VERSION ""

NS_ :

BS_:

BU_: BCM BMS_12V CMS_D CMS_P DSMU ECDO METER MID PBD PSB_D PSB_P PSCU RSCU2R RSCU3R SCCM SRVM VSP

BO_ 1526 HEVC_R110: 8 BCM
  SG_ ME_ElecMachineTempDeg_BLMS : 23|8@0+ (1,-40) [-40|210] "°C" METER
  SG_ ME_InverterTempDeg_BLMS : 31|8@0+ (1,-40) [-40|210] "°C" METER

BO_ 1530 METER_UserSetPref_A3: 8 METER
  SG_ BSWson_ActivationRequest : 5|2@0+ (1,0) [0|0] "" BCM
  SG_ BCI_ActivationRequest : 7|2@0+ (1,0) [0|0] "" BCM
  SG_ HUD_TurnByTurnActivationRequest : 9|2@0+ (1,0) [0|0] "" BCM
  SG_ HUD_ADASactivationRequest : 11|2@0+ (1,0) [0|0] "" BCM
  SG_ HUD_TSRactivationRequest : 13|2@0+ (1,0) [0|0] "" BCM
  SG_ HUD_ITactivationRequest : 15|2@0+ (1,0) [0|0] "" BCM
  SG_ ELKA_ActivationRequest : 18|2@0+ (1,0) [0|0] "" BCM
  SG_ FCW_SensibilityRequest : 26|3@0+ (1,0) [0|0] "" BCM
  SG_ HUD_DayLuminosityRequest : 31|5@0+ (1,0) [0|0] "" BCM
  SG_ SSAactivationRequest : 34|3@0+ (1,0) [0|0] "" BCM
  SG_ HUD_NightLuminosityRequest : 39|5@0+ (1,0) [0|0] "" BCM
  SG_ EAP_ActivationRequest : 41|2@0+ (1,0) [0|0] "" BCM
  SG_ WDA_ActivationRequest : 43|2@0+ (1,0) [0|0] "" BCM
  SG_ ASAactivationRequest : 45|2@0+ (1,0) [0|0] "" BCM
  SG_ ADA1ActivationRequest : 47|2@0+ (1,0) [0|0] "" BCM
  SG_ WAL_ActivationRequest : 49|2@0+ (1,0) [0|0] "" BCM
  SG_ RAB_ActivationRequest : 51|2@0+ (1,0) [0|0] "" BCM
  SG_ NoEntry_ActivationRequest : 53|2@0+ (1,0) [0|0] "" BCM
  SG_ VDCactivationRequest : 55|2@0+ (1,0) [0|0] "" BCM
  SG_ APPRUN_ActivationRequest : 63|2@0+ (1,0) [0|0] "" BCM

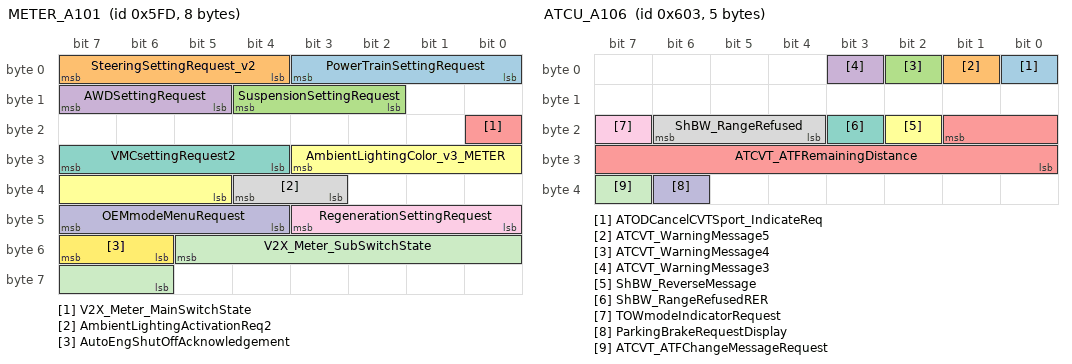
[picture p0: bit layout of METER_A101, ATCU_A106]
BO_ 1533 METER_A101: 8 METER
  SG_ PowerTrainSettingRequest : 3|4@0+ (1,0) [0|0] "" BCM
  SG_ SteeringSettingRequest_v2 : 7|4@0+ (1,0) [0|0] "" BCM
  SG_ SuspensionSettingRequest : 12|3@0+ (1,0) [0|0] "" BCM
  SG_ AWDSettingRequest : 15|3@0+ (1,0) [0|0] "" BCM
  SG_ V2X_Meter_MainSwitchState : 16|1@0+ (1,0) [0|0] "" BCM
  SG_ AmbientLightingColor_v3_METER : 27|7@0+ (1,0) [0|0] "" BCM
  SG_ VMCsettingRequest2 : 31|4@0+ (1,0) [0|0] "" BCM
  SG_ AmbientLightingActivationReq2 : 36|2@0+ (1,0) [0|0] "" BCM
  SG_ RegenerationSettingRequest : 43|4@0+ (1,0) [0|0] "" BCM
  SG_ OEMmodeMenuRequest : 47|4@0+ (1,0) [0|0] "" BCM
  SG_ V2X_Meter_SubSwitchState : 53|8@0+ (1,0) [0|0] "" BCM
  SG_ AutoEngShutOffAcknowledgement : 55|2@0+ (1,0) [0|0] "" BCM

BO_ 1537 ADAS_A119: 8 BCM
  SG_ NoEntry_AlertDisplay : 2|1@0+ (1,0) [0|0] "" METER
  SG_ NoEntry_ActivationState : 3|1@0+ (1,0) [0|0] "" METER
  SG_ ADAS_ModeDisplay : 7|2@0+ (1,0) [0|0] "" METER
  SG_ NoEntry_Alert : 8|1@0+ (1,0) [0|0] "" METER
  SG_ ACC_TargetDistanceAlert : 10|2@0+ (1,0) [0|0] "" METER
  SG_ ACC_DistanceOverrideDisplay : 11|1@0+ (1,0) [0|0] "" METER
  SG_ ACC_SpeedOverrideDisplay : 12|1@0+ (1,0) [0|0] "" METER
  SG_ ACC_TargetDistanceDisplay : 15|3@0+ (1,0) [0|0] "" METER
  SG_ ACC_DynTargetDistanceDisplay : 23|8@0+ (1,0) [0|255] "wu" METER
  SG_ ACC_SpeedSettingDisplay : 31|8@0+ (1,0) [0|255] "wu" METER
  SG_ ACC_DistanceSettingDisplay : 39|3@0+ (1,0) [0|0] "" METER
  SG_ LCA_FailureDisplay : 41|2@0+ (1,0) [0|0] "" METER
  SG_ LCA_OverrideDisplay : 42|1@0+ (1,0) [0|0] "" METER
  SG_ LCA_SteeringWheelDisplay : 46|2@0+ (1,0) [0|0] "" METER
  SG_ LCA_ActivationState : 47|1@0+ (1,0) [0|0] "" METER
  SG_ LDP_StatusDisplay : 49|2@0+ (1,0) [0|0] "" METER
  SG_ LDP_LaneDisplay : 51|2@0+ (1,0) [0|0] "" METER
  SG_ LDP_AlertStatus : 54|2@0+ (1,0) [0|0] "" METER
  SG_ LCA_SoundAlert : 55|1@0+ (1,0) [0|0] "" METER
  SG_ ContextSpeed_ActivationState : 58|2@0+ (1,0) [0|0] "" METER
  SG_ ContextRoad_ActivationState : 60|2@0+ (1,0) [0|0] "" METER
  SG_ DriverGuideDisplay : 63|3@0+ (1,0) [0|0] "" METER

BO_ 1538 ADAS_A120: 8 BCM
  SG_ BCI_AlertStatus_v2 : 0|1@0+ (1,0) [0|0] "" METER
  SG_ BSI_SideDisplay : 8|1@0+ (1,0) [0|0] "" METER
  SG_ BCI_SoundAlert : 9|1@0+ (1,0) [0|0] "" METER
  SG_ BCI_OffdisplayRequest : 10|1@0+ (1,0) [0|0] "" METER
  SG_ BCI_FailureDisplay : 12|2@0+ (1,0) [0|0] "" METER
  SG_ BSI_CancelReason : 18|3@0+ (1,0) [0|0] "" METER
  SG_ LKA_OvertimeAlert : 19|1@0+ (1,0) [0|0] "" METER
  SG_ LDW_AlertStatus : 21|2@0+ (1,0) [0|0] "" METER
  SG_ BSI_AlertStatus : 23|2@0+ (1,0) [0|0] "" METER
  SG_ EAP_FailureDisplay : 25|2@0+ (1,0) [0|0] "" METER
  SG_ EAP_AlertDisplay : 26|1@0+ (1,0) [0|0] "" METER
  SG_ BSI_StatusDisplay : 28|2@0+ (1,0) [0|0] "" METER
  SG_ BSI_SideRadarCancelReason : 31|2@0+ (1,0) [0|0] "" METER
  SG_ LDP_CancelReason : 35|3@0+ (1,0) [0|0] "" METER
  SG_ LCA_LineCrossingAlert : 39|2@0+ (1,0) [0|0] "" METER
  SG_ RAB_CancelReason : 42|3@0+ (1,0) [0|0] "" METER
  SG_ RAB_AlertStatus : 44|2@0+ (1,0) [0|0] "" METER
  SG_ RAB_ActivationState : 45|1@0+ (1,0) [0|0] "" METER
  SG_ LDP_FailureDisplay : 47|2@0+ (1,0) [0|0] "" METER
  SG_ WDA_WarningDriverAttention : 48|1@0+ (1,0) [0|0] "" METER
  SG_ WDA_ActivationState : 49|1@0+ (1,0) [0|0] "" METER
  SG_ RAB_StatusDisplay : 51|2@0+ (1,0) [0|0] "" METER
  SG_ RAB_SonarCancelReason : 53|2@0+ (1,0) [0|0] "" METER
  SG_ RAB_FailureDisplay : 55|2@0+ (1,0) [0|0] "" METER
  SG_ ACC_TransitionStateDisplay : 59|4@0+ (1,0) [0|0] "" METER
  SG_ WDA_DriverAttentionLevel : 63|4@0+ (1,0) [0|0] "" METER

BO_ 1539 ATCU_A106: 5 BCM
  SG_ ATODCancelCVTSport_IndicateReq : 0|1@0+ (1,0) [0|0] "" METER
  SG_ ATCVT_WarningMessage5 : 1|1@0+ (1,0) [0|0] "" METER
  SG_ ATCVT_WarningMessage4 : 2|1@0+ (1,0) [0|0] "" METER
  SG_ ATCVT_WarningMessage3 : 3|1@0+ (1,0) [0|0] "" METER
  SG_ ATCVT_ATFRemainingDistance : 17|10@0+ (5,0) [0|5110] "km" METER
  SG_ ShBW_ReverseMessage : 18|1@0+ (1,0) [0|0] "" METER
  SG_ ShBW_RangeRefusedRER : 19|1@0+ (1,0) [0|0] "" METER
  SG_ ShBW_RangeRefused : 22|3@0+ (1,0) [0|0] "" METER
  SG_ TOWmodeIndicatorRequest : 23|1@0+ (1,0) [0|0] "" METER
  SG_ ParkingBrakeRequestDisplay : 38|1@0+ (1,0) [0|0] "" METER
  SG_ ATCVT_ATFChangeMessageRequest : 39|1@0+ (1,0) [0|0] "" METER

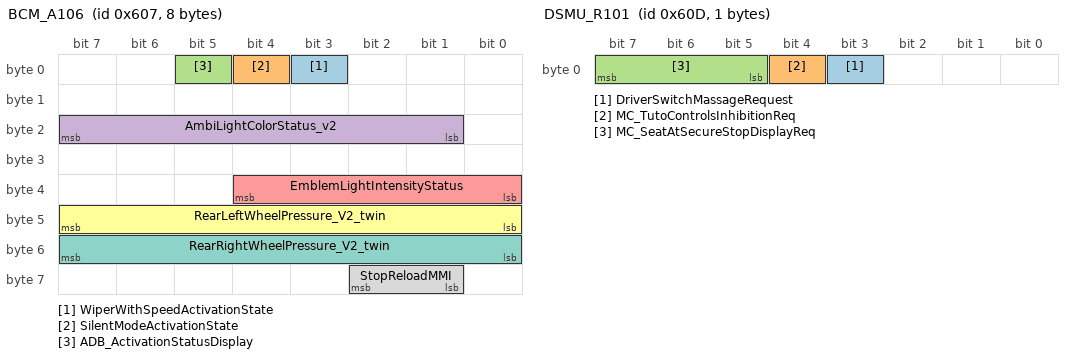
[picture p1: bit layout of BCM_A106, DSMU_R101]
BO_ 1543 BCM_A106: 8 BCM
  SG_ WiperWithSpeedActivationState : 3|1@0+ (1,0) [0|0] "" METER
  SG_ SilentModeActivationState : 4|1@0+ (1,0) [0|0] "" METER,PBD
  SG_ ADB_ActivationStatusDisplay : 5|1@0+ (1,0) [0|0] "" METER
  SG_ AmbiLightColorStatus_v2 : 23|7@0+ (1,0) [0|0] "" METER
  SG_ EmblemLightIntensityStatus : 36|5@0+ (5,0) [0|100] "%" METER
  SG_ RearLeftWheelPressure_V2_twin : 47|8@0+ (30,0) [0|7620] "mbar" METER
  SG_ RearRightWheelPressure_V2_twin : 55|8@0+ (30,0) [0|7620] "mbar" METER
  SG_ StopReloadMMI : 58|2@0+ (1,0) [0|0] "" METER

BO_ 1548 EVAP_A2: 5 BCM
  SG_ FuelLidStatus : 1|1@0+ (1,0) [0|0] "" METER
  SG_ RefuelingDisplay : 36|3@0+ (1,0) [0|0] "" METER

BO_ 1549 DSMU_R101: 1 DSMU
  SG_ DriverSwitchMassageRequest : 3|1@0+ (1,0) [0|0] "" BCM
  SG_ MC_TutoControlsInhibitionReq : 4|1@0+ (1,0) [0|0] "" BCM
  SG_ MC_SeatAtSecureStopDisplayReq : 7|3@0+ (1,0) [0|0] "" BCM

BO_ 1553 HVAC_A106: 8 BCM
  SG_ ClimEVmodeAdviceForHeating : 5|3@0+ (1,0) [0|0] "" METER

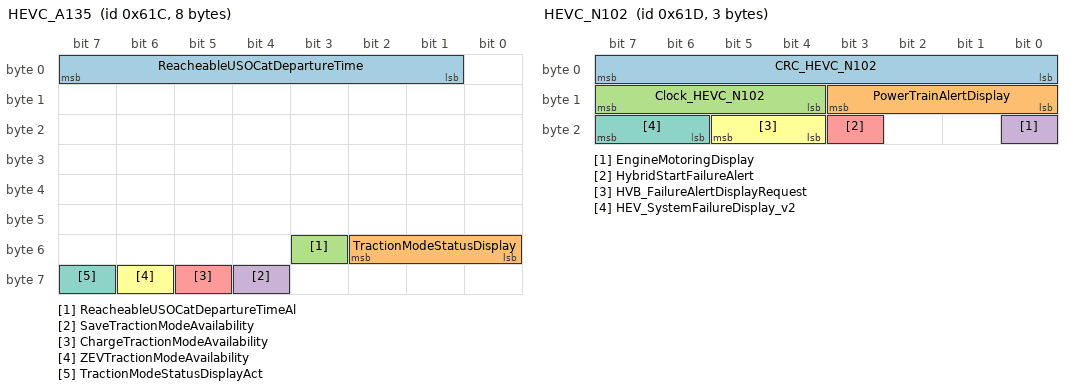
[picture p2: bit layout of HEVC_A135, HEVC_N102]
BO_ 1564 HEVC_A135: 8 BCM
  SG_ ReacheableUSOCatDepartureTime : 7|7@0+ (1,0) [0|100] "%" METER
  SG_ TractionModeStatusDisplay : 50|3@0+ (1,0) [0|0] "" METER
  SG_ ReacheableUSOCatDepartureTimeAl : 51|1@0+ (1,0) [0|0] "" METER
  SG_ SaveTractionModeAvailability : 60|1@0+ (1,0) [0|0] "" METER
  SG_ ChargeTractionModeAvailability : 61|1@0+ (1,0) [0|0] "" METER
  SG_ ZEVTractionModeAvailability : 62|1@0+ (1,0) [0|0] "" METER
  SG_ TractionModeStatusDisplayAct : 63|1@0+ (1,0) [0|0] "" METER

BO_ 1565 HEVC_N102: 3 BCM
  SG_ CRC_HEVC_N102 : 7|8@0+ (1,0) [0|255] "" METER
  SG_ PowerTrainAlertDisplay : 11|4@0+ (1,0) [0|0] "" METER
  SG_ Clock_HEVC_N102 : 15|4@0+ (1,0) [0|15] "" METER
  SG_ EngineMotoringDisplay : 16|1@0+ (1,0) [0|0] "" METER
  SG_ HybridStartFailureAlert : 19|1@0+ (1,0) [0|0] "" METER
  SG_ HVB_FailureAlertDisplayRequest : 21|2@0+ (1,0) [0|0] "" METER
  SG_ HEV_SystemFailureDisplay_v2 : 23|2@0+ (1,0) [0|0] "" METER

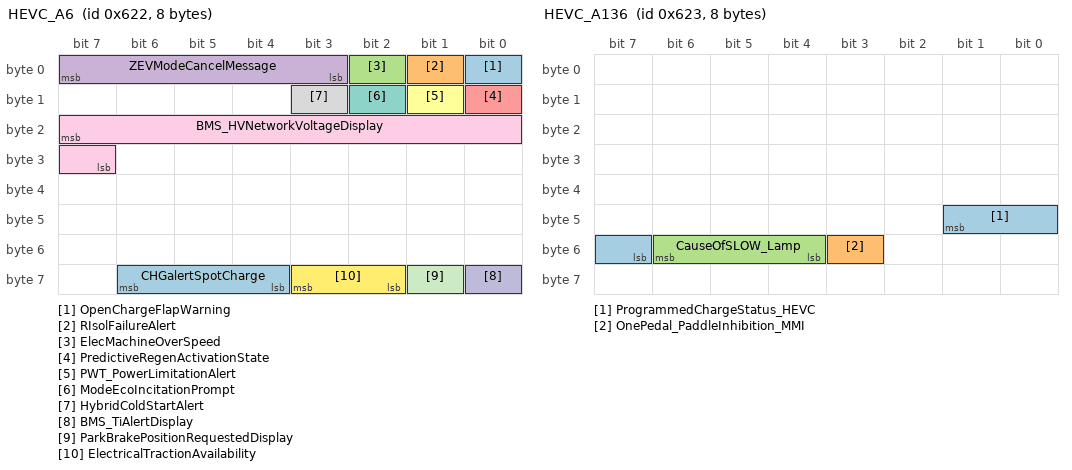
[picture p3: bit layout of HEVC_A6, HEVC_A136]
BO_ 1570 HEVC_A6: 8 BCM
  SG_ OpenChargeFlapWarning : 0|1@0+ (1,0) [0|0] "" METER
  SG_ RIsolFailureAlert : 1|1@0+ (1,0) [0|0] "" METER
  SG_ ElecMachineOverSpeed : 2|1@0+ (1,0) [0|0] "" METER
  SG_ ZEVModeCancelMessage : 7|5@0+ (1,0) [0|0] "" METER
  SG_ PredictiveRegenActivationState : 8|1@0+ (1,0) [0|0] "" METER
  SG_ PWT_PowerLimitationAlert : 9|1@0+ (1,0) [0|0] "" METER
  SG_ ModeEcoIncitationPrompt : 10|1@0+ (1,0) [0|0] "" METER
  SG_ HybridColdStartAlert : 11|1@0+ (1,0) [0|0] "" METER
  SG_ BMS_HVNetworkVoltageDisplay : 23|9@0+ (1,0) [0|500] "V" METER
  SG_ BMS_TiAlertDisplay : 56|1@0+ (1,0) [0|0] "" METER
  SG_ ParkBrakePositionRequestedDisplay : 57|1@0+ (1,0) [0|0] "" METER
  SG_ ElectricalTractionAvailability : 59|2@0+ (1,0) [0|0] "" METER
  SG_ CHGalertSpotCharge : 62|3@0+ (1,0) [0|0] "" METER

BO_ 1571 HEVC_A136: 8 BCM
  SG_ ProgrammedChargeStatus_HEVC : 41|3@0+ (1,0) [0|0] "" METER
  SG_ OnePedal_PaddleInhibition_MMI : 51|1@0+ (1,0) [0|0] "" METER
  SG_ CauseOfSLOW_Lamp : 54|3@0+ (1,0) [0|0] "" METER

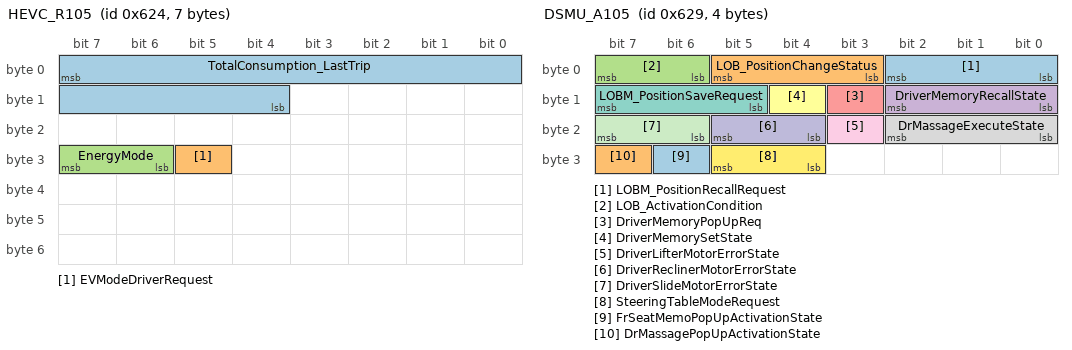
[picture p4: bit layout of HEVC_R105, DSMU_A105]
BO_ 1572 HEVC_R105: 7 BCM
  SG_ TotalConsumption_LastTrip : 7|12@0+ (0.1,0) [0|409.4] "kWh" METER
  SG_ EVModeDriverRequest : 29|1@0+ (1,0) [0|0] "" METER
  SG_ EnergyMode : 31|2@0+ (1,0) [0|0] "" METER

BO_ 1577 DSMU_A105: 4 DSMU
  SG_ LOBM_PositionRecallRequest : 2|3@0+ (1,0) [0|0] "" SCCM
  SG_ LOB_PositionChangeStatus : 5|3@0+ (1,0) [0|0] "" BCM
  SG_ LOB_ActivationCondition : 7|2@0+ (1,0) [0|0] "" BCM
  SG_ DriverMemoryRecallState : 10|3@0+ (1,0) [0|0] "" BCM
  SG_ DriverMemoryPopUpReq : 11|1@0+ (1,0) [0|0] "" BCM
  SG_ DriverMemorySetState : 12|1@0+ (1,0) [0|0] "" BCM
  SG_ LOBM_PositionSaveRequest : 15|3@0+ (1,0) [0|0] "" SCCM
  SG_ DrMassageExecuteState : 18|3@0+ (1,0) [0|0] "" BCM
  SG_ DriverLifterMotorErrorState : 19|1@0+ (1,0) [0|0] "" BCM
  SG_ DriverReclinerMotorErrorState : 21|2@0+ (1,0) [0|0] "" BCM
  SG_ DriverSlideMotorErrorState : 23|2@0+ (1,0) [0|0] "" BCM
  SG_ SteeringTableModeRequest : 29|2@0+ (1,0) [0|0] "" SCCM
  SG_ FrSeatMemoPopUpActivationState : 30|1@0+ (1,0) [0|0] "" BCM,PSCU
  SG_ DrMassagePopUpActivationState : 31|1@0+ (1,0) [0|0] "" BCM

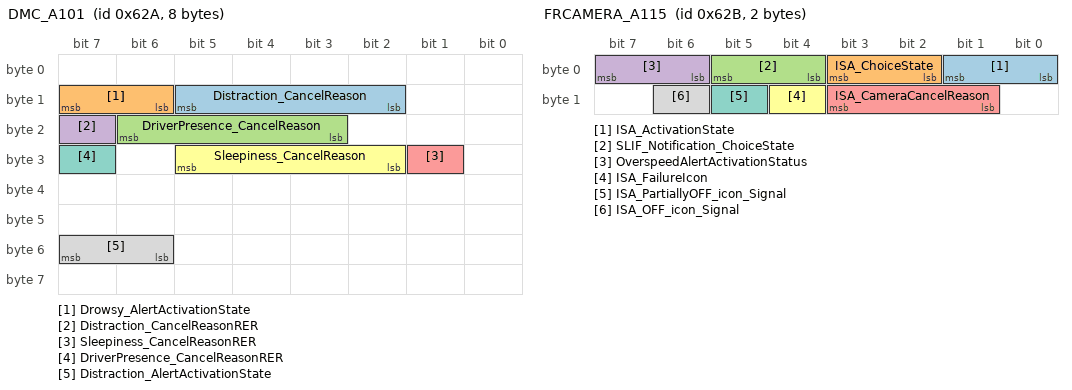
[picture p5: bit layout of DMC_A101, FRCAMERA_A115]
BO_ 1578 DMC_A101: 8 BCM
  SG_ Distraction_CancelReason : 13|4@0+ (1,0) [0|0] "" METER
  SG_ Drowsy_AlertActivationState : 15|2@0+ (1,0) [0|0] "" METER
  SG_ DriverPresence_CancelReason : 22|4@0+ (1,0) [0|0] "" METER
  SG_ Distraction_CancelReasonRER : 23|1@0+ (1,0) [0|0] "" METER
  SG_ Sleepiness_CancelReasonRER : 25|1@0+ (1,0) [0|0] "" METER
  SG_ Sleepiness_CancelReason : 29|4@0+ (1,0) [0|0] "" METER
  SG_ DriverPresence_CancelReasonRER : 31|1@0+ (1,0) [0|0] "" METER
  SG_ Distraction_AlertActivationState : 55|2@0+ (1,0) [0|0] "" METER

BO_ 1579 FRCAMERA_A115: 2 BCM
  SG_ ISA_ActivationState : 1|2@0+ (1,0) [0|0] "" METER
  SG_ ISA_ChoiceState : 3|2@0+ (1,0) [0|0] "" METER
  SG_ SLIF_Notification_ChoiceState : 5|2@0+ (1,0) [0|0] "" METER
  SG_ OverspeedAlertActivationStatus : 7|2@0+ (1,0) [0|0] "" METER
  SG_ ISA_CameraCancelReason : 11|3@0+ (1,0) [0|0] "" METER
  SG_ ISA_FailureIcon : 12|1@0+ (1,0) [0|0] "" METER
  SG_ ISA_PartiallyOFF_icon_Signal : 13|1@0+ (1,0) [0|0] "" METER
  SG_ ISA_OFF_icon_Signal : 14|1@0+ (1,0) [0|0] "" METER

BO_ 1583 ANC_A101: 3 BCM
  SG_ ASE_SoundActivationStatus : 20|2@0+ (1,0) [0|0] "" METER
  SG_ ASE_SoundvolumeState : 23|3@0+ (1,0) [0|0] "" METER

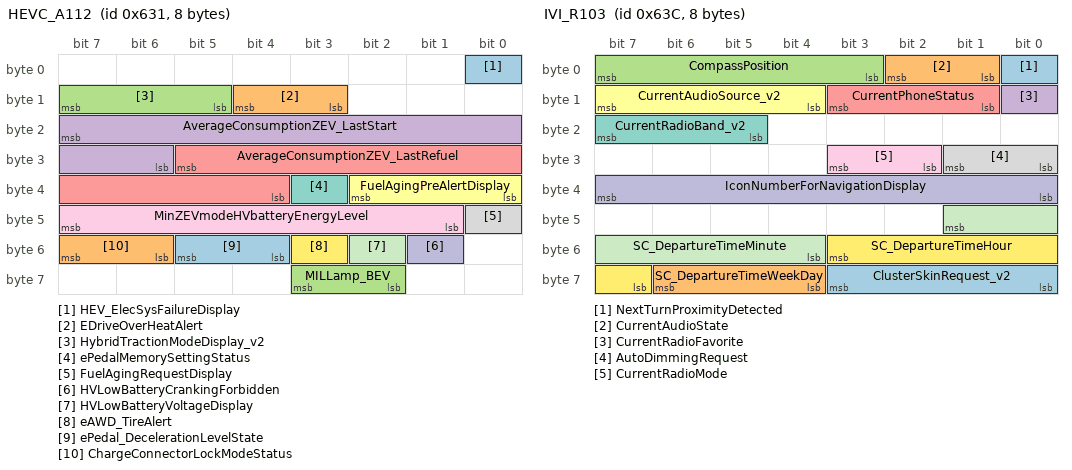
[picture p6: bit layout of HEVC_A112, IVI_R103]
BO_ 1585 HEVC_A112: 8 BCM
  SG_ HEV_ElecSysFailureDisplay : 0|1@0+ (1,0) [0|0] "" METER
  SG_ EDriveOverHeatAlert : 12|2@0+ (1,0) [0|0] "" METER
  SG_ HybridTractionModeDisplay_v2 : 15|3@0+ (1,0) [0|0] "" METER
  SG_ AverageConsumptionZEV_LastStart : 23|10@0+ (0.1,0) [0|102.2] "-" METER
  SG_ AverageConsumptionZEV_LastRefuel : 29|10@0+ (0.1,0) [0|102.2] "" METER
  SG_ FuelAgingPreAlertDisplay : 34|3@0+ (1,0) [0|0] "" METER
  SG_ ePedalMemorySettingStatus : 35|1@0+ (1,0) [0|0] "" METER
  SG_ FuelAgingRequestDisplay : 40|1@0+ (1,0) [0|0] "" METER
  SG_ MinZEVmodeHVbatteryEnergyLevel : 47|7@0+ (1,0) [0|100] "%" METER
  SG_ HVLowBatteryCrankingForbidden : 49|1@0+ (1,0) [0|0] "" METER
  SG_ HVLowBatteryVoltageDisplay : 50|1@0+ (1,0) [0|0] "" METER
  SG_ eAWD_TireAlert : 51|1@0+ (1,0) [0|0] "" METER
  SG_ ePedal_DecelerationLevelState : 53|2@0+ (1,0) [0|0] "" METER
  SG_ ChargeConnectorLockModeStatus : 55|2@0+ (1,0) [0|0] "" METER
  SG_ MILLamp_BEV : 59|2@0+ (1,0) [0|0] "" METER

BO_ 1592 HVAC_A107: 8 BCM
  SG_ eAC_RevCapStatus : 41|2@0+ (1,0) [0|0] "" METER

BO_ 1595 IVI_A114: 8 BCM
  SG_ RearViewRVC_CancelReason_RER : 50|1@0+ (1,0) [0|0] "" METER
  SG_ RearViewRVC_CancelReason : 54|2@0+ (1,0) [0|0] "" METER

BO_ 1596 IVI_R103: 8 BCM
  SG_ NextTurnProximityDetected : 0|1@0+ (1,0) [0|0] "" METER
  SG_ CurrentAudioState : 2|2@0+ (1,0) [0|0] "" METER
  SG_ CompassPosition : 7|5@0+ (1,0) [0|31] "wu" METER
  SG_ CurrentRadioFavorite : 8|1@0+ (1,0) [0|0] "" METER
  SG_ CurrentPhoneStatus : 11|3@0+ (1,0) [0|0] "" METER
  SG_ CurrentAudioSource_v2 : 15|4@0+ (1,0) [0|0] "" METER
  SG_ CurrentRadioBand_v2 : 23|3@0+ (1,0) [0|0] "" METER
  SG_ AutoDimmingRequest : 25|2@0+ (1,0) [0|0] "" METER
  SG_ CurrentRadioMode : 27|2@0+ (1,0) [0|0] "" METER
  SG_ IconNumberForNavigationDisplay : 39|8@0+ (1,0) [0|255] "wu" METER
  SG_ SC_DepartureTimeMinute : 41|6@0+ (1,0) [0|59] "min" METER
  SG_ SC_DepartureTimeHour : 51|5@0+ (1,0) [0|23] "h" METER
  SG_ ClusterSkinRequest_v2 : 59|4@0+ (1,0) [0|0] "" METER
  SG_ SC_DepartureTimeWeekDay : 62|3@0+ (1,0) [0|0] "" METER

BO_ 1599 SRRR_A107: 1 BCM
  SG_ CTA_ActivationState : 7|1@0+ (1,0) [0|0] "" METER

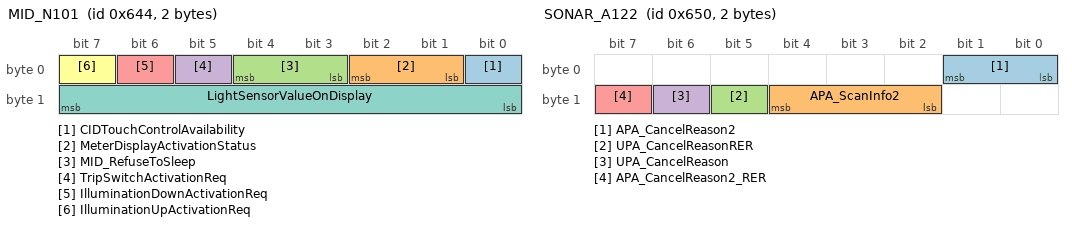
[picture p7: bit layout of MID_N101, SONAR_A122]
BO_ 1604 MID_N101: 2 MID
  SG_ CIDTouchControlAvailability : 0|1@0+ (1,0) [0|0] "" METER
  SG_ MeterDisplayActivationStatus : 2|2@0+ (1,0) [0|0] "" METER
  SG_ MID_RefuseToSleep : 4|2@0+ (1,0) [0|0] "" BCM
  SG_ TripSwitchActivationReq : 5|1@0+ (1,0) [0|0] "" METER
  SG_ IlluminationDownActivationReq : 6|1@0+ (1,0) [0|0] "" METER
  SG_ IlluminationUpActivationReq : 7|1@0+ (1,0) [0|0] "" METER
  SG_ LightSensorValueOnDisplay : 15|8@0+ (0.4,0) [0|100] "%" METER

BO_ 1614 IVI_A129: 8 BCM
  SG_ RearLeftLumbarMovingReq_X_Axis : 8|2@0+ (1,0) [0|0] "" RSCU2R
  SG_ RearLeftFrontHeightMovingReq : 10|2@0+ (1,0) [0|0] "" RSCU2R
  SG_ RearLeftMassageProgramReq : 17|4@0+ (1,0) [0|0] "" RSCU2R
  SG_ RearLeftMassageIntensityReq : 20|3@0+ (1,0) [0|0] "" RSCU2R
  SG_ RearLeftLumbarMovingReq_Z_Axis : 22|2@0+ (1,0) [0|0] "" RSCU2R
  SG_ RearLeftReclinerMovingReq : 24|2@0+ (1,0) [0|0] "" RSCU2R
  SG_ RearLeftOttomanMovingReq : 26|2@0+ (1,0) [0|0] "" RSCU2R
  SG_ RearLeftMassageVelocityReq : 29|3@0+ (1,0) [0|0] "" RSCU2R
  SG_ RearRightLumbarMovingReq_X_Axis : 32|2@0+ (1,0) [0|0] "" RSCU2R
  SG_ RearRightFrontHeightMovingReq : 34|2@0+ (1,0) [0|0] "" RSCU2R
  SG_ RearLeftUpperbackrestMovingReq : 36|2@0+ (1,0) [0|0] "" RSCU2R
  SG_ RearLeftSlideMovingReq : 38|2@0+ (1,0) [0|0] "" RSCU2R
  SG_ RearRightMassageProgramReq : 41|4@0+ (1,0) [0|0] "" RSCU2R
  SG_ RearRightMassageIntensityReq : 44|3@0+ (1,0) [0|0] "" RSCU2R
  SG_ RearRightLumbarMovingReq_Z_Axis : 46|2@0+ (1,0) [0|0] "" RSCU2R
  SG_ RearRightReclinerMovingReq : 48|2@0+ (1,0) [0|0] "" RSCU2R
  SG_ RearRightOttomanMovingReq : 50|2@0+ (1,0) [0|0] "" RSCU2R
  SG_ RearRightMassageVelocityReq : 53|3@0+ (1,0) [0|0] "" RSCU2R
  SG_ RearRightUpperbackrestMovingReq : 60|2@0+ (1,0) [0|0] "" RSCU2R
  SG_ RearRightSlideMovingReq : 62|2@0+ (1,0) [0|0] "" RSCU2R

BO_ 1616 SONAR_A122: 2 BCM
  SG_ APA_CancelReason2 : 1|2@0+ (1,0) [0|0] "" METER
  SG_ APA_ScanInfo2 : 12|3@0+ (1,0) [0|0] "" METER
  SG_ UPA_CancelReasonRER : 13|1@0+ (1,0) [0|0] "" METER
  SG_ UPA_CancelReason : 14|1@0+ (1,0) [0|0] "" METER
  SG_ APA_CancelReason2_RER : 15|1@0+ (1,0) [0|0] "" METER

BO_ 1620 HEVC_A37: 8 BCM
  SG_ FreeDistanceZEVSinceECOreset : 15|13@0+ (0.1,0) [0|800] "wu" METER

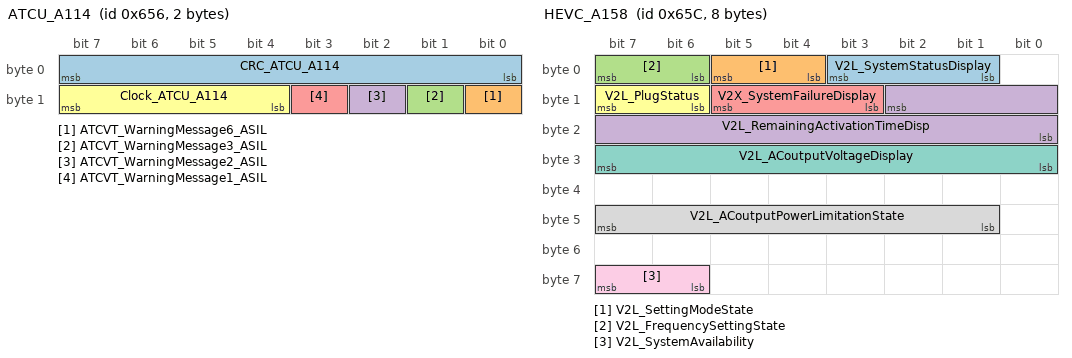
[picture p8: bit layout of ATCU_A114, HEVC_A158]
BO_ 1622 ATCU_A114: 2 BCM
  SG_ CRC_ATCU_A114 : 7|8@0+ (1,0) [0|255] "" METER
  SG_ ATCVT_WarningMessage6_ASIL : 8|1@0+ (1,0) [0|0] "" METER
  SG_ ATCVT_WarningMessage3_ASIL : 9|1@0+ (1,0) [0|0] "" METER
  SG_ ATCVT_WarningMessage2_ASIL : 10|1@0+ (1,0) [0|0] "" METER
  SG_ ATCVT_WarningMessage1_ASIL : 11|1@0+ (1,0) [0|0] "" METER
  SG_ Clock_ATCU_A114 : 15|4@0+ (1,0) [0|15] "" METER

BO_ 1626 ADB_A1: 1 BCM
  SG_ ADB_FailureDisplay : 5|1@0+ (1,0) [0|0] "" METER

BO_ 1628 HEVC_A158: 8 BCM
  SG_ V2L_SystemStatusDisplay : 3|3@0+ (1,0) [0|0] "" METER
  SG_ V2L_SettingModeState : 5|2@0+ (1,0) [0|0] "" METER
  SG_ V2L_FrequencySettingState : 7|2@0+ (1,0) [0|0] "" METER
  SG_ V2L_RemainingActivationTimeDisp : 10|11@0+ (1,0) [0|2046] "min" METER
  SG_ V2X_SystemFailureDisplay : 13|3@0+ (1,0) [0|0] "" METER
  SG_ V2L_PlugStatus : 15|2@0+ (1,0) [0|0] "" METER
  SG_ V2L_ACoutputVoltageDisplay : 31|8@0+ (2,0) [0|500] "V" METER
  SG_ V2L_ACoutputPowerLimitationState : 47|7@0+ (0.1,0) [0|10] "kW" METER
  SG_ V2L_SystemAvailability : 63|2@0+ (1,0) [0|0] "" METER

BO_ 1634 VDC_R14: 6 BCM
  SG_ LateralTilt_MMI : 7|7@0+ (1,-60) [-60|60] "°" METER
  SG_ LongitudinalTilt_MMI : 15|7@0+ (1,-60) [-60|60] "°" METER

BO_ 1635 HEVC_A162: 6 BCM
  SG_ V2Li_AlertsDisplay : 2|3@0+ (1,0) [0|0] "" METER
  SG_ V2X_HVBat_EnergyDurabilityCount : 23|15@0+ (5,0) [0|150000] "KWh" METER

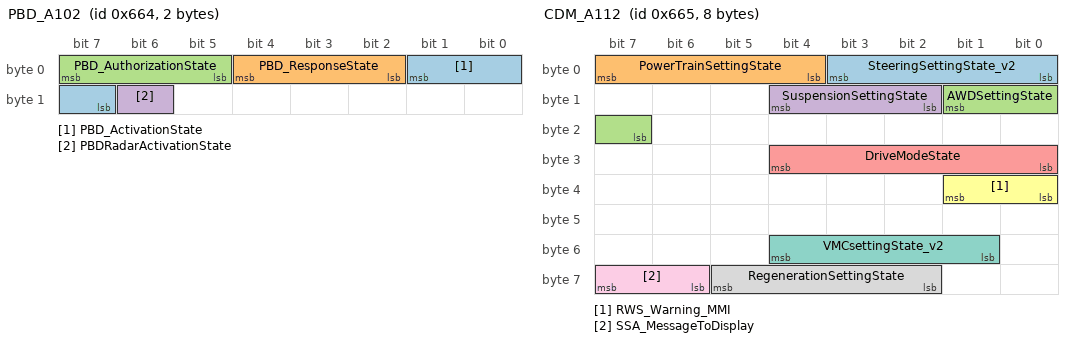
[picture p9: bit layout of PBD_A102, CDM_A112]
BO_ 1636 PBD_A102: 2 PBD
  SG_ PBD_ActivationState : 1|3@0+ (1,0) [0|0] "" BCM
  SG_ PBD_ResponseState : 4|3@0+ (1,0) [0|0] "" BCM
  SG_ PBD_AuthorizationState : 7|3@0+ (1,0) [0|0] "" BCM
  SG_ PBDRadarActivationState : 14|1@0+ (1,0) [0|0] "" METER

BO_ 1637 CDM_A112: 8 BCM
  SG_ SteeringSettingState_v2 : 3|4@0+ (1,0) [0|0] "" METER
  SG_ PowerTrainSettingState : 7|4@0+ (1,0) [0|0] "" METER
  SG_ AWDSettingState : 9|3@0+ (1,0) [0|0] "" METER
  SG_ SuspensionSettingState : 12|3@0+ (1,0) [0|0] "" METER
  SG_ DriveModeState : 28|5@0+ (1,0) [0|0] "" METER
  SG_ RWS_Warning_MMI : 33|2@0+ (1,0) [0|0] "" METER
  SG_ VMCsettingState_v2 : 52|4@0+ (1,0) [0|0] "" METER
  SG_ RegenerationSettingState : 61|4@0+ (1,0) [0|0] "" METER
  SG_ SSA_MessageToDisplay : 63|2@0+ (1,0) [0|0] "" METER

BO_ 1640 HEVC_A114: 8 BCM
  SG_ ePedalReemissionRequest : 56|1@0+ (1,0) [0|0] "" METER

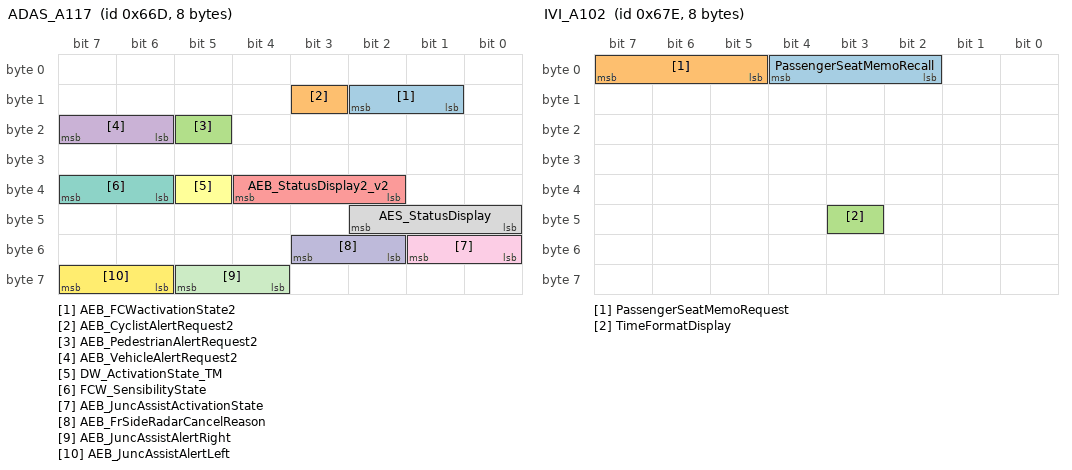
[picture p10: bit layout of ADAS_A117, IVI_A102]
BO_ 1645 ADAS_A117: 8 BCM
  SG_ AEB_FCWactivationState2 : 10|2@0+ (1,0) [0|0] "" METER
  SG_ AEB_CyclistAlertRequest2 : 11|1@0+ (1,0) [0|0] "" METER
  SG_ AEB_PedestrianAlertRequest2 : 21|1@0+ (1,0) [0|0] "" METER
  SG_ AEB_VehicleAlertRequest2 : 23|2@0+ (1,0) [0|0] "" METER
  SG_ AEB_StatusDisplay2_v2 : 36|3@0+ (1,0) [0|0] "" METER
  SG_ DW_ActivationState_TM : 37|1@0+ (1,0) [0|0] "" METER
  SG_ FCW_SensibilityState : 39|2@0+ (1,0) [0|0] "" METER
  SG_ AES_StatusDisplay : 42|3@0+ (1,0) [0|0] "" METER
  SG_ AEB_JuncAssistActivationState : 49|2@0+ (1,0) [0|0] "" METER
  SG_ AEB_FrSideRadarCancelReason : 51|2@0+ (1,0) [0|0] "" METER
  SG_ AEB_JuncAssistAlertRight : 61|2@0+ (1,0) [0|0] "" METER
  SG_ AEB_JuncAssistAlertLeft : 63|2@0+ (1,0) [0|0] "" METER

BO_ 1648 METER_N101: 8 METER
  SG_ SelectedTrailerType : 3|4@0+ (1,0) [0|0] "" BCM
  SG_ SelectedTrailerNumber : 7|4@0+ (1,0) [0|0] "" BCM
  SG_ VideoType_Meter : 9|2@0+ (1,0) [0|0] "" MID
  SG_ TrailerNumberSettingChange : 13|4@0+ (1,0) [0|0] "" BCM
  SG_ TrailerBSWActivationRequest : 15|2@0+ (1,0) [0|0] "" BCM
  SG_ SWS_SelectionStatus : 16|1@0+ (1,0) [0|0] "" BCM
  SG_ TrailerLengthChangeRequest : 23|7@0+ (0.25,0) [0.25|31.25] "m" BCM
  SG_ LDW_Sensibility_ChoiceRequest : 26|3@0+ (1,0) [0|0] "" BCM
  SG_ TrailerWidthChangeRequest : 31|5@0+ (0.25,0) [0.25|7.25] "m" BCM
  SG_ LaneSupport_ChoiceRequest : 33|2@0+ (1,0) [0|0] "" BCM
  SG_ LaneSupport_ActivationRequest : 35|2@0+ (1,0) [0|0] "" BCM
  SG_ SLIF_Notification_ChoiceRequest : 37|2@0+ (1,0) [0|0] "" BCM
  SG_ RAB_ChoiceRequest : 39|2@0+ (1,0) [0|0] "" BCM
  SG_ eHBox_USBInstall_InsertedRequest : 40|1@0+ (1,0) [0|0] "" BCM
  SG_ eHBox_USB_WritabilityRequest : 43|2@0+ (1,0) [0|0] "" BCM
  SG_ eHBox_USBSave_InsertedRequest : 44|1@0+ (1,0) [0|0] "" BCM
  SG_ eHBox_Current_Map_versionRequest : 47|1@0+ (1,0) [0|0] "" BCM
  SG_ ISA_ActivationRequest : 50|3@0+ (1,0) [0|0] "" BCM
  SG_ CPDCheckAcknowledgement : 56|1@0+ (1,0) [0|0] "" BCM
  SG_ eHBox_USB_MapInstallRequest : 60|2@0+ (1,0) [0|0] "" BCM
  SG_ ISA_ChoiceRequest : 63|3@0+ (1,0) [0|0] "" BCM

BO_ 1652 VSP_A1: 1 VSP
  SG_ VSPstatusDisplay : 7|1@0+ (1,0) [0|0] "" METER

BO_ 1657 SRRR_A134: 1 BCM
  SG_ BSWrad_CancelReasonRER : 5|1@0+ (1,0) [0|0] "" METER
  SG_ BSWRad_CancelReason_v2 : 7|2@0+ (1,0) [0|0] "" METER

BO_ 1659 HFM_A102: 5 BCM
  SG_ UserIdentification_IKeyLink : 7|3@0+ (1,0) [0|0] "" CMS_D,CMS_P,DSMU,METER

BO_ 1662 IVI_A102: 8 BCM
  SG_ PassengerSeatMemoRecall : 4|3@0+ (1,0) [0|0] "" PSCU
  SG_ PassengerSeatMemoRequest : 7|3@0+ (1,0) [0|0] "" PSCU
  SG_ TimeFormatDisplay : 43|1@0+ (1,0) [0|0] "" METER

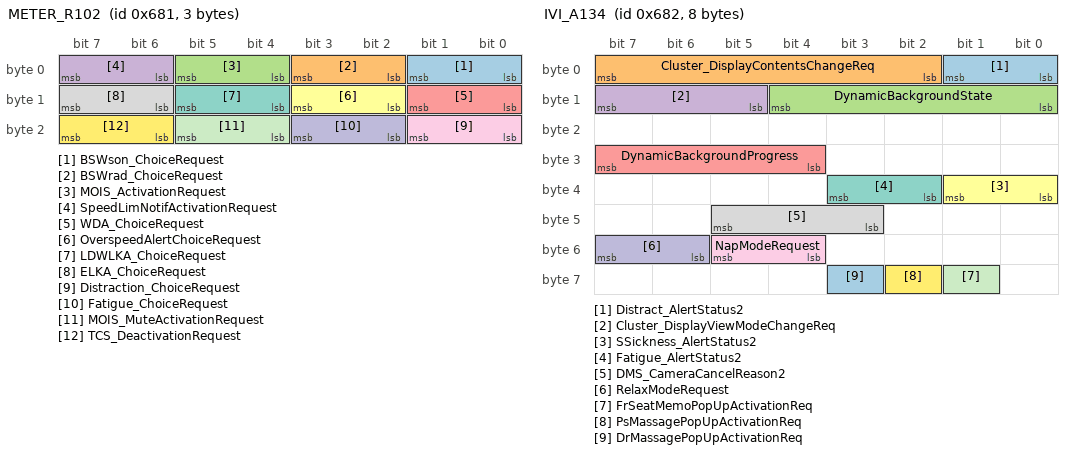
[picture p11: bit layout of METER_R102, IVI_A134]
BO_ 1665 METER_R102: 3 METER
  SG_ BSWson_ChoiceRequest : 1|2@0+ (1,0) [0|0] "" BCM
  SG_ BSWrad_ChoiceRequest : 3|2@0+ (1,0) [0|0] "" BCM
  SG_ MOIS_ActivationRequest : 5|2@0+ (1,0) [0|0] "" BCM
  SG_ SpeedLimNotifActivationRequest : 7|2@0+ (1,0) [0|0] "" BCM
  SG_ WDA_ChoiceRequest : 9|2@0+ (1,0) [0|0] "" BCM
  SG_ OverspeedAlertChoiceRequest : 11|2@0+ (1,0) [0|0] "" BCM
  SG_ LDWLKA_ChoiceRequest : 13|2@0+ (1,0) [0|0] "" BCM
  SG_ ELKA_ChoiceRequest : 15|2@0+ (1,0) [0|0] "" BCM
  SG_ Distraction_ChoiceRequest : 17|2@0+ (1,0) [0|0] "" BCM
  SG_ Fatigue_ChoiceRequest : 19|2@0+ (1,0) [0|0] "" BCM
  SG_ MOIS_MuteActivationRequest : 21|2@0+ (1,0) [0|0] "" BCM
  SG_ TCS_DeactivationRequest : 23|2@0+ (1,0) [0|0] "" BCM

BO_ 1666 IVI_A134: 8 BCM
  SG_ Distract_AlertStatus2 : 1|2@0+ (1,0) [0|0] "" METER
  SG_ Cluster_DisplayContentsChangeReq : 7|6@0+ (1,0) [0|0] "" METER
  SG_ DynamicBackgroundState : 12|5@0+ (1,0) [0|0] "" METER
  SG_ Cluster_DisplayViewModeChangeReq : 15|3@0+ (1,0) [0|0] "" METER
  SG_ DynamicBackgroundProgress : 31|4@0+ (1,0) [0|0] "" METER
  SG_ SSickness_AlertStatus2 : 33|2@0+ (1,0) [0|0] "" METER
  SG_ Fatigue_AlertStatus2 : 35|2@0+ (1,0) [0|0] "" METER
  SG_ DMS_CameraCancelReason2 : 45|3@0+ (1,0) [0|0] "" METER
  SG_ NapModeRequest : 53|2@0+ (1,0) [0|0] "" DSMU,PSCU
  SG_ RelaxModeRequest : 55|2@0+ (1,0) [0|0] "" DSMU,PSCU
  SG_ FrSeatMemoPopUpActivationReq : 57|1@0+ (1,0) [0|0] "" DSMU
  SG_ PsMassagePopUpActivationReq : 58|1@0+ (1,0) [0|0] "" PSCU
  SG_ DrMassagePopUpActivationReq : 59|1@0+ (1,0) [0|0] "" DSMU

BO_ 1670 IVI_A130: 8 BCM
  SG_ LOB_PositionSaveRequest : 50|3@0+ (1,0) [0|0] "" DSMU
  SG_ LOB_PositionRecallRequest : 53|3@0+ (1,0) [0|0] "" DSMU

BO_ 1672 PBD_WakeUpFrame: 2 PBD
  SG_ PBD_WakeUp_Signal : 7|16@0+ (1,0) [0|0] "" BCM

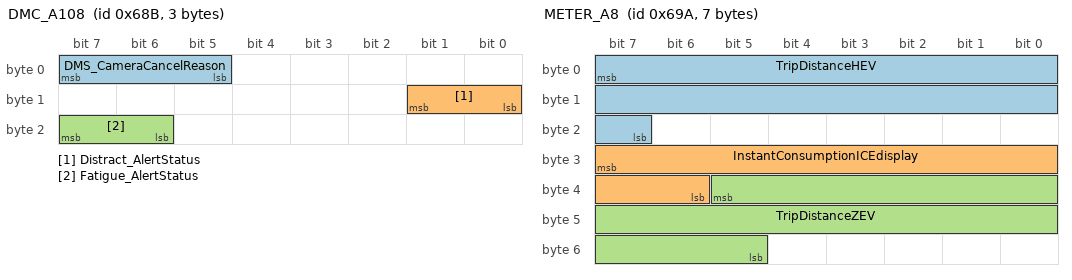
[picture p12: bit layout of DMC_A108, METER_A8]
BO_ 1675 DMC_A108: 3 BCM
  SG_ DMS_CameraCancelReason : 7|3@0+ (1,0) [0|0] "" METER
  SG_ Distract_AlertStatus : 9|2@0+ (1,0) [0|0] "" METER
  SG_ Fatigue_AlertStatus : 23|2@0+ (1,0) [0|0] "" METER

BO_ 1679 ADP_A1: 1 DSMU
  SG_ SeatMemoAlertRequest : 7|1@0+ (1,0) [0|0] "" METER

BO_ 1682 HVAC_A6: 2 BCM
  SG_ HVAC_PresoakStateDisplay : 15|2@0+ (1,0) [0|0] "" METER

BO_ 1684 AVM_A118: 3 BCM
  SG_ RearViewAVM_CancelReason : 1|2@0+ (1,0) [0|0] "" METER
  SG_ RearViewAVM_CancelReason_RER : 15|1@0+ (1,0) [0|0] "" METER

BO_ 1690 METER_A8: 7 METER
  SG_ TripDistanceHEV : 7|17@0+ (0.1,0) [0|10000] "-" BCM
  SG_ InstantConsumptionICEdisplay : 31|10@0+ (0.1,0) [0|102.3] "" BCM
  SG_ TripDistanceZEV : 37|17@0+ (0.1,0) [0|10000] "-" BCM

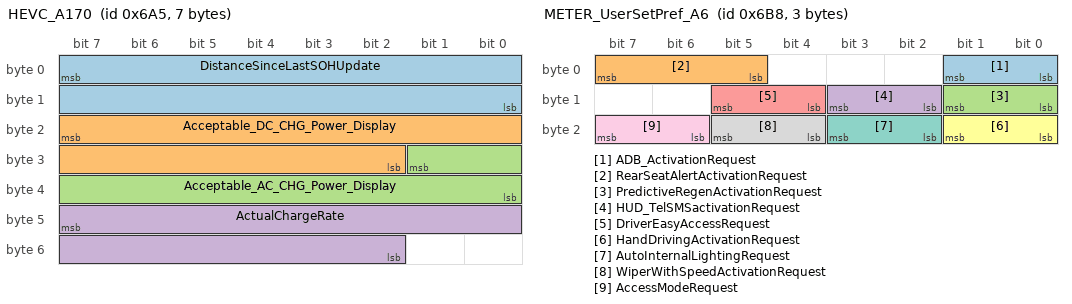
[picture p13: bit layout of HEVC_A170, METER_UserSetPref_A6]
BO_ 1701 HEVC_A170: 7 BCM
  SG_ DistanceSinceLastSOHUpdate : 7|16@0+ (0.1,0) [0|6400] "km" METER
  SG_ Acceptable_DC_CHG_Power_Display : 23|14@0+ (0.05,0) [0|500] "kW" METER
  SG_ Acceptable_AC_CHG_Power_Display : 25|10@0+ (0.05,0) [0|50] "kW" METER
  SG_ ActualChargeRate : 47|14@0+ (0.05,0) [0|500] "kW" METER

BO_ 1703 BCM_R14: 6 BCM
  SG_ ProgrammedChargeStatus : 45|2@0+ (1,0) [0|0] "" METER

BO_ 1705 FrCamADAS_R102: 7 BCM
  SG_ SpeedLimNotifActivationStatus : 7|2@0+ (1,0) [0|0] "" METER

BO_ 1709 SRRR_R101: 1 BCM
  SG_ BSIS_RightCancelReasonRER : 5|1@0+ (1,0) [0|0] "" METER
  SG_ BSIS_RightCancelReason : 7|2@0+ (1,0) [0|0] "" METER

BO_ 1711 IVI_N111: 3 BCM
  SG_ RouteConf_METER_Request : 10|2@0+ (1,0) [0|0] "" METER
  SG_ TableModeRequest : 23|2@0+ (1,0) [0|0] "" DSMU

BO_ 1720 METER_UserSetPref_A6: 3 METER
  SG_ ADB_ActivationRequest : 1|2@0+ (1,0) [0|0] "" BCM
  SG_ RearSeatAlertActivationRequest : 7|3@0+ (1,0) [0|0] "" BCM
  SG_ PredictiveRegenActivationRequest : 9|2@0+ (1,0) [0|0] "" BCM
  SG_ HUD_TelSMSactivationRequest : 11|2@0+ (1,0) [0|0] "" BCM
  SG_ DriverEasyAccessRequest : 13|2@0+ (1,0) [0|0] "" DSMU
  SG_ HandDrivingActivationRequest : 17|2@0+ (1,0) [0|0] "" BCM
  SG_ AutoInternalLightingRequest : 19|2@0+ (1,0) [0|0] "" BCM
  SG_ WiperWithSpeedActivationRequest : 21|2@0+ (1,0) [0|0] "" BCM
  SG_ AccessModeRequest : 23|2@0+ (1,0) [0|0] "" BCM

BO_ 1721 SRRL_R101: 1 BCM
  SG_ BSIS_LeftCancelReasonRER : 5|1@0+ (1,0) [0|0] "" METER
  SG_ BSIS_LeftCancelReason : 7|2@0+ (1,0) [0|0] "" METER

BO_ 1724 IVI_R18: 8 BCM
  SG_ SC_TargetSOC : 63|5@0+ (5,0) [0|100] "%" METER

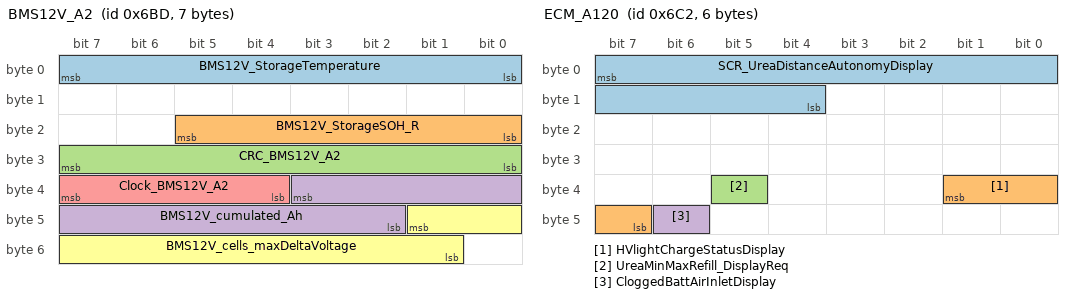
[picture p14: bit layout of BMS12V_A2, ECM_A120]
BO_ 1725 BMS12V_A2: 7 BMS_12V
  SG_ BMS12V_StorageTemperature : 7|8@0+ (0.5,-45) [-45|80] "°C" BCM
  SG_ BMS12V_StorageSOH_R : 21|6@0+ (1,100) [100|160] "%" BCM
  SG_ CRC_BMS12V_A2 : 31|8@0+ (1,0) [0|255] "" BCM
  SG_ BMS12V_cumulated_Ah : 35|10@0+ (300,0) [0|300000] "Ah" BCM
  SG_ Clock_BMS12V_A2 : 39|4@0+ (1,0) [0|15] "" BCM
  SG_ BMS12V_cells_maxDeltaVoltage : 41|9@0+ (0.005,0) [0|2] "V" BCM

BO_ 1730 ECM_A120: 6 BCM
  SG_ SCR_UreaDistanceAutonomyDisplay : 7|12@0+ (10,0) [0|40940] "km" METER
  SG_ HVlightChargeStatusDisplay : 33|3@0+ (1,0) [0|0] "" METER
  SG_ UreaMinMaxRefill_DisplayReq : 37|1@0+ (1,0) [0|0] "" METER
  SG_ CloggedBattAirInletDisplay : 46|1@0+ (1,0) [0|0] "" METER

BO_ 1738 METER_A105: 8 METER
  SG_ ePedal_HoldOffModeRequest : 1|2@0+ (1,0) [0|0] "" BCM
  SG_ VirtualKeySuspendReq : 3|2@0+ (1,0) [0|0] "" BCM
  SG_ SET_ADL3Activation_Request : 9|2@0+ (1,0) [0|0] "" BCM
  SG_ SET_AD_HandsOff_Request : 11|2@0+ (1,0) [0|0] "" BCM
  SG_ SET_ALC_AssistMode_Request : 13|2@0+ (1,0) [0|0] "" BCM
  SG_ SET_ADL3_Request : 15|2@0+ (1,0) [0|0] "" BCM
  SG_ AmbientLightingArea3Req_Meter : 17|2@0+ (1,0) [0|0] "" BCM
  SG_ AmbientLightingArea2Req_Meter : 19|2@0+ (1,0) [0|0] "" BCM
  SG_ SET_ALCP2P_AlertLevel_Request : 23|3@0+ (1,0) [0|0] "" BCM
  SG_ HUD_UpDownRequest : 25|2@0+ (1,0) [0|0] "" BCM
  SG_ AmbientLightingArea5Req_Meter : 29|2@0+ (1,0) [0|0] "" BCM
  SG_ AmbientLightingArea1Req_Meter : 31|2@0+ (1,0) [0|0] "" BCM
  SG_ RearSeatAlertAcknowledgement : 34|2@0+ (1,0) [0|0] "" BCM
  SG_ RearSeatCheckAcknowledgement : 35|1@0+ (1,0) [0|0] "" BCM
  SG_ InternalLightingIntensityRequest : 38|3@0+ (1,0) [0|0] "" BCM
  SG_ SonarSystemPauseRequest : 39|1@0+ (1,0) [0|0] "" BCM
  SG_ EmblemLightIntensityRequest2 : 44|5@0+ (5,0) [0|100] "%" BCM
  SG_ AmbientADLinkRequest2 : 46|2@0+ (1,0) [0|0] "" BCM
  SG_ FunctionalLightingActivReq2 : 49|2@0+ (1,0) [0|0] "" BCM
  SG_ CASP_ActivationRequest : 51|2@0+ (1,0) [0|0] "" BCM
  SG_ AES_ActivationRequest : 53|2@0+ (1,0) [0|0] "" BCM
  SG_ SET_ContextSpdLocal_ActRequest : 58|3@0+ (1,0) [0|0] "" BCM
  SG_ LCDN_ActivationRequest : 60|2@0+ (1,0) [0|0] "" BCM
  SG_ LCDN_SensibilityRequest : 63|3@0+ (1,0) [0|0] "" BCM

BO_ 1741 METER_A102: 8 METER
  SG_ VolumAlarmDisplayState : 1|2@0+ (1,0) [0|0] "" BCM
  SG_ ePedalDecelerationLevelRequest : 10|2@0+ (1,0) [0|0] "" BCM
  SG_ ePedalMemorySettingRequest : 12|2@0+ (1,0) [0|0] "" BCM
  SG_ DCA_ActivationRequest : 15|2@0+ (1,0) [0|0] "" BCM
  SG_ ContextSpeed_ActivationRequest : 18|3@0+ (1,0) [0|0] "" BCM
  SG_ OffsetValue_Request : 23|5@0+ (1,0) [0|0] "" BCM
  SG_ SET_NavigatDriveAssist_Request : 25|2@0+ (1,0) [0|0] "" BCM
  SG_ SET_ALCActivationByTSIG_Request : 27|2@0+ (1,0) [0|0] "" BCM
  SG_ OffsetActivation_Request : 29|2@0+ (1,0) [0|0] "" BCM
  SG_ ContextRoad_ActivationRequest : 31|2@0+ (1,0) [0|0] "" BCM
  SG_ SET_OvertakingAssist_Request : 33|2@0+ (1,0) [0|0] "" BCM
  SG_ SET_Deceleration_Request : 36|3@0+ (1,0) [0|0] "" BCM
  SG_ SET_Acceleration_Request : 39|3@0+ (1,0) [0|0] "" BCM
  SG_ SET_VoiceGuidance_Request : 41|2@0+ (1,0) [0|0] "" BCM
  SG_ UserSelectChargePowerDisplay : 44|3@0+ (1,0) [0|0] "" BCM
  SG_ BatteryCool_eACLimitStatus : 47|2@0+ (1,0) [0|0] "" BCM
  SG_ SET_CornerSpeedLevel_Request : 49|3@0+ (1,0) [0|0] "" BCM
  SG_ SET_PositionInLane_Request : 52|3@0+ (1,0) [0|0] "" BCM
  SG_ SET_LaneChangeSwiftness_Request : 55|3@0+ (1,0) [0|0] "" BCM
  SG_ HVbatteryCoolingActivationReq : 58|2@0+ (1,0) [0|0] "" BCM
  SG_ SET_OvertakeRelatSpeed_Request : 61|3@0+ (1,0) [0|0] "" BCM

BO_ 1742 ADAS_A124: 8 BCM
  SG_ EAP_CancelReason : 1|2@0+ (1,0) [0|0] "" METER
  SG_ ACC_CancelReasonRER : 2|1@0+ (1,0) [0|0] "" METER
  SG_ ACC_CancelReason_v2 : 7|5@0+ (1,0) [0|0] "" METER
  SG_ BCI_CancelReasonRER : 8|1@0+ (1,0) [0|0] "" METER
  SG_ OSE_CancelReasonRER : 9|1@0+ (1,0) [0|0] "" METER
  SG_ APA_Warning3 : 10|1@0+ (1,0) [0|0] "" METER
  SG_ AEB_CancelReasonRER : 11|1@0+ (1,0) [0|0] "" METER
  SG_ AEB_CancelReason_v2 : 15|4@0+ (1,0) [0|0] "" METER
  SG_ LDW_CancelReason : 18|3@0+ (1,0) [0|0] "" METER
  SG_ DCA_CancelReason : 23|5@0+ (1,0) [0|0] "" METER
  SG_ LKA_CancelReason : 26|3@0+ (1,0) [0|0] "" METER
  SG_ LCA_CancelReasonRER : 27|1@0+ (1,0) [0|0] "" METER
  SG_ LCA_CancelReason : 31|4@0+ (1,0) [0|0] "" METER
  SG_ OSE_CancelReason : 34|3@0+ (1,0) [0|0] "" METER
  SG_ ELKA_CancelReasonRER : 35|1@0+ (1,0) [0|0] "" METER
  SG_ LKA_CancelReasonRER : 38|1@0+ (1,0) [0|0] "" METER
  SG_ LDW_CancelReasonRER : 39|1@0+ (1,0) [0|0] "" METER
  SG_ ELKA_CancelReason_v2 : 43|4@0+ (1,0) [0|0] "" METER
  SG_ BCI_CancelReason_v2 : 47|4@0+ (1,0) [0|0] "" METER
  SG_ AES_CancelReasonRER : 48|1@0+ (1,0) [0|0] "" METER
  SG_ AES_CancelReason : 52|4@0+ (1,0) [0|0] "" METER
  SG_ ADmodeStatus_Slow : 55|3@0+ (1,0) [0|0] "" DSMU
  SG_ WDA_ChoiceState2 : 57|1@0+ (1,0) [0|0] "" METER
  SG_ ELKA_ChoiceState2 : 58|1@0+ (1,0) [0|0] "" METER
  SG_ LaneSupport_ChoiceState : 59|1@0+ (1,0) [0|0] "" METER
  SG_ LaneSupport_ActivationState : 60|1@0+ (1,0) [0|0] "" METER
  SG_ LDW_Sensibility_ChoiceState : 62|2@0+ (1,0) [0|0] "" METER
  SG_ RAB_ChoiceState : 63|1@0+ (1,0) [0|0] "" METER

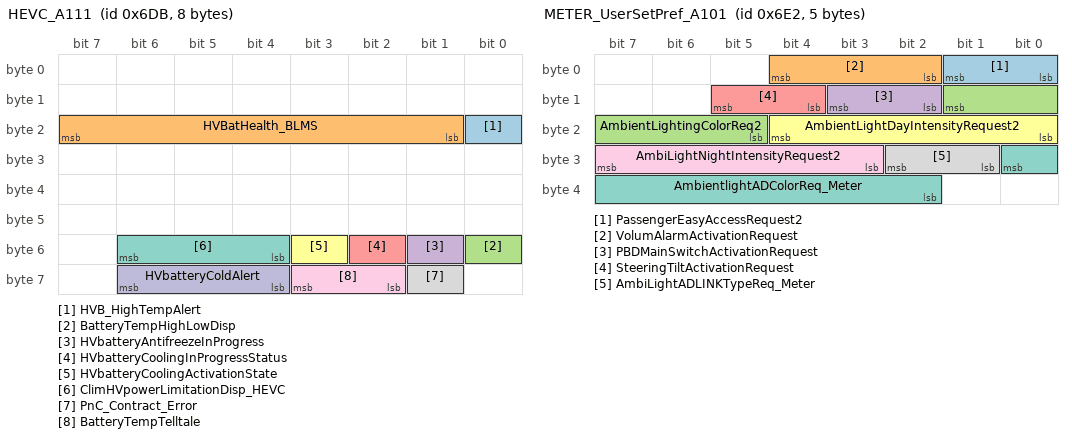
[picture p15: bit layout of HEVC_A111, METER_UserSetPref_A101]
BO_ 1755 HEVC_A111: 8 BCM
  SG_ HVB_HighTempAlert : 16|1@0+ (1,0) [0|0] "" METER
  SG_ HVBatHealth_BLMS : 23|7@0+ (1,0) [0|126] "%" METER
  SG_ BatteryTempHighLowDisp : 48|1@0+ (1,0) [0|0] "" METER
  SG_ HVbatteryAntifreezeInProgress : 49|1@0+ (1,0) [0|0] "" METER
  SG_ HVbatteryCoolingInProgressStatus : 50|1@0+ (1,0) [0|0] "" METER
  SG_ HVbatteryCoolingActivationState : 51|1@0+ (1,0) [0|0] "" METER
  SG_ ClimHVpowerLimitationDisp_HEVC : 54|3@0+ (1,0) [0|0] "" METER
  SG_ PnC_Contract_Error : 57|1@0+ (1,0) [0|0] "" METER
  SG_ BatteryTempTelltale : 59|2@0+ (1,0) [0|0] "" METER
  SG_ HVbatteryColdAlert : 62|3@0+ (1,0) [0|0] "" METER

BO_ 1756 METER_A109: 8 METER
  SG_ V2L_SettingModeRequest : 5|3@0+ (1,0) [0|0] "" BCM
  SG_ V2L_FrequencySettingRequest : 7|2@0+ (1,0) [0|0] "" BCM
  SG_ SET_OffsetValueLocal_Request : 20|5@0+ (1,0) [0|0] "" BCM
  SG_ Distraction_AlertActivationReq : 25|2@0+ (1,0) [0|0] "" BCM
  SG_ ATCVT_ATFRemainingDistanceReset : 32|1@0+ (1,0) [0|0] "" BCM
  SG_ ELKA_OTOC_ActivationRequest : 34|2@0+ (1,0) [0|0] "" BCM
  SG_ DMC_SensitivityRequest : 37|3@0+ (1,0) [0|0] "" BCM
  SG_ Drowsy_AlertActivationRequest : 39|2@0+ (1,0) [0|0] "" BCM
  SG_ PSDBuzzerActivationRequest : 41|2@0+ (1,0) [0|0] "" BCM
  SG_ OverspeedAlertActivationRequest : 43|2@0+ (1,0) [0|0] "" BCM
  SG_ LKA_DL_ActivationRequest : 45|2@0+ (1,0) [0|0] "" BCM
  SG_ ELKS_ActivationRequest : 47|2@0+ (1,0) [0|0] "" BCM
  SG_ Cluster_DispViewModeChangeResult : 49|2@0+ (1,0) [0|0] "" BCM
  SG_ Cluster_DisplayViewModeStatus : 52|3@0+ (1,0) [0|0] "" BCM
  SG_ Privacy_Mode_Request : 55|3@0+ (1,0) [0|0] "" BCM
  SG_ Cluster_DispContentsChangeResult : 57|2@0+ (1,0) [0|0] "" BCM
  SG_ Cluster_DisplayContentsStatus : 63|6@0+ (1,0) [0|0] "" BCM

BO_ 1762 METER_UserSetPref_A101: 5 METER
  SG_ PassengerEasyAccessRequest2 : 1|2@0+ (1,0) [0|0] "" PSCU
  SG_ VolumAlarmActivationRequest : 4|3@0+ (1,0) [0|0] "" BCM
  SG_ AmbientLightingColorReq2 : 9|5@0+ (1,0) [0|0] "" BCM
  SG_ PBDMainSwitchActivationRequest : 11|2@0+ (1,0) [0|0] "" PBD
  SG_ SteeringTiltActivationRequest : 13|2@0+ (1,0) [0|0] "" DSMU
  SG_ AmbientLightDayIntensityRequest2 : 20|5@0+ (5,0) [0|100] "%" BCM
  SG_ AmbientlightADColorReq_Meter : 24|7@0+ (1,0) [0|0] "" BCM
  SG_ AmbiLightADLINKTypeReq_Meter : 26|2@0+ (1,0) [0|0] "" BCM
  SG_ AmbiLightNightIntensityRequest2 : 31|5@0+ (5,0) [0|100] "%" BCM

BO_ 1763 METER_UserSetPref_A102: 1 METER
  SG_ AntiUndertake_ActivationRequest : 2|2@0+ (1,0) [0|0] "" BCM
  SG_ HUD_RotationPositionRequest : 7|5@0+ (1,0) [0|0] "" BCM

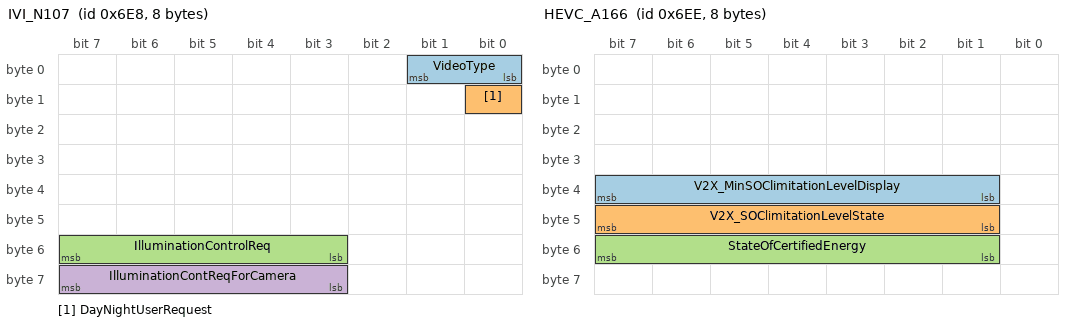
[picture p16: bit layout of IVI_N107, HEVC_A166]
BO_ 1768 IVI_N107: 8 BCM
  SG_ VideoType : 1|2@0+ (1,0) [0|0] "" METER
  SG_ DayNightUserRequest : 8|1@0+ (1,0) [0|0] "" METER
  SG_ IlluminationControlReq : 55|5@0+ (1,0) [0|0] "" METER
  SG_ IlluminationContReqForCamera : 63|5@0+ (1,0) [0|0] "" METER

BO_ 1772 METER_A110: 8 METER
  SG_ V2X_SOClimitationLevelRequest : 7|7@0+ (1,0) [0|100] "%" BCM
  SG_ AEB_JuncAssistActivationRequest : 9|2@0+ (1,0) [0|0] "" BCM
  SG_ HUD_SSAActivationRequest : 11|2@0+ (1,0) [0|0] "" BCM
  SG_ HUD_SonarActivationRequest : 13|2@0+ (1,0) [0|0] "" BCM
  SG_ HUD_ShiftActivationRequest : 15|2@0+ (1,0) [0|0] "" BCM
  SG_ CPDAcknowledgement : 17|2@0+ (1,0) [0|0] "" BCM
  SG_ CPDActivationRequest : 19|2@0+ (1,0) [0|0] "" BCM
  SG_ OSE_ActivationRequest : 21|2@0+ (1,0) [0|0] "" BCM
  SG_ ExternalTempSensorRawValue : 29|10@0+ (1,0) [0|1023] "-" BCM
  SG_ IntelD_SettingRequest : 31|2@0+ (1,0) [0|0] "" BCM
  SG_ ADTutorial_ActivationRequest : 33|2@0+ (1,0) [0|0] "" BCM
  SG_ TSRPredictive_ActivationRequest : 35|2@0+ (1,0) [0|0] "" BCM
  SG_ FuelGaugeDisplayValue : 47|7@0+ (1,0) [0|100] "%" BCM
  SG_ GTLN_ActivationRequest : 49|2@0+ (1,0) [0|0] "" BCM
  SG_ ADASCD_AssistTypeRequest : 51|2@0+ (1,0) [0|0] "" BCM
  SG_ CPD_tempActivationRequest : 53|2@0+ (1,0) [0|0] "" BCM
  SG_ SET_ADL3_ChoiceRequest : 55|2@0+ (1,0) [0|0] "" BCM
  SG_ SET_DMC_SensitivityRequest : 58|3@0+ (1,0) [0|0] "" BCM
  SG_ HVBLow_DTE_Setting : 63|5@0+ (1,0) [0|0] "" BCM

BO_ 1773 PSDL_A103: 1 BCM
  SG_ PSD_Left_BuzzerActivationStatus : 7|1@0+ (1,0) [0|0] "" METER

BO_ 1774 HEVC_A166: 8 BCM
  SG_ V2X_MinSOClimitationLevelDisplay : 39|7@0+ (1,0) [0|100] "%" METER
  SG_ V2X_SOClimitationLevelState : 47|7@0+ (1,0) [0|100] "%" METER
  SG_ StateOfCertifiedEnergy : 55|7@0+ (1,0) [0|100] "%" METER

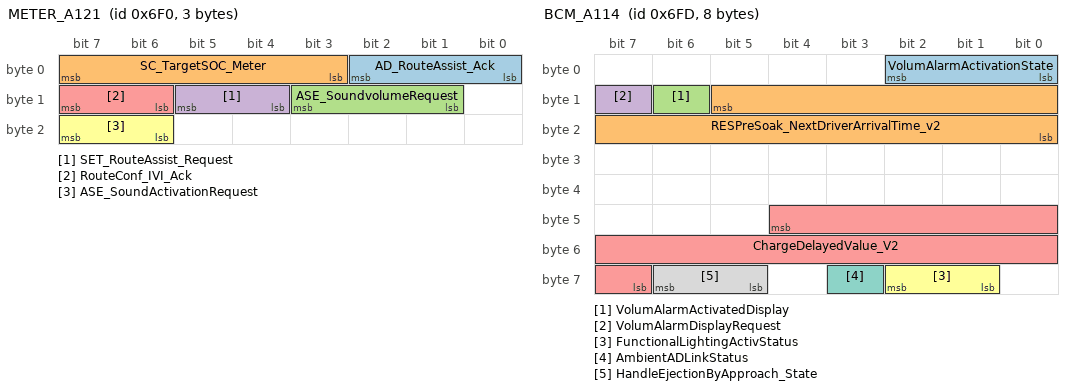
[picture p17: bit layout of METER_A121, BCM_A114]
BO_ 1776 METER_A121: 3 METER
  SG_ AD_RouteAssist_Ack : 2|3@0+ (1,0) [0|0] "" BCM
  SG_ SC_TargetSOC_Meter : 7|5@0+ (5,0) [0|100] "%" BCM
  SG_ ASE_SoundvolumeRequest : 11|3@0+ (1,0) [0|0] "" BCM
  SG_ SET_RouteAssist_Request : 13|2@0+ (1,0) [0|0] "" BCM
  SG_ RouteConf_IVI_Ack : 15|2@0+ (1,0) [0|0] "" BCM
  SG_ ASE_SoundActivationRequest : 23|2@0+ (1,0) [0|0] "" BCM

BO_ 1783 IVI_R12: 7 BCM
  SG_ GainECOdistanceDisplay : 35|13@0+ (0.1,0) [0|800] "wu" METER

BO_ 1789 BCM_A114: 8 BCM
  SG_ VolumAlarmActivationState : 2|3@0+ (1,0) [0|0] "" METER
  SG_ RESPreSoak_NextDriverArrivalTime_v2 : 13|14@0+ (1,0) [0|10080] "min" METER
  SG_ VolumAlarmActivatedDisplay : 14|1@0+ (1,0) [0|0] "" METER
  SG_ VolumAlarmDisplayRequest : 15|1@0+ (1,0) [0|0] "" METER
  SG_ ChargeDelayedValue_V2 : 44|14@0+ (1,0) [0|10080] "min" METER
  SG_ FunctionalLightingActivStatus : 58|2@0+ (1,0) [0|0] "" METER
  SG_ AmbientADLinkStatus : 59|1@0+ (1,0) [0|0] "" METER
  SG_ HandleEjectionByApproach_State : 62|2@0+ (1,0) [0|0] "" METER

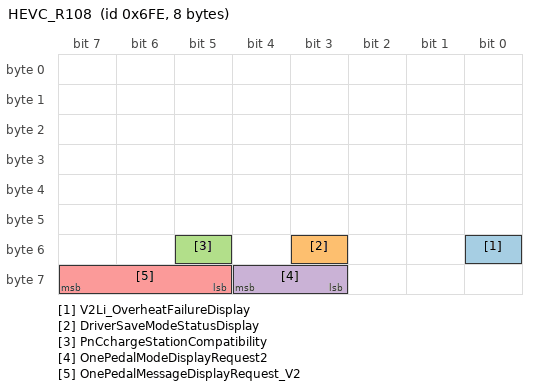
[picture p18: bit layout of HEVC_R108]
BO_ 1790 HEVC_R108: 8 BCM
  SG_ V2Li_OverheatFailureDisplay : 48|1@0+ (1,0) [0|0] "" METER
  SG_ DriverSaveModeStatusDisplay : 51|1@0+ (1,0) [0|0] "" METER
  SG_ PnCchargeStationCompatibility : 53|1@0+ (1,0) [0|0] "" METER
  SG_ OnePedalModeDisplayRequest2 : 60|2@0+ (1,0) [0|0] "" METER
  SG_ OnePedalMessageDisplayRequest_V2 : 63|3@0+ (1,0) [0|0] "" METER

BO_ 1791 HEVC_R109: 8 BCM
  SG_ ElecAutonomyGainClimOffDisplay : 7|8@0+ (1,0) [0|250] "km" METER
  SG_ ThermalComfortPowerDisplay : 15|3@0+ (1,0) [0|5] "kW" METER

BO_ 1800 DTOOL_to_MID: 8 BCM
  SG_ DTOOL_to_MID : 7|64@0+ (1,0) [0|0] "" MID

BO_ 1811 DTOOL_to_ECDO: 8 BCM
  SG_ DTOOL_to_ECDO : 7|64@0+ (1,0) [0|0] "" ECDO

BO_ 1814 DTOOL_to_PSCU: 8 BCM
  SG_ DTOOL_to_PSCU : 7|64@0+ (1,0) [0|0] "" PSCU

BO_ 1832 MID_to_DTOOL: 8 MID
  SG_ MID_to_DTOOL : 7|64@0+ (1,0) [0|0] "" BCM

BO_ 1843 ECDO_to_DTOOL: 8 ECDO
  SG_ ECDO_to_DTOOL : 7|64@0+ (1,0) [0|0] "" BCM

BO_ 1846 PSCU_to_DTOOL: 8 PSCU
  SG_ PSCU_to_DTOOL : 7|64@0+ (1,0) [0|0] "" BCM

BO_ 1855 DTOOL_to_VSP: 8 BCM
  SG_ DTOOL_to_VSP : 7|64@0+ (1,0) [0|0] "" VSP

BO_ 1859 DTOOL_to_METER: 8 BCM
  SG_ DTOOL_to_METER : 7|64@0+ (1,0) [0|0] "" METER

BO_ 1871 DTOOL_to_DSMU: 8 BCM
  SG_ DTOOL_to_DSMU : 7|64@0+ (1,0) [0|0] "" DSMU

BO_ 1876 DTOOL_to_PSB: 8 BCM
  SG_ DTOOL_to_PSB : 7|64@0+ (1,0) [0|0] "" PSB_D

BO_ 1889 VSP_to_DTOOL: 8 VSP
  SG_ VSP_to_DTOOL : 7|64@0+ (1,0) [0|0] "" BCM

BO_ 1891 METER_to_DTOOL: 8 METER
  SG_ METER_to_DTOOL : 7|64@0+ (1,0) [0|0] "" BCM

BO_ 1903 DSMU_to_DTOOL: 8 DSMU
  SG_ DSMU_to_DTOOL : 7|64@0+ (1,0) [0|0] "" BCM

BO_ 1908 PSB_to_DTOOL: 8 PSB_D
  SG_ PSB_to_DTOOL : 7|64@0+ (1,0) [0|0] "" BCM

BO_ 2563507968 SIGMA_CDMTriggerFrame: 7 BCM
  SG_ SIGMA_CDM : 4|29@0+ (1,0) [0|0] "" BMS_12V,DSMU,METER,PBD,PSCU,RSCU2R,RSCU3R,SCCM
  SG_ SIGMA_DTCCDM : 39|24@0+ (1,0) [0|0] "" BMS_12V,DSMU,METER,PBD,PSCU,RSCU2R,RSCU3R,SCCM

BO_ 2563508007 SIGMA_eHBoxTriggerFrame: 7 BCM
  SG_ SIGMA_eHBox : 4|29@0+ (1,0) [0|0] "" BMS_12V,DSMU,METER,PBD,PSCU,RSCU2R,RSCU3R,SCCM
  SG_ SIGMA_DTCeHBox : 39|24@0+ (1,0) [0|0] "" BMS_12V,DSMU,METER,PBD,PSCU,RSCU2R,RSCU3R,SCCM

BO_ 2563508009 SIGMA_PSD_RTriggerFrame: 7 BCM
  SG_ SIGMA_PSD_R : 4|29@0+ (1,0) [0|0] "" BMS_12V,DSMU,METER,PBD,PSCU,RSCU2R,RSCU3R,SCCM
  SG_ SIGMA_DTCPSD_R : 39|24@0+ (1,0) [0|0] "" BMS_12V,DSMU,METER,PBD,PSCU,RSCU2R,RSCU3R,SCCM

BO_ 2563508019 SIGMA_PBDTriggerFrame: 7 PBD
  SG_ SIGMA_PBD : 4|29@0+ (1,0) [0|0] "" BCM,BMS_12V,DSMU,METER,PSCU,RSCU2R,RSCU3R,SCCM
  SG_ SIGMA_DTCPBD : 39|24@0+ (1,0) [0|0] "" BCM,BMS_12V,DSMU,METER,PSCU,RSCU2R,RSCU3R,SCCM

BO_ 2563508021 SIGMA_RADARTriggerFrame: 7 BCM
  SG_ SIGMA_RADAR : 4|29@0+ (1,0) [0|0] "" BMS_12V,DSMU,METER,PBD,PSCU,RSCU2R,RSCU3R,SCCM
  SG_ SIGMA_DTCRADAR : 39|24@0+ (1,0) [0|0] "" BMS_12V,DSMU,METER,PBD,PSCU,RSCU2R,RSCU3R,SCCM

BO_ 2563508022 SIGMA_PSCUTriggerFrame: 7 PSCU
  SG_ SIGMA_PSCU : 4|29@0+ (1,0) [0|0] "" BCM,BMS_12V,DSMU,METER,PBD,RSCU2R,RSCU3R,SCCM
  SG_ SIGMA_DTCPSCU : 39|24@0+ (1,0) [0|0] "" BCM,BMS_12V,DSMU,METER,PBD,RSCU2R,RSCU3R,SCCM

BO_ 2563508030 SIGMA_SRad_RLTriggerFrame: 7 BCM
  SG_ SIGMA_SRad_RL : 4|29@0+ (1,0) [0|0] "" BMS_12V,DSMU,METER,PBD,PSCU,RSCU2R,RSCU3R,SCCM
  SG_ SIGMA_DTCSRad_RL : 39|24@0+ (1,0) [0|0] "" BMS_12V,DSMU,METER,PBD,PSCU,RSCU2R,RSCU3R,SCCM

BO_ 2563508035 SIGMA_eRDC_LTriggerFrame: 7 BCM
  SG_ SIGMA_eRDC_L : 4|29@0+ (1,0) [0|0] "" BMS_12V,DSMU,METER,PBD,PSCU,RSCU2R,RSCU3R,SCCM
  SG_ SIGMA_DTCeRDC_L : 39|24@0+ (1,0) [0|0] "" BMS_12V,DSMU,METER,PBD,PSCU,RSCU2R,RSCU3R,SCCM

BO_ 2563508037 SIGMA_eRDC_RTriggerFrame: 7 BCM
  SG_ SIGMA_eRDC_R : 4|29@0+ (1,0) [0|0] "" BMS_12V,DSMU,METER,PBD,PSCU,RSCU2R,RSCU3R,SCCM
  SG_ SIGMA_DTCeRDC_R : 39|24@0+ (1,0) [0|0] "" BMS_12V,DSMU,METER,PBD,PSCU,RSCU2R,RSCU3R,SCCM

BO_ 2563508042 SIGMA_ANCTriggerFrame: 7 BCM
  SG_ SIGMA_ANC : 4|29@0+ (1,0) [0|0] "" BMS_12V,DSMU,METER,PBD,PSCU,RSCU2R,RSCU3R,SCCM
  SG_ SIGMA_DTCANC : 39|24@0+ (1,0) [0|0] "" BMS_12V,DSMU,METER,PBD,PSCU,RSCU2R,RSCU3R,SCCM

BO_ 2563508064 SIGMA_VDCTriggerFrame: 7 BCM
  SG_ SIGMA_VDC : 4|29@0+ (1,0) [0|0] "" BMS_12V,DSMU,METER,PBD,PSCU,RSCU2R,RSCU3R,SCCM
  SG_ SIGMA_DTCVDC : 39|24@0+ (1,0) [0|0] "" BMS_12V,DSMU,METER,PBD,PSCU,RSCU2R,RSCU3R,SCCM

BO_ 2563508066 SIGMA_EPSTriggerFrame: 7 BCM
  SG_ SIGMA_EPS : 4|29@0+ (1,0) [0|0] "" BMS_12V,DSMU,METER,PBD,PSCU,RSCU2R,RSCU3R,SCCM
  SG_ SIGMA_DTCEPS : 39|24@0+ (1,0) [0|0] "" BMS_12V,DSMU,METER,PBD,PSCU,RSCU2R,RSCU3R,SCCM

BO_ 2563508067 SIGMA_METERTriggerFrame: 7 METER
  SG_ SIGMA_METER : 4|29@0+ (1,0) [0|0] "" BCM,BMS_12V,DSMU,PBD,PSCU,RSCU2R,RSCU3R,SCCM
  SG_ SIGMA_DTCMETER : 39|24@0+ (1,0) [0|0] "" BCM,BMS_12V,DSMU,PBD,PSCU,RSCU2R,RSCU3R,SCCM

BO_ 2563508068 SIGMA_HVACTriggerFrame: 7 BCM
  SG_ SIGMA_HVAC : 4|29@0+ (1,0) [0|0] "" BMS_12V,DSMU,METER,PBD,PSCU,RSCU2R,RSCU3R,SCCM
  SG_ SIGMA_DTCHVAC : 39|24@0+ (1,0) [0|0] "" BMS_12V,DSMU,METER,PBD,PSCU,RSCU2R,RSCU3R,SCCM

BO_ 2563508069 SIGMA_BCMTriggerFrame: 7 BCM
  SG_ SIGMA_BCM : 4|29@0+ (1,0) [0|0] "" BMS_12V,DSMU,METER,PBD,PSCU,RSCU2R,RSCU3R,SCCM
  SG_ SIGMA_DTCBCM : 39|24@0+ (1,0) [0|0] "" BMS_12V,DSMU,METER,PBD,PSCU,RSCU2R,RSCU3R,SCCM

BO_ 2563508071 SIGMA_IVITriggerFrame: 7 BCM
  SG_ SIGMA_IVI : 4|29@0+ (1,0) [0|0] "" BMS_12V,DSMU,METER,PBD,PSCU,RSCU2R,RSCU3R,SCCM
  SG_ SIGMA_DTCIVI : 39|24@0+ (1,0) [0|0] "" BMS_12V,DSMU,METER,PBD,PSCU,RSCU2R,RSCU3R,SCCM

BO_ 2563508072 SIGMA_4WDTriggerFrame: 7 BCM
  SG_ SIGMA_4WD : 4|29@0+ (1,0) [0|0] "" BMS_12V,DSMU,METER,PBD,PSCU,RSCU2R,RSCU3R,SCCM
  SG_ SIGMA_DTC4WD : 39|24@0+ (1,0) [0|0] "" BMS_12V,DSMU,METER,PBD,PSCU,RSCU2R,RSCU3R,SCCM

BO_ 2563508077 SIGMA_USMTriggerFrame: 7 BCM
  SG_ SIGMA_USM : 4|29@0+ (1,0) [0|0] "" BMS_12V,DSMU,METER,PBD,PSCU,RSCU2R,RSCU3R,SCCM
  SG_ SIGMA_DTCUSM : 39|24@0+ (1,0) [0|0] "" BMS_12V,DSMU,METER,PBD,PSCU,RSCU2R,RSCU3R,SCCM

BO_ 2563508078 SIGMA_SONARTriggerFrame: 7 BCM
  SG_ SIGMA_SONAR : 4|29@0+ (1,0) [0|0] "" BMS_12V,DSMU,METER,PBD,PSCU,RSCU2R,RSCU3R,SCCM
  SG_ SIGMA_DTCSONAR : 39|24@0+ (1,0) [0|0] "" BMS_12V,DSMU,METER,PBD,PSCU,RSCU2R,RSCU3R,SCCM

BO_ 2563508079 SIGMA_DSMUTriggerFrame: 7 DSMU
  SG_ SIGMA_DSMU : 4|29@0+ (1,0) [0|0] "" BCM,BMS_12V,METER,PBD,PSCU,RSCU2R,RSCU3R,SCCM
  SG_ SIGMA_DTCDSMU : 39|24@0+ (1,0) [0|0] "" BCM,BMS_12V,METER,PBD,PSCU,RSCU2R,RSCU3R,SCCM

BO_ 2563508082 SIGMA_ACUTriggerFrame: 7 BCM
  SG_ SIGMA_ACU : 4|29@0+ (1,0) [0|0] "" BMS_12V,DSMU,METER,PBD,PSCU,RSCU2R,RSCU3R,SCCM
  SG_ SIGMA_DTCACU : 39|24@0+ (1,0) [0|0] "" BMS_12V,DSMU,METER,PBD,PSCU,RSCU2R,RSCU3R,SCCM

BO_ 2563508089 SIGMA_PSD_LTriggerFrame: 7 BCM
  SG_ SIGMA_PSD_L : 4|29@0+ (1,0) [0|0] "" BMS_12V,DSMU,METER,PBD,PSCU,RSCU2R,RSCU3R,SCCM
  SG_ SIGMA_DTCPSD_L : 39|24@0+ (1,0) [0|0] "" BMS_12V,DSMU,METER,PBD,PSCU,RSCU2R,RSCU3R,SCCM

BO_ 2563508093 SIGMA_ADASTriggerFrame: 7 BCM
  SG_ SIGMA_ADAS : 4|29@0+ (1,0) [0|0] "" BMS_12V,DSMU,METER,PBD,PSCU,RSCU2R,RSCU3R,SCCM
  SG_ SIGMA_DTCADAS : 39|24@0+ (1,0) [0|0] "" BMS_12V,DSMU,METER,PBD,PSCU,RSCU2R,RSCU3R,SCCM

BO_ 2563508099 SIGMA_A_IVCTriggerFrame: 7 BCM
  SG_ SIGMA_A_IVC : 4|29@0+ (1,0) [0|0] "" BMS_12V,DSMU,METER,PBD,PSCU,RSCU2R,RSCU3R,SCCM
  SG_ SIGMA_DTCA_IVC : 39|24@0+ (1,0) [0|0] "" BMS_12V,DSMU,METER,PBD,PSCU,RSCU2R,RSCU3R,SCCM

BO_ 2563508108 SIGMA_INV_METriggerFrame: 7 BCM
  SG_ SIGMA_INV_ME : 4|29@0+ (1,0) [0|0] "" BMS_12V,DSMU,METER,PBD,PSCU,RSCU2R,RSCU3R,SCCM
  SG_ SIGMA_DTCINV_ME : 39|24@0+ (1,0) [0|0] "" BMS_12V,DSMU,METER,PBD,PSCU,RSCU2R,RSCU3R,SCCM

BO_ 2563508115 SIGMA_OBC_ACTriggerFrame: 7 BCM
  SG_ SIGMA_OBC_AC : 4|29@0+ (1,0) [0|0] "" BMS_12V,DSMU,METER,PBD,PSCU,RSCU2R,RSCU3R,SCCM
  SG_ SIGMA_DTCOBC_AC : 39|24@0+ (1,0) [0|0] "" BMS_12V,DSMU,METER,PBD,PSCU,RSCU2R,RSCU3R,SCCM

BO_ 2563508122 SIGMA_HEVCTriggerFrame: 7 BCM
  SG_ SIGMA_HEVC : 4|29@0+ (1,0) [0|0] "" BMS_12V,DSMU,METER,PBD,PSCU,RSCU2R,RSCU3R,SCCM
  SG_ SIGMA_DTCHEVC : 39|24@0+ (1,0) [0|0] "" BMS_12V,DSMU,METER,PBD,PSCU,RSCU2R,RSCU3R,SCCM

BO_ 2563508130 SIGMA_AUDIOampTriggerFrame: 7 BCM
  SG_ SIGMA_AUDIOamp : 4|29@0+ (1,0) [0|0] "" BMS_12V,DSMU,METER,PBD,PSCU,RSCU2R,RSCU3R,SCCM
  SG_ SIGMA_DTCAUDIOamp : 39|24@0+ (1,0) [0|0] "" BMS_12V,DSMU,METER,PBD,PSCU,RSCU2R,RSCU3R,SCCM

BO_ 2563508133 SIGMA_HNSTriggerFrame: 7 BCM
  SG_ SIGMA_HNS : 4|29@0+ (1,0) [0|0] "" BMS_12V,DSMU,METER,PBD,PSCU,RSCU2R,RSCU3R,SCCM
  SG_ SIGMA_DTCHNS : 39|24@0+ (1,0) [0|0] "" BMS_12V,DSMU,METER,PBD,PSCU,RSCU2R,RSCU3R,SCCM

BO_ 2563508139 SIGMA_VKMTriggerFrame: 7 BCM
  SG_ SIGMA_VKM : 4|29@0+ (1,0) [0|0] "" BMS_12V,DSMU,METER,PBD,PSCU,RSCU2R,RSCU3R,SCCM
  SG_ SIGMA_DTCVKM : 39|24@0+ (1,0) [0|0] "" BMS_12V,DSMU,METER,PBD,PSCU,RSCU2R,RSCU3R,SCCM

BO_ 2563508153 SIGMA_HFMTriggerFrame: 7 BCM
  SG_ SIGMA_HFM : 4|29@0+ (1,0) [0|0] "" BMS_12V,DSMU,METER,PBD,PSCU,RSCU2R,RSCU3R,SCCM
  SG_ SIGMA_DTCHFM : 39|24@0+ (1,0) [0|0] "" BMS_12V,DSMU,METER,PBD,PSCU,RSCU2R,RSCU3R,SCCM

BO_ 2563508154 SIGMA_AVMTriggerFrame: 7 BCM
  SG_ SIGMA_AVM : 4|29@0+ (1,0) [0|0] "" BMS_12V,DSMU,METER,PBD,PSCU,RSCU2R,RSCU3R,SCCM
  SG_ SIGMA_DTCAVM : 39|24@0+ (1,0) [0|0] "" BMS_12V,DSMU,METER,PBD,PSCU,RSCU2R,RSCU3R,SCCM

BO_ 2563508157 SIGMA_SCUTriggerFrame: 7 BCM
  SG_ SIGMA_SCU : 4|29@0+ (1,0) [0|0] "" BMS_12V,DSMU,METER,PBD,PSCU,RSCU2R,RSCU3R,SCCM
  SG_ SIGMA_DTCSCU : 39|24@0+ (1,0) [0|0] "" BMS_12V,DSMU,METER,PBD,PSCU,RSCU2R,RSCU3R,SCCM

BO_ 2563508164 SIGMA_eShifterTriggerFrame: 7 BCM
  SG_ SIGMA_eShifter : 4|29@0+ (1,0) [0|0] "" BMS_12V,DSMU,METER,PBD,PSCU,RSCU2R,RSCU3R,SCCM
  SG_ SIGMA_DTCeShifter : 39|24@0+ (1,0) [0|0] "" BMS_12V,DSMU,METER,PBD,PSCU,RSCU2R,RSCU3R,SCCM

BO_ 2563508181 SIGMA_SRad_RRTriggerFrame: 7 BCM
  SG_ SIGMA_SRad_RR : 4|29@0+ (1,0) [0|0] "" BMS_12V,DSMU,METER,PBD,PSCU,RSCU2R,RSCU3R,SCCM
  SG_ SIGMA_DTCSRad_RR : 39|24@0+ (1,0) [0|0] "" BMS_12V,DSMU,METER,PBD,PSCU,RSCU2R,RSCU3R,SCCM

BO_ 2563508189 SIGMA_FrCameraTriggerFrame: 7 BCM
  SG_ SIGMA_FrCamera : 4|29@0+ (1,0) [0|0] "" BMS_12V,DSMU,METER,PBD,PSCU,RSCU2R,RSCU3R,SCCM
  SG_ SIGMA_DTCFrCamera : 39|24@0+ (1,0) [0|0] "" BMS_12V,DSMU,METER,PBD,PSCU,RSCU2R,RSCU3R,SCCM

BO_ 2563508200 SIGMA_ECMTriggerFrame: 7 BCM
  SG_ SIGMA_ECM : 4|29@0+ (1,0) [0|0] "" BMS_12V,DSMU,METER,PBD,PSCU,RSCU2R,RSCU3R,SCCM
  SG_ SIGMA_DTCECM : 39|24@0+ (1,0) [0|0] "" BMS_12V,DSMU,METER,PBD,PSCU,RSCU2R,RSCU3R,SCCM

BO_ 2563508201 SIGMA_ATCUTriggerFrame: 7 BCM
  SG_ SIGMA_ATCU : 4|29@0+ (1,0) [0|0] "" BMS_12V,DSMU,METER,PBD,PSCU,RSCU2R,RSCU3R,SCCM
  SG_ SIGMA_DTCATCU : 39|24@0+ (1,0) [0|0] "" BMS_12V,DSMU,METER,PBD,PSCU,RSCU2R,RSCU3R,SCCM

BO_ 2563508205 SIGMA_BMS_HVTriggerFrame: 7 BCM
  SG_ SIGMA_BMS_HV : 4|29@0+ (1,0) [0|0] "" BMS_12V,DSMU,METER,PBD,PSCU,RSCU2R,RSCU3R,SCCM
  SG_ SIGMA_DTCBMS_HV : 39|24@0+ (1,0) [0|0] "" BMS_12V,DSMU,METER,PBD,PSCU,RSCU2R,RSCU3R,SCCM

BO_ 2563508207 SIGMA_INV_HSGTriggerFrame: 7 BCM
  SG_ SIGMA_INV_HSG : 4|29@0+ (1,0) [0|0] "" BMS_12V,DSMU,METER,PBD,PSCU,RSCU2R,RSCU3R,SCCM
  SG_ SIGMA_DTCINV_HSG : 39|24@0+ (1,0) [0|0] "" BMS_12V,DSMU,METER,PBD,PSCU,RSCU2R,RSCU3R,SCCM

BO_ 2563567883 SIGMA_BMS_12VTriggerFrame: 7 BMS_12V
  SG_ SIGMA_BMS_12V : 4|29@0+ (1,0) [0|0] "" BCM,DSMU,METER,PBD,PSCU,RSCU2R,RSCU3R,SCCM
  SG_ SIGMA_DTCBMS_12V : 39|24@0+ (1,0) [0|0] "" BCM,DSMU,METER,PBD,PSCU,RSCU2R,RSCU3R,SCCM

BO_ 2563567951 SIGMA_EPS_subTriggerFrame: 7 BCM
  SG_ SIGMA_EPS_sub : 4|29@0+ (1,0) [0|0] "" BMS_12V,DSMU,METER,PBD,PSCU,RSCU2R,RSCU3R,SCCM
  SG_ SIGMA_DTCEPS_sub : 39|24@0+ (1,0) [0|0] "" BMS_12V,DSMU,METER,PBD,PSCU,RSCU2R,RSCU3R,SCCM

BO_ 2563567958 SIGMA_eShiftActTriggerFrame: 7 BCM
  SG_ SIGMA_eShiftAct : 4|29@0+ (1,0) [0|0] "" BMS_12V,DSMU,METER,PBD,PSCU,RSCU2R,RSCU3R,SCCM
  SG_ SIGMA_DTCeShiftAct : 39|24@0+ (1,0) [0|0] "" BMS_12V,DSMU,METER,PBD,PSCU,RSCU2R,RSCU3R,SCCM

BO_ 2563567968 SIGMA_HUDTriggerFrame: 7 BCM
  SG_ SIGMA_HUD : 4|29@0+ (1,0) [0|0] "" BMS_12V,DSMU,METER,PBD,PSCU,RSCU2R,RSCU3R,SCCM
  SG_ SIGMA_DTCHUD : 39|24@0+ (1,0) [0|0] "" BMS_12V,DSMU,METER,PBD,PSCU,RSCU2R,RSCU3R,SCCM

BO_ 2563568024 SIGMA_HPCUTriggerFrame: 7 BCM
  SG_ SIGMA_HPCU : 4|29@0+ (1,0) [0|0] "" BMS_12V,DSMU,METER,PBD,PSCU,RSCU2R,RSCU3R,SCCM
  SG_ SIGMA_DTCHPCU : 39|24@0+ (1,0) [0|0] "" BMS_12V,DSMU,METER,PBD,PSCU,RSCU2R,RSCU3R,SCCM

BO_ 2563568093 SIGMA_DCDC_HVTriggerFrame: 7 BCM
  SG_ SIGMA_DCDC_HV : 4|29@0+ (1,0) [0|0] "" BMS_12V,DSMU,METER,PBD,PSCU,RSCU2R,RSCU3R,SCCM
  SG_ SIGMA_DTCDCDC_HV : 39|24@0+ (1,0) [0|0] "" BMS_12V,DSMU,METER,PBD,PSCU,RSCU2R,RSCU3R,SCCM

BO_ 2563568098 SIGMA_EBATriggerFrame: 7 BCM
  SG_ SIGMA_EBA : 4|29@0+ (1,0) [0|0] "" BMS_12V,DSMU,METER,PBD,PSCU,RSCU2R,RSCU3R,SCCM
  SG_ SIGMA_DTCEBA : 39|24@0+ (1,0) [0|0] "" BMS_12V,DSMU,METER,PBD,PSCU,RSCU2R,RSCU3R,SCCM

BO_ 2563568101 SIGMA_INV_RETriggerFrame: 7 BCM
  SG_ SIGMA_INV_RE : 4|29@0+ (1,0) [0|0] "" BMS_12V,DSMU,METER,PBD,PSCU,RSCU2R,RSCU3R,SCCM
  SG_ SIGMA_DTCINV_RE : 39|24@0+ (1,0) [0|0] "" BMS_12V,DSMU,METER,PBD,PSCU,RSCU2R,RSCU3R,SCCM

BO_ 2563568130 SIGMA_AirSUSPTriggerFrame: 7 BCM
  SG_ SIGMA_AirSUSP : 4|29@0+ (1,0) [0|0] "" BMS_12V,DSMU,METER,PBD,PSCU,RSCU2R,RSCU3R,SCCM
  SG_ SIGMA_DTCAirSUSP : 39|24@0+ (1,0) [0|0] "" BMS_12V,DSMU,METER,PBD,PSCU,RSCU2R,RSCU3R,SCCM

BO_ 2563568148 SIGMA_BSGTriggerFrame: 7 BCM
  SG_ SIGMA_BSG : 4|29@0+ (1,0) [0|0] "" BMS_12V,DSMU,METER,PBD,PSCU,RSCU2R,RSCU3R,SCCM
  SG_ SIGMA_DTCBSG : 39|24@0+ (1,0) [0|0] "" BMS_12V,DSMU,METER,PBD,PSCU,RSCU2R,RSCU3R,SCCM

BO_ 2563568163 SIGMA_SRad_FL_TriggerFrame: 7 BCM
  SG_ SIGMA_SRad_FL : 4|29@0+ (1,0) [0|0] "" BMS_12V,DSMU,METER,PBD,PSCU,RSCU2R,RSCU3R,SCCM
  SG_ SIGMA_DTCSRad_FL : 39|24@0+ (1,0) [0|0] "" BMS_12V,DSMU,METER,PBD,PSCU,RSCU2R,RSCU3R,SCCM

BO_ 2563568164 SIGMA_SRad_FRTriggerFrame: 7 BCM
  SG_ SIGMA_SRad_FR : 4|29@0+ (1,0) [0|0] "" BMS_12V,DSMU,METER,PBD,PSCU,RSCU2R,RSCU3R,SCCM
  SG_ SIGMA_DTCSRad_FR : 39|24@0+ (1,0) [0|0] "" BMS_12V,DSMU,METER,PBD,PSCU,RSCU2R,RSCU3R,SCCM

BO_ 2563568201 SIGMA_STBWTriggerFrame: 7 BCM
  SG_ SIGMA_STBW : 4|29@0+ (1,0) [0|0] "" BMS_12V,DSMU,METER,PBD,PSCU,RSCU2R,RSCU3R,SCCM
  SG_ SIGMA_DTCSTBW : 39|24@0+ (1,0) [0|0] "" BMS_12V,DSMU,METER,PBD,PSCU,RSCU2R,RSCU3R,SCCM

BO_ 2563568233 SIGMA_DMCTriggerFrame: 7 BCM
  SG_ SIGMA_DMC : 4|29@0+ (1,0) [0|0] "" BMS_12V,DSMU,METER,PBD,PSCU,RSCU2R,RSCU3R,SCCM
  SG_ SIGMA_DTCDMC : 39|24@0+ (1,0) [0|0] "" BMS_12V,DSMU,METER,PBD,PSCU,RSCU2R,RSCU3R,SCCM

BO_ 2563568267 SIGMA_RSCU3RTriggerFrame: 7 RSCU3R
  SG_ SIGMA_RSCU3R : 4|29@0+ (1,0) [0|0] "" BCM,BMS_12V,DSMU,METER,PBD,PSCU,RSCU2R,SCCM
  SG_ SIGMA_DTCRSCU3R : 39|24@0+ (1,0) [0|0] "" BCM,BMS_12V,DSMU,METER,PBD,PSCU,RSCU2R,SCCM

BO_ 2563568288 SIGMA_BLM_RPKTriggerFrame: 7 BCM
  SG_ SIGMA_BLM_RPK : 4|29@0+ (1,0) [0|0] "" BMS_12V,DSMU,METER,PBD,PSCU,RSCU2R,RSCU3R,SCCM
  SG_ SIGMA_DTCBLM_RPK : 39|24@0+ (1,0) [0|0] "" BMS_12V,DSMU,METER,PBD,PSCU,RSCU2R,RSCU3R,SCCM

BO_ 2563568290 SIGMA_SCCMTriggerFrame: 7 SCCM
  SG_ SIGMA_SCCM : 4|29@0+ (1,0) [0|0] "" BCM,BMS_12V,DSMU,METER,PBD,PSCU,RSCU2R,RSCU3R
  SG_ SIGMA_DTCSCCM : 39|24@0+ (1,0) [0|0] "" BCM,BMS_12V,DSMU,METER,PBD,PSCU,RSCU2R,RSCU3R

BO_ 2563568300 SIGMA_RSCU2RTriggerFrame: 7 RSCU2R
  SG_ SIGMA_RSCU2R : 4|29@0+ (1,0) [0|0] "" BCM,BMS_12V,DSMU,METER,PBD,PSCU,RSCU3R,SCCM
  SG_ SIGMA_DTCRSCU2R : 39|24@0+ (1,0) [0|0] "" BCM,BMS_12V,DSMU,METER,PBD,PSCU,RSCU3R,SCCM

BO_ 2563639091 SIGMA_PBD_ReadMeReq_Frame: 8 PBD
  SG_ SIGMA_PBD_ReadMeReqRDIAG : 7|64@0+ (1,0) [0|0] "" BCM

BO_ 2564426737 DTOOL_to_BMS12Vextd: 8 BCM
  SG_ DTOOL_to_BMS12Vextd : 7|64@0+ (1,0) [0|0] "" BMS_12V

BO_ 2564447986 DTOOL_to_PSB_P: 8 BCM
  SG_ DTOOL_to_PSB_P : 7|64@0+ (1,0) [0|0] "" PSB_P

BO_ 2564459506 DTOOL_to_RSCU3R: 8 BCM
  SG_ DTOOL_to_RSCU3R : 7|64@0+ (1,0) [0|0] "" RSCU3R

BO_ 2564465394 DTOOL_to_SCCM: 8 BCM
  SG_ DTOOL_to_SCCM : 7|64@0+ (1,0) [0|0] "" SCCM

BO_ 2564467954 DTOOL_to_RSCU: 8 BCM
  SG_ DTOOL_to_RSCU : 7|64@0+ (1,0) [0|0] "" RSCU2R

BO_ 2564468210 DTOOL_to_CMS_P: 8 BCM
  SG_ DTOOL_to_CMS_P : 7|64@0+ (1,0) [0|0] "" CMS_P

BO_ 2564468466 DTOOL_to_CMS_D: 8 BCM
  SG_ DTOOL_to_CMS_D : 7|64@0+ (1,0) [0|0] "" CMS_D

BO_ 2564485387 BMS12Vextd_to_DTOOL: 8 BMS_12V
  SG_ BMS12Vextd_to_DTOOL : 7|64@0+ (1,0) [0|0] "" BCM

BO_ 2564485726 PSB_P_to_DTOOL: 8 PSB_P
  SG_ PSB_P_to_DTOOL : 7|64@0+ (1,0) [0|0] "" BCM

BO_ 2564485771 RSCU3R_to_DTOOL: 8 RSCU3R
  SG_ RSCU3R_to_DTOOL : 7|64@0+ (1,0) [0|0] "" BCM

BO_ 2564485794 SCCM_to_DTOOL: 8 SCCM
  SG_ SCCM_to_DTOOL : 7|64@0+ (1,0) [0|0] "" BCM

BO_ 2564485804 RSCU_to_DTOOL: 8 RSCU2R
  SG_ RSCU_to_DTOOL : 7|64@0+ (1,0) [0|0] "" BCM

BO_ 2564485805 CMS_P_to_DTOOL: 8 CMS_P
  SG_ CMS_P_to_DTOOL : 7|64@0+ (1,0) [0|0] "" BCM

BO_ 2564485806 CMS_D_to_DTOOL: 8 CMS_D
  SG_ CMS_D_to_DTOOL : 7|64@0+ (1,0) [0|0] "" BCM

BO_ 2609102849 DSMU_WakeUpFrame: 2 DSMU
  SG_ DSMU_WakeUp_Signal : 7|16@0+ (1,0) [0|0] "" BCM

BO_ 2609102850 PSCU_WakeUpFrame: 2 PSCU
  SG_ PSCU_WakeUp_Signal : 7|16@0+ (1,0) [0|0] "" BCM

BO_ 2609102851 SCCM_WakeUpFrame: 2 SCCM
  SG_ SCCM_WakeUp_Signal : 7|16@0+ (1,0) [0|0] "" BCM

BO_ 2609102861 BCM_WakeUpFrame_V2_extd: 2 BCM
  SG_ BCM_WakeUp_Signal : 7|16@0+ (1,0) [0|0] "" METER

BO_ 2609102865 RSCU2R_WakeUpFrame_extd: 2 RSCU2R
  SG_ RSCU2R_WakeUp_Signal : 7|16@0+ (1,0) [0|0] "" BCM

BO_ 2609102868 RSCU3R_WakeUpFrame_extd: 2 RSCU3R
  SG_ RSCU3R_WakeUp_Signal : 7|16@0+ (1,0) [0|0] "" BCM

BO_ 2615038450 FTOOLS_CGWtoMETER: 8 BCM
  SG_ FTOOLS_CGWtoMETER : 7|64@0+ (1,0) [0|0] "" METER

BO_ 2615079505 FTOOLS_METERtoCGW: 8 METER
  SG_ FTOOLS_METERtoCGW : 7|64@0+ (1,0) [0|0] "" BCM

VAL_ 1530 BSWson_ActivationRequest 0 "No request" 1 "Activation request" 2 "Deactivation request" 3 "Reset request";
VAL_ 1530 BCI_ActivationRequest 0 "No request" 1 "Activation" 2 "Deactivation" 3 "Reset request";
VAL_ 1530 HUD_TurnByTurnActivationRequest 0 "No request" 1 "Activation request" 2 "De-activation request" 3 "Reset request";
VAL_ 1530 HUD_ADASactivationRequest 0 "No request" 1 "Activation request" 2 "De-activation request" 3 "Reset request";
VAL_ 1530 HUD_TSRactivationRequest 0 "No request" 1 "Activation request" 2 "De-activation request" 3 "Reset request";
VAL_ 1530 HUD_ITactivationRequest 0 "No request" 1 "Activation request" 2 "De-activation request" 3 "Reset request";
VAL_ 1530 ELKA_ActivationRequest 0 "No request" 1 "Activation" 2 "Deactivation" 3 "Reset request";
VAL_ 1530 FCW_SensibilityRequest 0 "No Request" 1 "Early" 2 "Standard" 3 "Late" 4 "ResetRequest" 5 "Not used" 6 "Not used" 7 "Not used";
VAL_ 1530 HUD_DayLuminosityRequest 0 "No Request" 1 "Step 1" 2 "Step 2" 3 "Step 3" 4 "Step 4" 5 "Step 5" 6 "Step 6" 7 "Step 7" 8 "Step 8" 9 "Step 9" 10 "Step 10" 11 "Step 11" 12 "Step 12" 13 "Step 13" 14 "Step 14" 15 "Step 15" 16 "Step 16" 17 "Step 17" 18 "Step 18" 19 "Step 19" 20 "Step 20" 21 "Step 21" 22 "Not used" 23 "Not used" 24 "Not used" 25 "Not used" 26 "Not used" 27 "Not used" 28 "Not used" 29 "Not used" 30 "Not used" 31 "Reset request";
VAL_ 1530 SSAactivationRequest 0 "No request" 1 "Deactivation request" 2 "UpHill request" 3 "All request" 4 "Not used" 5 "Not used" 6 "Not used" 7 "Reset request";
VAL_ 1530 HUD_NightLuminosityRequest 0 "No Request" 1 "Step 1" 2 "Step 2" 3 "Step 3" 4 "Step 4" 5 "Step 5" 6 "Step 6" 7 "Step 7" 8 "Step 8" 9 "Step 9" 10 "Step 10" 11 "Step 11" 12 "Step 12" 13 "Step 13" 14 "Step 14" 15 "Step 15" 16 "Step 16" 17 "Step 17" 18 "Step 18" 19 "Step 19" 20 "Step 20" 21 "Step 21" 22 "Not used" 23 "Not used" 24 "Not used" 25 "Not used" 26 "Not used" 27 "Not used" 28 "Not used" 29 "Not used" 30 "Not used" 31 "Reset request";
VAL_ 1530 EAP_ActivationRequest 0 "No request" 1 "Activation request" 2 "Deactivation request" 3 "Reset request";
VAL_ 1530 WDA_ActivationRequest 0 "No request" 1 "Activation request" 2 "Deactivation request" 3 "Reset request";
VAL_ 1530 ASAactivationRequest 0 "No request" 1 "Activation" 2 "Deactivation" 3 "Reset request";
VAL_ 1530 ADA1ActivationRequest 0 "No request" 1 "Activation" 2 "Deactivation" 3 "Reset request";
VAL_ 1530 WAL_ActivationRequest 0 "No request" 1 "WAL activation request" 2 "WAL deactivation request" 3 "WAL factory setting reset request";
VAL_ 1530 RAB_ActivationRequest 0 "No request" 1 "Activation request" 2 "Deactivation request" 3 "Reset Request";
VAL_ 1530 NoEntry_ActivationRequest 0 "No request" 1 "NoEntry ON request" 2 "NoEntry OFF request" 3 "Reset Requested";
VAL_ 1530 VDCactivationRequest 0 "No request" 1 "VDC function activation" 2 "VDC function deactivation" 3 "Reset request";
VAL_ 1530 APPRUN_ActivationRequest 0 "No Request" 1 "Approach Unlock activation request" 2 "Approach Unlock deactivation request" 3 "Approach Unlock Factory setting reset request";
VAL_ 1533 PowerTrainSettingRequest 0 "No request" 1 "Mode1 (Standard)" 2 "Mode2 (Sport)" 3 "Mode3 (Eco)" 4 "Mode4 (Snow)" 5 "Mode5" 6 "Mode6" 7 "Mode7" 8 "Mode8" 9 "Mode9" 10 "Mode10" 11 "Mode11" 12 "Mode12" 13 "Mode13" 14 "Mode14" 15 "Reset request";
VAL_ 1533 SteeringSettingRequest_v2 0 "No request" 1 "Mode EPS 1 Normal / Normal" 2 "Mode EPS 2 Normal / Confort" 3 "Mode EPS 3 Normal / Sport" 4 "Mode EPS 4" 5 "Mode EPS 5 Casual / Normal" 6 "Mode EPS 6 Casual / Confort" 7 "Mode EPS 7 Casual / Sport" 8 "Mode EPS 8" 9 "Mode EPS 9 Quick / Normal" 10 "Mode EPS 10 Quick / Confort" 11 "Mode EPS 11 Quick / Sport" 12 "Mode EPS 12" 13 "Mode EPS 13" 14 "According to DriveMode" 15 "Reset request";
VAL_ 1533 SuspensionSettingRequest 0 "No request" 1 "Mode VADA 1 (Normal)" 2 "Mode VADA 2 (Comfort)" 3 "Mode VADA 3 (Sport)" 4 "Mode VADA 4" 5 "Mode VADA 5" 6 "Mode VADA 6 (Race)" 7 "Reset request";
VAL_ 1533 AWDSettingRequest 0 "No request" 1 "Mode 1" 2 "Mode 2" 3 "Mode 3" 4 "Mode 4" 5 "Mode 5" 6 "Mode 6" 7 "Reset Request";
VAL_ 1533 V2X_Meter_MainSwitchState 0 "Main Switch OFF" 1 "Main Switch ON";
VAL_ 1533 AmbientLightingColor_v3_METER 0 "No request" 1 "Color 1" 2 "Color 2" 3 "Color 3" 4 "Color 4" 5 "Color 5" 6 "Color 6" 7 "Color 7" 8 "Color 8" 9 "Color 9" 10 "Color 10" 11 "Color 11" 12 "Color 12" 13 "Color 13" 14 "Color 14" 15 "Color 15" 16 "Color 16" 17 "Color 17" 18 "Color 18" 19 "Color 19" 20 "Color 20" 21 "Color 21" 22 "Color 22" 23 "Color 23" 24 "Color 24" 25 "Color 25" 26 "Color 26" 27 "Color 27" 28 "Color 28" 29 "Color 29" 30 "Color 30" 31 "Color 31" 32 "Color 32" 33 "Color 33" 34 "Color 34" 35 "Color 35" 36 "Color 36" 37 "Color 37" 38 "Color 38" 39 "Color 39" 40 "Color 40" 41 "Color 41" 42 "Color 42" 43 "Color 43" 44 "Color 44" 45 "Color 45" 46 "Color 46" 47 "Color 47" 48 "Color 48" 49 "Color 49" 50 "Color 50" 51 "Color 51" 52 "Color 52" 53 "Color 53" 54 "Color 54" 55 "Color 55" 56 "Color 56" 57 "Color 57" 58 "Color 58" 59 "Color 59" 60 "Color 60" 61 "Color 61" 62 "Color 62" 63 "Color 63" 64 "Color 64" 65 "Color 65" 66 "Color 66" 67 "Color 67" 68 "Color 68" 69 "Color 69" 70 "Color 70" 71 "Color 71" 72 "Color 72" 73 "Color 73" 74 "Color 74" 75 "Color 75" 76 "Color 76" 77 "Color 77" 78 "Color 78" 79 "Color 79" 80 "Color 80" 81 "Color 81" 82 "Color 82" 83 "Color 83" 84 "Color 84" 85 "Color 85" 86 "Color 86" 87 "Color 87" 88 "Color 88" 89 "Color 89" 90 "Color 90" 91 "Color 91" 92 "Color 92" 93 "Color 93" 94 "Color 94" 95 "Color 95" 96 "Color 96" 97 "Color 97" 98 "Color 98" 99 "Color 99" 100 "Color 100" 101 "Color 101" 102 "Color 102" 103 "Color 103" 104 "Color 104" 105 "Color 105" 106 "Color 106" 107 "Color 107" 108 "Color 108" 109 "Color 109" 110 "Color 110" 111 "Color 111" 112 "Color 112" 113 "Color 113" 114 "Color 114" 115 "Color 115" 116 "Color 116" 117 "Color 117" 118 "Color 118" 119 "Color 119" 120 "Color 120" 121 "Color 121" 122 "Color 122" 123 "Color 123" 124 "Color 124" 125 "Color 125" 126 "Color 126" 127 "Reset Request";
VAL_ 1533 VMCsettingRequest2 0 "No request" 1 "Mode1" 2 "Mode2" 3 "Mode3" 4 "Mode4" 5 "Mode5" 6 "Mode6" 7 "Mode7" 8 "Mode8" 9 "Mode9" 10 "Mode10" 11 "Mode11" 12 "Mode12" 13 "Mode13" 14 "Mode14" 15 "Reset request";
VAL_ 1533 AmbientLightingActivationReq2 0 "No Request" 1 "AmbientLighting Activation request" 2 "AmbientLighting Deactivation request" 3 "Reset request";
VAL_ 1533 RegenerationSettingRequest 0 "No request" 1 "Mode 1" 2 "Mode 2" 3 "Mode 3" 4 "Mode 4" 5 "Mode 5" 6 "Mode 6" 7 "Mode 7" 8 "Mode 8" 9 "Mode 9" 10 "Mode 10" 11 "Mode 11" 12 "Mode 12" 13 "Mode 13" 14 "Mode 14" 15 "Reset request";
VAL_ 1533 OEMmodeMenuRequest 0 "No request" 1 "No roller bench mode" 2 "4WD Dyno Mode" 3 "FWD Dyno Mode" 4 "RWD Dyno Mode" 5 "ICE forced dyno mode" 6 "OEM Mode 5" 7 "OEM Mode 6" 8 "OEM Mode 7" 9 "OEM Mode 8" 10 "OEM Mode 9" 11 "OEM Mode 10" 12 "OEM Mode 11" 13 "OEM Mode 12" 14 "OEM Mode 13" 15 "Unavailable";
VAL_ 1533 V2X_Meter_SubSwitchState 0 "Table Value221793";
VAL_ 1533 AutoEngShutOffAcknowledgement 0 "No Request" 1 "Activate Request" 2 "Deactivate Request" 3 "Not Used";
VAL_ 1537 NoEntry_AlertDisplay 0 "No Alert" 1 "Alert";
VAL_ 1537 NoEntry_ActivationState 0 "Activated" 1 "De-activated";
VAL_ 1537 ADAS_ModeDisplay 0 "Cruise Control mode" 1 "Adaptive Cruise Control mode" 2 "TJP mode" 3 "Unavailable";
VAL_ 1537 NoEntry_Alert 0 "No Alert" 1 "Alert";
VAL_ 1537 ACC_TargetDistanceAlert 0 "No ACC warning" 1 "ACC approach warning" 2 "ACC collision warning" 3 "ACC cancel warning";
VAL_ 1537 ACC_DistanceOverrideDisplay 0 "No override" 1 "Override";
VAL_ 1537 ACC_SpeedOverrideDisplay 0 "No override" 1 "Override";
VAL_ 1537 ACC_TargetDistanceDisplay 0 "No detected target" 1 "Long detected distance" 2 "Middle detected distance" 3 "Short detected distance" 4 "Reglementary detected distance" 5 "Reserved" 6 "Reserved" 7 "Reserved";
VAL_ 1537 ACC_DistanceSettingDisplay 0 "No display" 1 "Short distance" 2 "Middle distance" 3 "Long distance" 4 "Reglementary detected distance" 5 "Very long distance" 6 "Reserved" 7 "Reserved";
VAL_ 1537 LCA_FailureDisplay 0 "No display" 1 "Temporary failure display" 2 "Permanent failure display" 3 "Not used";
VAL_ 1537 LCA_OverrideDisplay 0 "No override" 1 "Override";
VAL_ 1537 LCA_SteeringWheelDisplay 0 "Not active - Cancel" 1 "Not active - Temporary Cancel" 2 "Active" 3 "Not used";
VAL_ 1537 LCA_ActivationState 0 "Activated" 1 "Deactivated";
VAL_ 1537 LDP_StatusDisplay 0 "No display" 1 "Not operational" 2 "Operational" 3 "Not used";
VAL_ 1537 LDP_LaneDisplay 0 "No display" 1 "Right lane monitoring" 2 "Left lane monitoring" 3 "Right and left lane monitoring";
VAL_ 1537 LDP_AlertStatus 0 "No alert" 1 "Right alert" 2 "Left alert" 3 "Not used";
VAL_ 1537 LCA_SoundAlert 0 "Not requested" 1 "Requested";
VAL_ 1537 ContextSpeed_ActivationState 0 "Unavailable" 1 "AutoMode OFF" 2 "AutoMode ON" 3 "Prompt mode activated";
VAL_ 1537 ContextRoad_ActivationState 0 "AutoMode OFF" 1 "AutoMode ON" 2 "Not Used" 3 "Unavailable";
VAL_ 1537 DriverGuideDisplay 0 "No display" 1 "Text 1 during system off status, request for guidance to display" 2 "Text 2 during activate, during system standby, request for guidance to display" 3 "Text 3 during active, request for guidance to display" 4 "Text 4 during standstill stop, request for guidance to display" 5 "Text 5 Request for guidance to change menu" 6 "Text 6 during autorestart, request for warning to display" 7 "Text7 Limitation of ACC set speed to EV max speed";
VAL_ 1538 BCI_AlertStatus_v2 0 "No alert" 1 "Alert";
VAL_ 1538 BSI_SideDisplay 0 "No monitoring" 1 "Left and right side monitoring";
VAL_ 1538 BCI_SoundAlert 0 "Not requested" 1 "requested";
VAL_ 1538 BCI_OffdisplayRequest 0 "No request" 1 "Request";
VAL_ 1538 BCI_FailureDisplay 0 "No display" 1 "Temporary Failure Display" 2 "Permanent Failure Display" 3 "Not used";
VAL_ 1538 BSI_CancelReason 0 "No display" 1 "VDC desactivated by driver" 2 "VDC in regulation" 3 "Active Pedal HighTemp" 4 "Activation refused: Driving Aids not set" 5 "Not used" 6 "Not used" 7 "Not used";
VAL_ 1538 LKA_OvertimeAlert 0 "No Alert" 1 "Alert";
VAL_ 1538 LDW_AlertStatus 0 "No alert" 1 "Right alert" 2 "Left alert" 3 "Not used";
VAL_ 1538 BSI_AlertStatus 0 "No alert" 1 "Right alert" 2 "Left alert" 3 "Right and left alert";
VAL_ 1538 EAP_FailureDisplay 0 "No failure" 1 "Temporary failure" 2 "Permanent failure" 3 "Not used";
VAL_ 1538 EAP_AlertDisplay 0 "No display" 1 "Alert display";
VAL_ 1538 BSI_StatusDisplay 0 "No display" 1 "Not operational" 2 "Operational" 3 "Not used";
VAL_ 1538 BSI_SideRadarCancelReason 0 "No display" 1 "Side radar blocked" 2 "Reserved" 3 "Side Radar permanent failure";
VAL_ 1538 LDP_CancelReason 0 "No display" 1 "VDC desactivated by driver" 2 "VDC in regulation" 3 "Active Pedal HighTemp" 4 "Activation refused: Driving Aids not set" 5 "Not used" 6 "Not used" 7 "Not used";
VAL_ 1538 LCA_LineCrossingAlert 0 "No alert" 1 "Right alert" 2 "Left alert" 3 "RIght and left alert";
VAL_ 1538 RAB_CancelReason 0 "No display" 1 "VDC desactivated by driver" 2 "VDC in regulation" 3 "Active Pedal HighTemp" 4 "Reserved" 5 "Not used" 6 "Not used" 7 "Not used";
VAL_ 1538 RAB_AlertStatus 0 "No alert" 1 "Alert 1" 2 "Alert 2" 3 "Not used";
VAL_ 1538 RAB_ActivationState 0 "Activated" 1 "Deactivated";
VAL_ 1538 LDP_FailureDisplay 0 "No display" 1 "Temporary failure display" 2 "Permanent failure display" 3 "Not used";
VAL_ 1538 WDA_WarningDriverAttention 0 "No display" 1 "Warning Display";
VAL_ 1538 WDA_ActivationState 0 "Activated" 1 "Deactivated";
VAL_ 1538 RAB_StatusDisplay 0 "No display" 1 "Not operational" 2 "Operational" 3 "Not used";
VAL_ 1538 RAB_SonarCancelReason 0 "No display" 1 "Sonar blocked" 2 "Sonar obstructed" 3 "not used";
VAL_ 1538 RAB_FailureDisplay 0 "No display" 1 "Temporary failure display" 2 "Permanent failure display" 3 "Not used";
VAL_ 1538 ACC_TransitionStateDisplay 0 "No display" 1 "ACC user activation OFF.to.ON.Waiting" 2 "ACC user activation OFF.to.ON.InFailure" 3 "ACC user activation ON.Waiting.to.ON.Active" 4 "ACC user activation by SETSW : ON.Suspended.to.ON.Active" 5 "ACC user activation by RESSW : ON.Suspended.to.ON.Active" 6 "ACC user deactivation ON.Active.to.ON.Suspended" 7 "Reserved" 8 "ACC_Disconnected_Level1" 9 "ACC_Disconnected_Level2" 10 "ACC_Deactivation_Level1" 11 "ACC_Deactivation_Level2" 12 "Contextual Prompt to Auto Mode" 13 "Contextual Auto to Prompt Mode" 14 "Contextual Event Speed" 15 "Contextual Event Type";
VAL_ 1538 WDA_DriverAttentionLevel 0 "No display" 1 "System OFF" 2 "Level 1" 3 "Level 2" 4 "Level 3" 5 "Level 4" 6 "Level 5" 7 "Level 6" 8 "Level 7" 9 "Level 8" 10 "Indicator check" 11 "Not used" 12 "Not used" 13 "Not used" 14 "System stand by" 15 "System malfunction";
VAL_ 1539 ATODCancelCVTSport_IndicateReq 0 "No Display request" 1 "Display request";
VAL_ 1539 ATCVT_WarningMessage5 0 "No Request" 1 "ATCVT Warning Message5";
VAL_ 1539 ATCVT_WarningMessage4 0 "No Request" 1 "ATCVT Warning Message4";
VAL_ 1539 ATCVT_WarningMessage3 0 "No Request" 1 "ATCVT Warning Message3";
VAL_ 1539 ShBW_ReverseMessage 0 "No Request" 1 "ShBW_ReverseMessage";
VAL_ 1539 ShBW_RangeRefusedRER 0 "No Request" 1 "ReEmission request";
VAL_ 1539 ShBW_RangeRefused 0 "No Request" 1 "Shift change refused Brake OFF" 2 "Shift change to R refused Forward Move" 3 "Shift change to D refused Backward Move" 4 "Shift change to P refused Forward/Backward Move" 5 "Shift change to P Multi-Switch operated with P" 6 "Shift change to N Multi-Switch operated without P" 7 "Not used";
VAL_ 1539 TOWmodeIndicatorRequest 0 "No TOW mode indicator request" 1 "TOW mode indicator request";
VAL_ 1539 ParkingBrakeRequestDisplay 0 "Parking brake not requested" 1 "Parking brake requested";
VAL_ 1539 ATCVT_ATFChangeMessageRequest 0 "No request(No display)" 1 "Request(Change AT Fluid)";
VAL_ 1543 WiperWithSpeedActivationState 0 "Activated" 1 "De-activated";
VAL_ 1543 SilentModeActivationState 0 "Silent mode is Deactivated" 1 "Silent mode is Activated";
VAL_ 1543 ADB_ActivationStatusDisplay 0 "ADB not activated" 1 "ADB activated";
VAL_ 1543 AmbiLightColorStatus_v2 0 "Color 1" 1 "Color 2" 2 "Color 3" 3 "Color 4" 4 "Color 5" 5 "Color 6" 6 "Color 7" 7 "Color 8" 8 "Color 9" 9 "Color 10" 10 "Color 11" 11 "Color 12" 12 "Color 13" 13 "Color 14" 14 "Color 15" 15 "Color 16" 16 "Color 17" 17 "Color 18" 18 "Color 19" 19 "Color 20" 20 "Color 21" 21 "Color 22" 22 "Color 23" 23 "Color 24" 24 "Color 25" 25 "Color 26" 26 "Color 27" 27 "Color 28" 28 "Color 29" 29 "Color 30" 30 "Color 31" 31 "Color 32" 32 "Color 33" 33 "Color 34" 34 "Color 35" 35 "Color 36" 36 "Color 37" 37 "Color 38" 38 "Color 39" 39 "Color 40" 40 "Color 41" 41 "Color 42" 42 "Color 43" 43 "Color 44" 44 "Color 45" 45 "Color 46" 46 "Color 47" 47 "Color 48" 48 "Color 49" 49 "Color 50" 50 "Color 51" 51 "Color 52" 52 "Color 53" 53 "Color 54" 54 "Color 55" 55 "Color 56" 56 "Color 57" 57 "Color 58" 58 "Color 59" 59 "Color 60" 60 "Color 61" 61 "Color 62" 62 "Color 63" 63 "Color 64" 64 "Color 65" 65 "Color 66" 66 "Color 67" 67 "Color 68" 68 "Color 69" 69 "Color 70" 70 "Color 71" 71 "Color 72" 72 "Color 73" 73 "Color 74" 74 "Color 75" 75 "Color 76" 76 "Color 77" 77 "Color 78" 78 "Color 79" 79 "Color 80" 80 "Color 81" 81 "Color 82" 82 "Color 83" 83 "Color 84" 84 "Color 85" 85 "Color 86" 86 "Color 87" 87 "Color 88" 88 "Color 89" 89 "Color 90" 90 "Color 91" 91 "Color 92" 92 "Color 93" 93 "Color 94" 94 "Color 95" 95 "Color 96" 96 "Color 97" 97 "Color 98" 98 "Color 99" 99 "Color 100" 100 "Color 101" 101 "Color 102" 102 "Color 103" 103 "Color 104" 104 "Color 105" 105 "Color 106" 106 "Color 107" 107 "Color 108" 108 "Color 109" 109 "Color 110" 110 "Color 111" 111 "Color 112" 112 "Color 113" 113 "Color 114" 114 "Color 115" 115 "Color 116" 116 "Color 117" 117 "Color 118" 118 "Color 119" 119 "Color 120" 120 "Color 121" 121 "Color 122" 122 "Color 123" 123 "Color 124" 124 "Color 125" 125 "Color 126" 126 "Color 127" 127 "Color 128";
VAL_ 1543 StopReloadMMI 0 "No display" 1 "Long push request" 2 "Short push request" 3 "Not Used";
VAL_ 1548 FuelLidStatus 0 "Lid open" 1 "Lid close";
VAL_ 1548 RefuelingDisplay 0 "No request" 1 "Preparing for refueling" 2 "Ready for refueling" 3 "Service, see owner's manuel for refueling" 4 "Switch off engine before refueling" 5 "Fuel lid opened" 6 "Not Used" 7 "Not Used";
VAL_ 1549 DriverSwitchMassageRequest 0 "No massage request" 1 "Massage Request";
VAL_ 1549 MC_TutoControlsInhibitionReq 0 "No request" 1 "Controls inhibition request";
VAL_ 1549 MC_SeatAtSecureStopDisplayReq 0 "No display request" 1 "Seat at X secure stop" 2 "seat beyond secure stop Magic cockpit is now OFF" 3 "Seat at X secure stop Tuto will be reset to do it again" 4 "Not used" 5 "Not used" 6 "Not used" 7 "Not used";
VAL_ 1553 ClimEVmodeAdviceForHeating 0 "No display" 1 "Heating not available, turn OFF EV mode" 2 "Heating not available, with EV mode ON" 3 "Heating perf decrease, turn OFF EV mode" 4 "Heating perf decrease, with EV mode ON" 5 "Heating perf decrease, in charge, with low temperature" 6 "Not used" 7 "Not used";
VAL_ 1564 TractionModeStatusDisplay 0 "No Display" 1 "Hybrid" 2 "Electric" 3 "Battery save" 4 "Battery Charge" 5 "Not Used" 6 "Not Used" 7 "Not Used";
VAL_ 1564 ReacheableUSOCatDepartureTimeAl 0 "No Alert" 1 "Alert";
VAL_ 1564 SaveTractionModeAvailability 0 "No Display" 1 "Available";
VAL_ 1564 ChargeTractionModeAvailability 0 "No Display" 1 "Available";
VAL_ 1564 ZEVTractionModeAvailability 0 "No Display" 1 "Available";
VAL_ 1564 TractionModeStatusDisplayAct 0 "No Display" 1 "Display";
VAL_ 1565 PowerTrainAlertDisplay 0 "No Alert" 1 "HV power reduced stop safety alert" 2 "HV power reduced alert" 3 "HV system off Stop safety alert" 4 "HV system off alert" 5 "HV system stop safety alert" 6 "HV system alert" 7 "HV system apply parking brake" 8 "12V apply parking brake" 9 "12V Stop safety" 10 "12V power reduced stop safety" 11 "12V HV system off stop safety" 12 "12V HV system off" 13 "12V charging system" 14 "12V power reduced alert" 15 "Not used";
VAL_ 1565 EngineMotoringDisplay 0 "No display" 1 "Engine Motoring";
VAL_ 1565 HybridStartFailureAlert 0 "No alert" 1 "Unable to restart after pwr off";
VAL_ 1565 HVB_FailureAlertDisplayRequest 0 "No display request" 1 "Display request level 1" 2 "Display request level 2" 3 "Not used";
VAL_ 1565 HEV_SystemFailureDisplay_v2 0 "No failure" 1 "Failure" 2 "Maintenance mode" 3 "Failure and Emergency alert";
VAL_ 1570 OpenChargeFlapWarning 0 "Charging flap not opened" 1 "Charging flap opened";
VAL_ 1570 RIsolFailureAlert 0 "No alert" 1 "Alert";
VAL_ 1570 ElecMachineOverSpeed 0 "No Alert" 1 "Over Speed Alert";
VAL_ 1570 ZEVModeCancelMessage 0 "No alert" 1 "Canceled due to SPORT Mode On" 2 "Canceled due to L Range" 3 "Canceled due to ENG Too Cold" 4 "Canceled due to SOC Too Low" 5 "Canceled due to Speed Too High" 6 "Canceled due to Accel On" 7 "Canceled due to P Range" 8 "Canceled due to other reason" 9 "Canceled due to NOM Mode On" 10 "Not permit due to SPORT Mode On" 11 "Not permit due to L Range" 12 "Not permit due to ENG Too Cold" 13 "Not permit due to SOC Too Low" 14 "Not permit due to Speed Too High" 15 "Not permit due to Accel On" 16 "Not permit due to P Range" 17 "Not permit due to other reason" 18 "Not permit due to NOM Mode On" 19 "Not permit due to EV system too cold" 20 "Not permit due to Cruise Control set" 21 "Canceled due to EV system too cold" 22 "Canceled due to Cruise Control set" 23 "Charge mode/ Save mode not permit" 24 "Charge mode/ Save mode cancelled" 25 "Charge mode canceled due to NOM Mode selected" 26 "Charge mode not permit due to NOM Mode selected" 27 "Canceled due to Front defroster ON" 28 "Not permit due to Front defroster ON" 29 "Not used" 30 "Not used" 31 "Not used";
VAL_ 1570 PredictiveRegenActivationState 0 "Deactivated" 1 "Activated";
VAL_ 1570 PWT_PowerLimitationAlert 0 "No alert" 1 "Alert";
VAL_ 1570 ModeEcoIncitationPrompt 0 "No Ecomode incitation request" 1 "Ecomode incitation request";
VAL_ 1570 HybridColdStartAlert 0 "No alert" 1 "Alert";
VAL_ 1570 BMS_TiAlertDisplay 0 "No TI alert" 1 "TI alert";
VAL_ 1570 ParkBrakePositionRequestedDisplay 0 "No alert" 1 "Alert requested";
VAL_ 1570 ElectricalTractionAvailability 0 "EV traction available" 1 "EV traction soon not available" 2 "EV traction not available" 3 "Not used";
VAL_ 1570 CHGalertSpotCharge 0 "No Fault Type" 1 "Battery charge impossible with AC charge" 2 "Battery charge impossible with DC charge" 3 "Connexion Problem" 4 "Spot To Check" 5 "Power Supply Cutoff" 6 "Plug Signal lost" 7 "not used";
VAL_ 1571 ProgrammedChargeStatus_HEVC 0 "No display (default value)" 1 "Always authorized charge" 2 "Delayed charge" 3 "Programmed charge by Calendar" 4 "Smartcharging" 5 "AC V2G" 6 "Not Used" 7 "Not Used";
VAL_ 1571 OnePedal_PaddleInhibition_MMI 0 "No request" 1 "One pedal active - paddles inhibited";
VAL_ 1571 CauseOfSLOW_Lamp 0 "No alert" 1 "Overheat" 2 "Battery cold" 3 "Low SOC" 4 "Other" 5 "power suppression" 6 "speed down" 7 "Not used";
VAL_ 1572 EVModeDriverRequest 0 "No display" 1 "EV mode requested by driver";
VAL_ 1572 EnergyMode 0 "Hybride Mode SOC depleting" 1 "Hybride Mode SOC Constant" 2 "EV Mode" 3 "Not used";
VAL_ 1577 LOBM_PositionRecallRequest 0 "No request" 1 "RECALL LOB position 1" 2 "RECALL LOB position 2" 3 "RECALL LOB position 3" 4 "RECALL LOB position 4" 5 "RECALL LOB position 5" 6 "RECALL LOB position 6" 7 "Reset request";
VAL_ 1577 LOB_PositionChangeStatus 0 "Unavailable" 1 "LOB position 1" 2 "LOB position 2" 3 "LOB position 3" 4 "LOB position 4" 5 "LOB position 5" 6 "LOB position 6" 7 "Position Change on going";
VAL_ 1577 LOB_ActivationCondition 0 "Feature absent" 1 "EV LOB feature allowed" 2 "EV LOB feature not allowed" 3 "Not Used";
VAL_ 1577 DriverMemoryRecallState 0 "No request" 1 "Seat execute failed" 2 "Seat execute forbid" 3 "Seat executing" 4 "Seat execute forbid for not in P mode" 5 "Stop for not in P mode" 6 "Not used" 7 "Not used";
VAL_ 1577 DriverMemoryPopUpReq 0 "No request" 1 "Display request";
VAL_ 1577 DriverMemorySetState 0 "No request" 1 "Memory set forbid";
VAL_ 1577 LOBM_PositionSaveRequest 0 "No request" 1 "SAVE LOB position 1" 2 "SAVE LOB position 2" 3 "SAVE LOB position 3" 4 "SAVE LOB position 4" 5 "SAVE LOB position 5" 6 "SAVE LOB position 6" 7 "Not Used";
VAL_ 1577 DrMassageExecuteState 0 "No request" 1 "Massage execute failed" 2 "Massage execute forbid" 3 "Massage execute forbid for Ready OFF" 4 "Massage stop for Ready OFF" 5 "Not used" 6 "Not used" 7 "Not used";
VAL_ 1577 DriverLifterMotorErrorState 0 "Normal" 1 "Motor position lost";
VAL_ 1577 DriverReclinerMotorErrorState 0 "Normal" 1 "Motor position lost" 2 "Anti-pinch" 3 "Not used";
VAL_ 1577 DriverSlideMotorErrorState 0 "Normal" 1 "Motor position lost" 2 "Anti-pinch" 3 "Not used";
VAL_ 1577 SteeringTableModeRequest 0 "No request" 1 "Table Mode OFF" 2 "Table Mode ON" 3 "Not used";
VAL_ 1577 FrSeatMemoPopUpActivationState 0 "OFF" 1 "ON";
VAL_ 1577 DrMassagePopUpActivationState 0 "OFF" 1 "ON";
VAL_ 1578 Distraction_CancelReason 0 "No display" 1 "Camera temporary OBSTRUCTION" 2 "Camera temporary DIRTY" 3 "Camera temporary FACE MASKED" 4 "Camera temporary EYES MASKED" 5 "Camera temporary MASKED BY STEERING WHEEL" 6 "Camera temporary OVER HEAT" 7 "Camera permanent failure" 8 "Distraction permanent failure" 9 "Not used" 10 "Not used" 11 "Not used" 12 "Not used" 13 "Not used" 14 "Not used" 15 "Not used";
VAL_ 1578 Drowsy_AlertActivationState 0 "Unavailable" 1 "Activated" 2 "Deactivated" 3 "Not used";
VAL_ 1578 DriverPresence_CancelReason 0 "No display" 1 "Camera temporary OBSTRUCTION" 2 "Camera temporary DIRTY" 3 "Camera temporary FACE MASKED" 4 "Camera temporary EYES MASKED" 5 "Camera temporary MASKED BY STEERING WHEEL" 6 "Camera temporary OVER HEAT" 7 "Camera permanent failure" 8 "DriverPresence permanent failure" 9 "Not used" 10 "Not used" 11 "Not used" 12 "Not used" 13 "Not used" 14 "Not used" 15 "Not used";
VAL_ 1578 Distraction_CancelReasonRER 0 "No request" 1 "Reemission request";
VAL_ 1578 Sleepiness_CancelReasonRER 0 "No request" 1 "Reemission request";
VAL_ 1578 Sleepiness_CancelReason 0 "No display" 1 "Camera temporary OBSTRUCTION" 2 "Camera temporary DIRTY" 3 "Camera temporary FACE MASKED" 4 "Camera temporary EYES MASKED" 5 "Camera temporary MASKED BY STEERING WHEEL" 6 "Camera temporary OVER HEAT" 7 "Camera permanent failure" 8 "Sleepiness permanent failure" 9 "Not used" 10 "Not used" 11 "Not used" 12 "Not used" 13 "Not used" 14 "Not used" 15 "Not used";
VAL_ 1578 DriverPresence_CancelReasonRER 0 "No request" 1 "Reemission request";
VAL_ 1578 Distraction_AlertActivationState 0 "Unavailable" 1 "Activated" 2 "Deactivated" 3 "Not used";
VAL_ 1579 ISA_ActivationState 0 "ALL OFF" 1 "SLIF ON" 2 "SLIF ON + SLWF ON" 3 "Not used";
VAL_ 1579 ISA_ChoiceState 0 "ALL OFF" 1 "SLIF ON" 2 "SLIF ON + SLWF ON" 3 "Not used";
VAL_ 1579 SLIF_Notification_ChoiceState 0 "Not available" 1 "SpeedLimit Notification Activated" 2 "SpeedLimit Notification Deactivated" 3 "Not used";
VAL_ 1579 OverspeedAlertActivationStatus 0 "Deactivated" 1 "Activated" 2 "Not used" 3 "Unavailable";
VAL_ 1579 ISA_CameraCancelReason 0 "No display" 1 "Front Camera is blocked" 2 "Front Camera is overheat" 3 "ISA system failure" 4 "ISA Map update incomplete" 5 "Currently unavailable" 6 "Reserved" 7 "Reserved";
VAL_ 1579 ISA_FailureIcon 0 "Failure icon no display" 1 "Failure icon display";
VAL_ 1579 ISA_PartiallyOFF_icon_Signal 0 "Partially icon deactivated" 1 "Partially icon activated";
VAL_ 1579 ISA_OFF_icon_Signal 0 "OFF icon deactivated" 1 "OFF icon activated";
VAL_ 1583 ASE_SoundActivationStatus 0 "No Display" 1 "ASE_Sound_status activation" 2 "ASE_Sound_status deactivation" 3 "Not used";
VAL_ 1583 ASE_SoundvolumeState 0 "No Display" 1 "Low" 2 "Medium" 3 "High" 4 "Not used" 5 "Not used" 6 "Not used" 7 "Unavailable";
VAL_ 1585 HEV_ElecSysFailureDisplay 0 "No Alert" 1 "Alert";
VAL_ 1585 EDriveOverHeatAlert 0 "No alert" 1 "Alert level 1" 2 "Alert level 2" 3 "Unavailable";
VAL_ 1585 HybridTractionModeDisplay_v2 0 "No display" 1 "ZEV mode activated" 2 "Auto mode activated" 3 "Charge Battery" 4 "Sport mode activated" 5 "Temporary no ZEV" 6 "Save Battery level activated" 7 "Not used";
VAL_ 1585 FuelAgingPreAlertDisplay 0 "No Pre Alert" 1 "Fuel Aging Pre Alert level1 Display Requested" 2 "Fuel Aging Pre Alert level 2 Display Requested" 3 "Fuel Aging Pre Alert level 3 Display Requested" 4 "Unavailable" 5 "Not Used" 6 "Not Used" 7 "Not Used";
VAL_ 1585 ePedalMemorySettingStatus 0 "Memory Setting is OFF" 1 "Memory Setting is ON";
VAL_ 1585 FuelAgingRequestDisplay 0 "No Alert" 1 "Fuel Aging Display Requested";
VAL_ 1585 HVLowBatteryCrankingForbidden 0 "No Alert" 1 "Engine cranking forbidden";
VAL_ 1585 HVLowBatteryVoltageDisplay 0 "No Alert" 1 "Low Traction Battery: Engine Start Needed";
VAL_ 1585 eAWD_TireAlert 0 "No Tire Alert" 1 "Tire Alert";
VAL_ 1585 ePedal_DecelerationLevelState 0 "ePedal OFF" 1 "ePedal ON" 2 "ePedal Standby" 3 "Not used";
VAL_ 1585 ChargeConnectorLockModeStatus 0 "Invalid" 1 "UnLock" 2 "Lock" 3 "Auto";
VAL_ 1585 MILLamp_BEV 0 "MIL lamp off request" 1 "MIL Lamp on request" 2 "Reserved" 3 "MIL lamp auto-test";
VAL_ 1592 eAC_RevCapStatus 0 "Unavailable" 1 "Capped eAC rpm" 2 "Uncapped eAC rpm" 3 "Not used";
VAL_ 1595 RearViewRVC_CancelReason_RER 0 "No request" 1 "Reemission request";
VAL_ 1595 RearViewRVC_CancelReason 0 "No display" 1 "RearView Camera is blocked" 2 "RearView Camera permanent failure" 3 "Not Used";
VAL_ 1596 NextTurnProximityDetected 0 "No requested" 1 "Navigation picture requested";
VAL_ 1596 CurrentAudioState 0 "Normal listening" 1 "Update list signal" 2 "Mute audio" 3 "Not used";
VAL_ 1596 CurrentRadioFavorite 0 "No favorite radio selected" 1 "Favorite radio selected";
VAL_ 1596 CurrentPhoneStatus 0 "No call on going" 1 "Incoming call" 2 "Call on going" 3 "Automatic put on hold" 4 "Manual put on hold" 5 "Rejected call" 6 "Missed call" 7 "Call ended";
VAL_ 1596 CurrentAudioSource_v2 0 "All Off" 1 "Radio" 2 "CD DA" 3 "CD MP3" 4 "BT" 5 "SD" 6 "Aux" 7 "IPod" 8 "USB1" 9 "USB2" 10 "DVD" 11 "Blu-Ray" 12 "DTV" 13 "CarPlay" 14 "AndroidAuto" 15 "other sources";
VAL_ 1596 CurrentRadioBand_v2 0 "FM" 1 "AM" 2 "Digital radio" 3 "SXM" 4 "HD Radio" 5 "DAB" 6 "DRM" 7 "Not used";
VAL_ 1596 AutoDimmingRequest 0 "No request" 1 "AutoDimming Not activated" 2 "AutoDimming Activated" 3 "Reset request";
VAL_ 1596 CurrentRadioMode 0 "List" 1 "Manual" 2 "Preset" 3 "Not used";
VAL_ 1596 ClusterSkinRequest_v2 0 "No Request" 1 "Skin1" 2 "Skin2" 3 "Skin3" 4 "Skin4" 5 "Skin5" 6 "Skin6" 7 "Skin7" 8 "Skin8" 9 "Skin9" 10 "Skin10" 11 "Skin11" 12 "not used" 13 "not used" 14 "not used" 15 "Reset Request";
VAL_ 1596 SC_DepartureTimeWeekDay 0 "Monday" 1 "Tuesday" 2 "Wednesday" 3 "Thursday" 4 "Friday" 5 "Saturday" 6 "Sunday" 7 "unavailable";
VAL_ 1599 CTA_ActivationState 0 "Activated" 1 "Deactivated";
VAL_ 1604 CIDTouchControlAvailability 0 "CID touch not ready" 1 "CID touch ready";
VAL_ 1604 MeterDisplayActivationStatus 0 "OFF" 1 "Meter ON" 2 "IVI ON" 3 "Meter and IVI ON";
VAL_ 1604 MID_RefuseToSleep 0 "Reserved" 1 "Refuse to sleep" 2 "Ready to sleep" 3 "Reserved";
VAL_ 1604 TripSwitchActivationReq 0 "Button released" 1 "Button pressed";
VAL_ 1604 IlluminationDownActivationReq 0 "Button released" 1 "Button pressed";
VAL_ 1604 IlluminationUpActivationReq 0 "Button released" 1 "Button pressed";
VAL_ 1614 RearLeftLumbarMovingReq_X_Axis 0 "No request" 1 "Forward ON" 2 "Backward ON" 3 "Not Used";
VAL_ 1614 RearLeftFrontHeightMovingReq 0 "No request" 1 "Upward ON" 2 "Downward ON" 3 "Not Used";
VAL_ 1614 RearLeftMassageProgramReq 0 "No request" 1 "Program 1 requested" 2 "Program 2 requested" 3 "Program 3 requested" 4 "Program 4 requested" 5 "Program 5 requested" 6 "Program 6 requested" 7 "Program 7 requested" 8 "Program 8 requested" 9 "Program 9 requested" 10 "Program 10 requested" 11 "Program 11 requested" 12 "Program 12 requested" 13 "Program 13 requested" 14 "Program 14 requested" 15 "Not used";
VAL_ 1614 RearLeftMassageIntensityReq 0 "No request" 1 "Intensity 1 requested" 2 "Intensity 2 requested" 3 "Intensity 3 requested" 4 "Intensity 4 requested" 5 "Intensity 5 requested" 6 "Not used" 7 "Not used";
VAL_ 1614 RearLeftLumbarMovingReq_Z_Axis 0 "No request" 1 "Upward ON" 2 "Downward ON" 3 "Not Used";
VAL_ 1614 RearLeftReclinerMovingReq 0 "No request" 1 "Forward ON" 2 "Backward ON" 3 "Not Used";
VAL_ 1614 RearLeftOttomanMovingReq 0 "No request" 1 "Upward ON" 2 "Downward ON" 3 "Not Used";
VAL_ 1614 RearLeftMassageVelocityReq 0 "No request" 1 "Velocity 1 requested" 2 "Velocity 2 requested" 3 "Velocity 3 requested" 4 "Velocity 4 requested" 5 "Velocity 5 requested" 6 "Not Used" 7 "Not Used";
VAL_ 1614 RearRightLumbarMovingReq_X_Axis 0 "No request" 1 "Forward ON" 2 "Backward ON" 3 "Not Used";
VAL_ 1614 RearRightFrontHeightMovingReq 0 "No request" 1 "Upward ON" 2 "Downward ON" 3 "Not Used";
VAL_ 1614 RearLeftUpperbackrestMovingReq 0 "No request" 1 "Forward ON" 2 "Backward ON" 3 "Not Used";
VAL_ 1614 RearLeftSlideMovingReq 0 "No request" 1 "Forward ON" 2 "Backward ON" 3 "Not Used";
VAL_ 1614 RearRightMassageProgramReq 0 "No request" 1 "Program 1 requested" 2 "Program 2 requested" 3 "Program 3 requested" 4 "Program 4 requested" 5 "Program 5 requested" 6 "Program 6 requested" 7 "Program 7 requested" 8 "Program 8 requested" 9 "Program 9 requested" 10 "Program 10 requested" 11 "Program 11 requested" 12 "Program 12 requested" 13 "Program 13 requested" 14 "Program 14 requested" 15 "Not used";
VAL_ 1614 RearRightMassageIntensityReq 0 "No request" 1 "Intensity 1 requested" 2 "Intensity 2 requested" 3 "Intensity 3 requested" 4 "Intensity 4 requested" 5 "Intensity 5 requested" 6 "Not used" 7 "Not used";
VAL_ 1614 RearRightLumbarMovingReq_Z_Axis 0 "No request" 1 "Upward ON" 2 "Downward ON" 3 "Not Used";
VAL_ 1614 RearRightReclinerMovingReq 0 "No request" 1 "Forward ON" 2 "Backward ON" 3 "Not Used";
VAL_ 1614 RearRightOttomanMovingReq 0 "No request" 1 "Upward ON" 2 "Downward ON" 3 "Not Used";
VAL_ 1614 RearRightMassageVelocityReq 0 "No request" 1 "Velocity 1 requested" 2 "Velocity 2 requested" 3 "Velocity 3 requested" 4 "Velocity 4 requested" 5 "Velocity 5 requested" 6 "Not Used" 7 "Not Used";
VAL_ 1614 RearRightUpperbackrestMovingReq 0 "No request" 1 "Forward ON" 2 "Backward ON" 3 "Not Used";
VAL_ 1614 RearRightSlideMovingReq 0 "No request" 1 "Forward ON" 2 "Backward ON" 3 "Not Used";
VAL_ 1616 APA_CancelReason2 0 "No display" 1 "APA Permanent Failure" 2 "Parking Sensor permanent Failure" 3 "Not Used";
VAL_ 1616 APA_ScanInfo2 0 "No display" 1 "Scan" 2 "SlotLeft" 3 "SlotRight" 4 "SlotLeftRight" 5 "Not used" 6 "Not used" 7 "Not used";
VAL_ 1616 UPA_CancelReasonRER 0 "no request" 1 "reemission request";
VAL_ 1616 UPA_CancelReason 0 "No display" 1 "US sensors permanent failure";
VAL_ 1616 APA_CancelReason2_RER 0 "No request" 1 "Reemission request";
VAL_ 1622 ATCVT_WarningMessage6_ASIL 0 "No Request" 1 "ATCVT Warning Message6";
VAL_ 1622 ATCVT_WarningMessage3_ASIL 0 "No Request" 1 "ATCVT Warning Message3";
VAL_ 1622 ATCVT_WarningMessage2_ASIL 0 "No Request" 1 "ATCVT Warning Message2";
VAL_ 1622 ATCVT_WarningMessage1_ASIL 0 "No Request" 1 "ATCVT Warning Message1";
VAL_ 1626 ADB_FailureDisplay 0 "No ADB Failure" 1 "ADB Failure";
VAL_ 1628 V2L_SystemStatusDisplay 0 "No display" 1 "ALL OFF" 2 "V2L Inside ON" 3 "V2L Outside ON" 4 "V2L Both ON" 5 "V2L Disabled with error" 6 "Not Used" 7 "Unavailable value";
VAL_ 1628 V2L_SettingModeState 0 "ALL OFF" 1 "System OFF" 2 "System ON" 3 "Not Used";
VAL_ 1628 V2L_FrequencySettingState 0 "50 Hz" 1 "60 Hz" 2 "Not used" 3 "Unavailable";
VAL_ 1628 V2X_SystemFailureDisplay 0 "No display" 1 "V2X stopped because of low SOC" 2 "Low SOC for V2X" 3 "V2X System failure(Leakage current detection etc)" 4 "V2G aborted due to communication failure" 5 "V2G aborted due to technical failure" 6 "V2L stopped due to timeout" 7 "Unavailable value";
VAL_ 1628 V2L_PlugStatus 0 "No display" 1 "V2L plug available" 2 "V2L plug not available" 3 "Not Used";
VAL_ 1628 V2L_SystemAvailability 0 "No display" 1 "V2L Inside available" 2 "V2L Outside available" 3 "V2L Both available";
VAL_ 1635 V2Li_AlertsDisplay 0 "No display" 1 "V2L Inside not available during AC charge" 2 "V2L Inside still active" 3 "Charge DC limited due to V2L Inside" 4 "V2L Inside start impossible" 5 "Not Used" 6 "Not Used" 7 "Not Used";
VAL_ 1636 PBD_ActivationState 0 "No activation" 1 "Opening_movement_ongoing" 2 "Closing_movement_ongoing" 3 "Movement_delayed" 4 "Antipinch_movement_ongoing" 5 "Not Used" 6 "Not Used" 7 "Not Used";
VAL_ 1636 PBD_ResponseState 0 "No activation" 1 "ActivationRequest_Accepted" 2 "ActivationRequest_Completed" 3 "ActivationRequest_Rejected_Underqualified" 4 "Failure_detected" 5 "Obstacle_detected" 6 "Antipinch_detected" 7 "Not Used";
VAL_ 1636 PBD_AuthorizationState 0 "PBDNotAuthorized_AllMovementsInhibited" 1 "PBDAuthorized_AllMovementsAuthorized" 2 "PBDMainSwitchoff_LatchReleaseAuthorized" 3 "PBDFailure_LatchReleaseAuthorized" 4 "PBDFailure_AllMovementsInhibited" 5 "PBDAuthorized_ClosingMovementsAuthorized" 6 "Not Used" 7 "Not Used";
VAL_ 1636 PBDRadarActivationState 0 "PBD Measurement Authorized" 1 "PBD Measurement Inhibited";
VAL_ 1637 SteeringSettingState_v2 0 "Mode EPS 1 Normal / Normal" 1 "Mode EPS 2 Normal / Confort" 2 "Mode EPS 3 Normal / Sport" 3 "Mode EPS 4" 4 "Mode EPS 5 Casual / Normal" 5 "Mode EPS 6 Casual / Confort" 6 "Mode EPS 7 Casual / Sport" 7 "Mode EPS 8" 8 "Mode EPS 9 Quick / Normal" 9 "Mode EPS 10 Quick / Confort" 10 "Mode EPS 11 Quick / Sport" 11 "Mode EPS 12" 12 "Mode EPS 13" 13 "Drive Mode" 14 "Not used" 15 "Not used";
VAL_ 1637 PowerTrainSettingState 0 "Mode 1 (Standard)" 1 "Mode 2 (Sport)" 2 "Mode 3 (Eco)" 3 "Mode 4 (Snow)" 4 "Mode 5" 5 "Mode 6" 6 "Mode 7" 7 "Mode 8" 8 "Mode 9" 9 "Mode 10" 10 "Mode 11" 11 "Mode 12" 12 "Mode 13" 13 "Mode 14" 14 "Not used" 15 "Not used";
VAL_ 1637 AWDSettingState 0 "Mode 1" 1 "Mode 2" 2 "Mode 3" 3 "Mode 4" 4 "Mode 5" 5 "Mode 6" 6 "Not used" 7 "Not used";
VAL_ 1637 SuspensionSettingState 0 "Mode VADA 1 (Normal)" 1 "Mode VADA 2 (Comfort)" 2 "Mode VADA 3 (Sport)" 3 "Mode VADA 4" 4 "Mode VADA 5" 5 "Mode VADA 6 (Race)" 6 "Not used" 7 "Not used";
VAL_ 1637 DriveModeState 0 "Mode 0=NORMAL/STANDARD/AUTO" 1 "Mode 1=ECO" 2 "Mode 2=SPORT/TARMAC" 3 "Mode 3=SPORT+/POWER" 4 "Mode 4=COMFORT" 5 "Mode 5=PERSONAL" 6 "Mode 6=SNOW" 7 "Mode 7" 8 "Mode 8=OFF-ROAD/GRAVEL" 9 "Mode 9=MUD/RUT" 10 "Mode 10=SAND" 11 "Mode 11=TOW" 12 "Mode 12=ALL ROAD/ROCK" 13 "Mode 13=EXTREM" 14 "Mode 14=PERFO" 15 "Mode 15=VITAMIN" 16 "Mode 16=RACE" 17 "Mode 17" 18 "Mode 18" 19 "Mode 19" 20 "Mode 20" 21 "Mode 21" 22 "Mode 22" 23 "Mode 23" 24 "Mode 24" 25 "Mode 25" 26 "Mode 26" 27 "Mode 27" 28 "Mode 28" 29 "Mode 29" 30 "Mode 30" 31 "Unavailable";
VAL_ 1637 RWS_Warning_MMI 0 "No failure" 1 "Failure 1" 2 "Failure 2" 3 "Not Used";
VAL_ 1637 VMCsettingState_v2 0 "Mode1" 1 "Mode2" 2 "Mode3" 3 "Mode4" 4 "Mode5" 5 "Mode6" 6 "Mode7" 7 "Mode8" 8 "Mode9" 9 "Mode10" 10 "Mode11" 11 "Mode12" 12 "Mode13" 13 "Mode14" 14 "Mode15" 15 "Mode16";
VAL_ 1637 RegenerationSettingState 0 "Mode 1" 1 "Mode 2" 2 "Mode 3" 3 "Mode 4" 4 "Mode 5" 5 "Mode 6" 6 "Mode 7" 7 "Mode 8" 8 "Mode 9" 9 "Mode 10" 10 "Mode 11" 11 "Mode 12" 12 "Mode 13" 13 "Mode 14" 14 "Not used" 15 "Not used";
VAL_ 1637 SSA_MessageToDisplay 0 "No display" 1 "AutoHold activated" 2 "AutoHold deactivated" 3 "Not Used";
VAL_ 1640 ePedalReemissionRequest 0 "No display" 1 "One Pedal re-emission alert";
VAL_ 1645 AEB_FCWactivationState2 0 "AEB OFF / FCW OFF" 1 "AEB OFF / FCW ON" 2 "Not used" 3 "AEB ON / FCW ON";
VAL_ 1645 AEB_CyclistAlertRequest2 0 "No AEB cyclist alert" 1 "AEB cyclist alert";
VAL_ 1645 AEB_PedestrianAlertRequest2 0 "No AEB PEDESTRIAN alert" 1 "AEB PEDESTRIAN alert";
VAL_ 1645 AEB_VehicleAlertRequest2 0 "No AEB vehicle alert" 1 "AEB vehicle Approach alert" 2 "AEB vehicle Collision alert" 3 "AEB vehicle Alert reminder";
VAL_ 1645 AEB_StatusDisplay2_v2 0 "No display" 1 "AEB Off" 2 "operation" 3 "Not operation" 4 "Temporary failure" 5 "Permanent failure" 6 "Initial" 7 "Not Used";
VAL_ 1645 DW_ActivationState_TM 0 "DW deactivated" 1 "DW activated";
VAL_ 1645 FCW_SensibilityState 0 "Unavailable" 1 "Early" 2 "Standard" 3 "Late";
VAL_ 1645 AES_StatusDisplay 0 "No Display" 1 "OFF" 2 "Not Operational" 3 "Operational" 4 "Temporary failure" 5 "Permanent failure" 6 "Not Used" 7 "Not Used";
VAL_ 1645 AEB_JuncAssistActivationState 0 "Unavailable" 1 "Activated" 2 "Deactivated" 3 "Not used";
VAL_ 1645 AEB_FrSideRadarCancelReason 0 "No display" 1 "FrSideRadar blocked" 2 "Reserved" 3 "FrSideRadar permanent failure";
VAL_ 1645 AEB_JuncAssistAlertRight 0 "No alert" 1 "Junction Assist Information" 2 "Junction Assist Alert" 3 "Not used";
VAL_ 1645 AEB_JuncAssistAlertLeft 0 "No alert" 1 "Junction Assist Information" 2 "Junction Assist Alert" 3 "Not used";
VAL_ 1648 SelectedTrailerType 0 "No request" 1 "Conventional" 2 "Fifth wheel" 3 "Gooseneck" 4 "Reserve" 5 "Reserve" 6 "Reserve" 7 "Reserve" 8 "Reserve" 9 "Reserve" 10 "Reserve" 11 "Reserve" 12 "Reserve" 13 "Reserve" 14 "Reserve" 15 "Reset request";
VAL_ 1648 SelectedTrailerNumber 0 "No request" 1 "No.1" 2 "No.2" 3 "No.3" 4 "No.4" 5 "No.5" 6 "No.6" 7 "No.7" 8 "No.8" 9 "No.9" 10 "No.10" 11 "Reserve" 12 "Reserve" 13 "Reserve" 14 "Reserve" 15 "Reserve";
VAL_ 1648 VideoType_Meter 0 "Default" 1 "Camera" 2 "Movie" 3 "Not Used";
VAL_ 1648 TrailerNumberSettingChange 0 "No request" 1 "No.1" 2 "No.2" 3 "No.3" 4 "No.4" 5 "No.5" 6 "No.6" 7 "No.7" 8 "No.8" 9 "No.9" 10 "No.10" 11 "Reserve" 12 "Reserve" 13 "Reserve" 14 "Reserve" 15 "all";
VAL_ 1648 TrailerBSWActivationRequest 0 "No request" 1 "Active" 2 "Deactive" 3 "Reset request";
VAL_ 1648 SWS_SelectionStatus 0 "Left side display Menu" 1 "Right side display Menu";
VAL_ 1648 LDW_Sensibility_ChoiceRequest 0 "No request" 1 "Low sensibility request" 2 "Middle sensibility request" 3 "High sensibility request" 4 "Not used" 5 "Not used" 6 "Not used" 7 "Reset request";
VAL_ 1648 LaneSupport_ChoiceRequest 0 "No request" 1 "Activation" 2 "Deactivation" 3 "Reset request";
VAL_ 1648 LaneSupport_ActivationRequest 0 "No request" 1 "Activation" 2 "Deactivation" 3 "Reset request";
VAL_ 1648 SLIF_Notification_ChoiceRequest 0 "No request" 1 "SpeedLimit Notif Activation request" 2 "SpeedLimit Notif Deactivation request" 3 "Reset request";
VAL_ 1648 RAB_ChoiceRequest 0 "No request" 1 "Activation request" 2 "Deactivation request" 3 "Reset request";
VAL_ 1648 eHBox_USBInstall_InsertedRequest 0 "No Request" 1 "Request";
VAL_ 1648 eHBox_USB_WritabilityRequest 0 "No Request" 1 "No writing request" 2 "Writing request" 3 "Not used";
VAL_ 1648 eHBox_USBSave_InsertedRequest 0 "No Request" 1 "Request";
VAL_ 1648 eHBox_Current_Map_versionRequest 0 "No request" 1 "Request";
VAL_ 1648 ISA_ActivationRequest 0 "No request" 1 "ALL OFF request" 2 "SLIF ON request" 3 "SLIF ON + SLWF ON request" 4 "Not used" 5 "Not used" 6 "Not used" 7 "Reset request";
VAL_ 1648 CPDCheckAcknowledgement 0 "CPD Not Checked" 1 "CPD Checked";
VAL_ 1648 eHBox_USB_MapInstallRequest 0 "No Request" 1 "No update request" 2 "Update request" 3 "Not used";
VAL_ 1648 ISA_ChoiceRequest 0 "No request" 1 "ALL OFF request" 2 "SLIF ON request" 3 "SLIF + SLWF ON request" 4 "Not used" 5 "Not used" 6 "Not used" 7 "Reset request";
VAL_ 1652 VSPstatusDisplay 0 "VSP deactivated not request" 1 "VSP deactivated request";
VAL_ 1657 BSWrad_CancelReasonRER 0 "No request" 1 "Reemission request";
VAL_ 1657 BSWRad_CancelReason_v2 0 "No display" 1 "SideRadar blocked" 2 "SideRadar permanent failure" 3 "Trailer presence";
VAL_ 1659 UserIdentification_IKeyLink 0 "No request" 1 "Key No. 1" 2 "Key No. 2" 3 "Key No. 3" 4 "Key No. 4" 5 "Not used" 6 "Not used" 7 "Not used";
VAL_ 1662 PassengerSeatMemoRecall 0 "No recall" 1 "Recall of memorization 1" 2 "Recall of memorization 2" 3 "Recall of memorization 3" 4 "Recall of memorization 4" 5 "Recall of memorization 5" 6 "Recall of memorization 6" 7 "Not used";
VAL_ 1662 PassengerSeatMemoRequest 0 "No request of memorization" 1 "Request of memorization 1" 2 "Request of memorization 2" 3 "Request of memorization 3" 4 "Request of memorization 4" 5 "Request of memorization 5" 6 "Request of memorization 6" 7 "Reset Request";
VAL_ 1662 TimeFormatDisplay 0 "24h format" 1 "12h format";
VAL_ 1665 BSWson_ChoiceRequest 0 "No request" 1 "Selected" 2 "Not selected" 3 "Reset request";
VAL_ 1665 BSWrad_ChoiceRequest 0 "No request" 1 "Selected" 2 "Not selected" 3 "Reset request";
VAL_ 1665 MOIS_ActivationRequest 0 "No request" 1 "Activation request" 2 "Deactivation request" 3 "Reset request";
VAL_ 1665 SpeedLimNotifActivationRequest 0 "No request" 1 "SpeedLimit Notif Activation request" 2 "SpeedLimit Notif deactivation request" 3 "Reset request";
VAL_ 1665 WDA_ChoiceRequest 0 "No request" 1 "Selected" 2 "Not selected" 3 "Reset request";
VAL_ 1665 OverspeedAlertChoiceRequest 0 "No request" 1 "Selected" 2 "Not selected" 3 "Reset request";
VAL_ 1665 LDWLKA_ChoiceRequest 0 "No request" 1 "Selected" 2 "Not selected" 3 "Reset request";
VAL_ 1665 ELKA_ChoiceRequest 0 "No request" 1 "Selected" 2 "Not selected" 3 "Reset request";
VAL_ 1665 Distraction_ChoiceRequest 0 "No request" 1 "Selected" 2 "Not selected" 3 "Reset request";
VAL_ 1665 Fatigue_ChoiceRequest 0 "No request" 1 "Selected" 2 "Not selected" 3 "Reset request";
VAL_ 1665 MOIS_MuteActivationRequest 0 "No request" 1 "Mute request" 2 "Unmute request" 3 "Reset request";
VAL_ 1665 TCS_DeactivationRequest 0 "No request" 1 "TCS deactivation request" 2 "TCS activation request" 3 "Not used";
VAL_ 1666 Distract_AlertStatus2 0 "No Alert" 1 "Warning Alert" 2 "Danger Alert" 3 "Warning AlertRER";
VAL_ 1666 Cluster_DisplayContentsChangeReq 0 "No Request" 1 "Contents 1 request" 2 "Contents 2 request" 3 "Contents 3 request" 4 "Contents 4 request" 5 "Contents 5 request" 6 "Contents 6 request" 7 "Contents 7 request" 8 "Contents 8 request" 9 "Contents 9 request" 10 "Contents 10 request" 11 "Contents 11 request" 12 "Contents 12 request" 13 "Contents 13 request" 14 "Contents 14 request" 15 "Contents 15 request" 16 "Contents 16 request" 17 "Contents 17 request" 18 "Contents 18 request" 19 "Contents 19 request" 20 "Contents 20 request" 21 "Contents 21 request" 22 "Contents 22 request" 23 "Contents 23 request" 24 "Contents 24 request" 25 "Contents 25 request" 26 "Contents 26 request" 27 "Contents 27 request" 28 "Contents 28 request" 29 "Contents 29 request" 30 "Contents 30 request" 31 "Contents 31 request" 32 "Contents 32 request" 33 "Contents 33 request" 34 "Contents 34 request" 35 "Contents 35 request" 36 "Contents 36 request" 37 "Contents 37 request" 38 "Contents 38 request" 39 "Contents 39 request" 40 "Contents 40 request" 41 "Contents 41 request" 42 "Contents 42 request" 43 "Contents 43 request" 44 "Contents 44 request" 45 "Contents 45 request" 46 "Contents 46 request" 47 "Contents 47 request" 48 "Contents 48 request" 49 "Contents 49 request" 50 "Contents 50 request" 51 "Contents 51 request" 52 "Contents 52 request" 53 "Contents 53 request" 54 "Contents 54 request" 55 "Contents 55 request" 56 "Contents 56 request" 57 "Contents 57 request" 58 "Contents 58 request" 59 "Contents 59 request" 60 "Contents 60 request" 61 "Contents 61 request" 62 "Contents 62 request" 63 "Contents 63 request";
VAL_ 1666 DynamicBackgroundState 0 "No Request" 1 "State1" 2 "State2" 3 "State3" 4 "State4" 5 "State5" 6 "State6" 7 "State7" 8 "State8" 9 "State9" 10 "State10" 11 "State11" 12 "State12" 13 "State13" 14 "State14" 15 "State15" 16 "State16" 17 "Not used" 18 "Not used" 19 "Not used" 20 "Not used" 21 "Not used" 22 "Not used" 23 "Not used" 24 "Not used" 25 "Not used" 26 "Not used" 27 "Not used" 28 "Not used" 29 "Not used" 30 "Not used" 31 "Not used";
VAL_ 1666 Cluster_DisplayViewModeChangeReq 0 "No Request" 1 "View Mode1 request" 2 "View Mode2 request" 3 "View Mode3 request" 4 "View Mode4 request" 5 "View Mode5 request" 6 "View Mode6 request" 7 "View Mode7 request";
VAL_ 1666 DynamicBackgroundProgress 0 "0" 1 "10" 2 "20" 3 "30" 4 "40" 5 "50" 6 "60" 7 "70" 8 "80" 9 "90" 10 "100" 11 "Not used" 12 "Not used" 13 "Not used" 14 "Not used" 15 "Not used";
VAL_ 1666 SSickness_AlertStatus2 0 "No Alert" 1 "Danger Alert" 2 "Reserved" 3 "Reserved";
VAL_ 1666 Fatigue_AlertStatus2 0 "No Alert" 1 "Warning Alert" 2 "Danger Alert" 3 "Warning AlertRER";
VAL_ 1666 DMS_CameraCancelReason2 0 "No display" 1 "Camera temporary OBSTRUCTION" 2 "Camera temporary DIRTY" 3 "Camera temporary FACE MASKED" 4 "Camera temporary EYES MASKED" 5 "LEDs UNAVAILABLE" 6 "Camera OVER HEAT" 7 "DMS Permanent failure";
VAL_ 1666 NapModeRequest 0 "No request" 1 "Nap Mode OFF" 2 "Nap Mode ON" 3 "Not used";
VAL_ 1666 RelaxModeRequest 0 "No request" 1 "Relax Mode OFF" 2 "Relax Mode ON" 3 "Not used";
VAL_ 1666 FrSeatMemoPopUpActivationReq 0 "Deactivation request" 1 "Activation request";
VAL_ 1666 PsMassagePopUpActivationReq 0 "Deactivation request" 1 "Activation request";
VAL_ 1666 DrMassagePopUpActivationReq 0 "Deactivation request" 1 "Activation request";
VAL_ 1670 LOB_PositionSaveRequest 0 "No request" 1 "SAVE LOB position 1" 2 "SAVE LOB position 2" 3 "SAVE LOB position 3" 4 "SAVE LOB position 4" 5 "SAVE LOB position 5" 6 "SAVE LOB position 6" 7 "Not Used";
VAL_ 1670 LOB_PositionRecallRequest 0 "No request" 1 "RECALL LOB position 1" 2 "RECALL LOB position 2" 3 "RECALL LOB position 3" 4 "RECALL LOB position 4" 5 "RECALL LOB position 5" 6 "RECALL LOB position 6" 7 "Reset request";
VAL_ 1672 PBD_WakeUp_Signal 0 "Table Value16455";
VAL_ 1675 DMS_CameraCancelReason 0 "No display" 1 "Camera temporary OBSTRUCTION" 2 "Camera temporary DIRTY" 3 "Camera temporary FACE MASKED" 4 "Camera temporary EYES MASKED" 5 "LEDs UNAVAILABLE" 6 "Camera OVER HEAT" 7 "DMS Permanent failure";
VAL_ 1675 Distract_AlertStatus 0 "No Alert" 1 "Warning Alert" 2 "Danger Alert" 3 "Warning AlertRER";
VAL_ 1675 Fatigue_AlertStatus 0 "No Alert" 1 "Warning Alert" 2 "Danger Alert" 3 "Warning AlertRER";
VAL_ 1679 SeatMemoAlertRequest 0 "No alert" 1 "Alert request";
VAL_ 1682 HVAC_PresoakStateDisplay 0 "No Presoak in progress" 1 "Presoak Forbidden" 2 "Presoak in progress" 3 "Unavailable";
VAL_ 1684 RearViewAVM_CancelReason 0 "No display" 1 "RearView Camera is blocked" 2 "RearView Camera permanent failure" 3 "Not Used";
VAL_ 1684 RearViewAVM_CancelReason_RER 0 "No request" 1 "Reemission request";
VAL_ 1703 ProgrammedChargeStatus 0 "Always authorized charge" 1 "Delayed charge" 2 "Programmed charge by Calendar" 3 "Not Used";
VAL_ 1705 SpeedLimNotifActivationStatus 0 "Not available" 1 "SpeedLimitNotificationActivated" 2 "SpeedLimitNotificationDeactivated" 3 "Not used";
VAL_ 1709 BSIS_RightCancelReasonRER 0 "No request" 1 "Reemission request";
VAL_ 1709 BSIS_RightCancelReason 0 "No display" 1 "SideRadar blocked" 2 "SideRadar permanent failure" 3 "Trailer presence";
VAL_ 1711 RouteConf_METER_Request 0 "No Request" 1 "Confirm Request" 2 "Fail Request" 3 "Not used";
VAL_ 1711 TableModeRequest 0 "No request" 1 "Table Mode OFF" 2 "Table Mode ON" 3 "Not used";
VAL_ 1720 ADB_ActivationRequest 0 "No ADB request" 1 "ADB activated" 2 "ADB not activated" 3 "Reset request";
VAL_ 1720 RearSeatAlertActivationRequest 0 "No Request" 1 "Alert Message Activation Request" 2 "Alert Message and Horn Activation Request" 3 "Deactivation Request" 4 "Not used" 5 "Not used" 6 "Not used" 7 "Reset request";
VAL_ 1720 PredictiveRegenActivationRequest 0 "No request" 1 "Activation requested" 2 "Deactivation requested" 3 "Reset request";
VAL_ 1720 HUD_TelSMSactivationRequest 0 "No request" 1 "Activation request" 2 "Deactivation request" 3 "Reset request";
VAL_ 1720 DriverEasyAccessRequest 0 "No request" 1 "Easy access activation requested" 2 "Easy access de-activation requested" 3 "Reset Request";
VAL_ 1720 HandDrivingActivationRequest 0 "No request" 1 "Right Hand Driving requested" 2 "Left Hand Driving requested" 3 "Reset request";
VAL_ 1720 AutoInternalLightingRequest 0 "No request" 1 "Internal lighting activation request" 2 "Internal lighting deactivation request" 3 "Reset requested";
VAL_ 1720 WiperWithSpeedActivationRequest 0 "No request" 1 "Activation request" 2 "De-activation request" 3 "reset request";
VAL_ 1720 AccessModeRequest 0 "No request (initial value)" 1 "Standard mode requested" 2 "Secure mode requested" 3 "Access mode factory setting reset requested";
VAL_ 1721 BSIS_LeftCancelReasonRER 0 "No request" 1 "Reemission request";
VAL_ 1721 BSIS_LeftCancelReason 0 "No display" 1 "SideRadar blocked" 2 "SideRadar permanent failure" 3 "Trailer presence";
VAL_ 1730 HVlightChargeStatusDisplay 0 "No display" 1 "No HV light charge in progress" 2 "HV light charge refused by EEM - 12V recharge needed" 3 "HV light charge in progress" 4 "HV light charge completed" 5 "Not used" 6 "Not used" 7 "Not used";
VAL_ 1730 UreaMinMaxRefill_DisplayReq 0 "no display" 1 "display request";
VAL_ 1730 CloggedBattAirInletDisplay 0 "No display" 1 "Clogged battery air inlet";
VAL_ 1738 ePedal_HoldOffModeRequest 0 "No Request" 1 "Hold OFF mode request" 2 "Hold ON mode request" 3 "Not Used";
VAL_ 1738 VirtualKeySuspendReq 0 "No Request" 1 "VK Suspend" 2 "VK Resume" 3 "VK Factory Reset (Switch to Default VK State)";
VAL_ 1738 SET_ADL3Activation_Request 0 "No request" 1 "Activation" 2 "Deactivation" 3 "Reset Request";
VAL_ 1738 SET_AD_HandsOff_Request 0 "No request" 1 "Activation" 2 "Deactivation" 3 "Reset request";
VAL_ 1738 SET_ALC_AssistMode_Request 0 "No request" 1 "Successive" 2 "Individual" 3 "Reset request";
VAL_ 1738 SET_ADL3_Request 0 "No request" 1 "OFF" 2 "ON" 3 "Reset request";
VAL_ 1738 AmbientLightingArea3Req_Meter 0 "No Request" 1 "AmbientLighting Area 3 requested" 2 "AmbientLighting Area 3 not requested" 3 "Reset Request";
VAL_ 1738 AmbientLightingArea2Req_Meter 0 "No Request" 1 "AmbientLighting Area 2 requested" 2 "AmbientLighting Area 2 not requested" 3 "Reset Request";
VAL_ 1738 SET_ALCP2P_AlertLevel_Request 0 "No request" 1 "Lv1" 2 "Lv2" 3 "Lv3" 4 "Reset request" 5 "Not used" 6 "Not used" 7 "Not used";
VAL_ 1738 HUD_UpDownRequest 0 "No request" 1 "Up command requested" 2 "Down command requested" 3 "Reset request";
VAL_ 1738 AmbientLightingArea5Req_Meter 0 "No Request" 1 "AmbientLighting Area 5 requested" 2 "AmbientLighting Area 5 not requested" 3 "Reset Request";
VAL_ 1738 AmbientLightingArea1Req_Meter 0 "No Request" 1 "AmbientLighting Area 1 requested" 2 "AmbientLighting Area 1 not requested" 3 "Reset Request";
VAL_ 1738 RearSeatAlertAcknowledgement 0 "No Request" 1 "Activation Requested" 2 "Deactivation Requested" 3 "Not used";
VAL_ 1738 RearSeatCheckAcknowledgement 0 "Rear Seat Not Checked" 1 "Rear Seat Checked";
VAL_ 1738 InternalLightingIntensityRequest 0 "No Request" 1 "Level 0_OFF requested" 2 "Level 1 requested" 3 "Level 2 requested" 4 "Level 3 requested" 5 "Level 4 requested" 6 "Level 5 requested" 7 "Reset requested";
VAL_ 1738 SonarSystemPauseRequest 0 "No request" 1 "System Pause requested";
VAL_ 1738 AmbientADLinkRequest2 0 "No Request" 1 "AD LINK activation requested" 2 "AD LINK deactivation requested" 3 "Reset";
VAL_ 1738 FunctionalLightingActivReq2 0 "No Request" 1 "Functional Light activation requested" 2 "Functional Light deactivation requested" 3 "Functional Light auto requested";
VAL_ 1738 CASP_ActivationRequest 0 "No Request" 1 "Activation request" 2 "Deactivation request" 3 "Reset request";
VAL_ 1738 AES_ActivationRequest 0 "No Request" 1 "Activation request" 2 "De-activation request" 3 "Reset Request";
VAL_ 1738 SET_ContextSpdLocal_ActRequest 0 "No Request" 1 "OFF" 2 "Auto mode activation Request" 3 "Prompt mode activation Request" 4 "Reset Request" 5 "Not used" 6 "Not used" 7 "Not used";
VAL_ 1738 LCDN_ActivationRequest 0 "No request" 1 "LCDN activation request" 2 "LCDN deactivation request" 3 "Reset request";
VAL_ 1738 LCDN_SensibilityRequest 0 "No request" 1 "Low sensibility request" 2 "Middle sensibility request" 3 "High sensibility request" 4 "Not used" 5 "Not used" 6 "Not used" 7 "Reset request";
VAL_ 1741 VolumAlarmDisplayState 0 "No request" 1 "Deactivated" 2 "Activated" 3 "Not used";
VAL_ 1741 ePedalDecelerationLevelRequest 0 "no request" 1 "Low deceleration request" 2 "Middle deceleration request" 3 "High deceleration request";
VAL_ 1741 ePedalMemorySettingRequest 0 "No Request" 1 "Memory Setting request is OFF" 2 "Memory Setting request is ON" 3 "Not used";
VAL_ 1741 DCA_ActivationRequest 0 "No request" 1 "Activated" 2 "Deactivated" 3 "Reset request";
VAL_ 1741 ContextSpeed_ActivationRequest 0 "No Request" 1 "OFF" 2 "Auto mode activation Request" 3 "Prompt mode activation Request" 4 "Reset Request" 5 "Not Used" 6 "Not Used" 7 "Not Used";
VAL_ 1741 OffsetValue_Request 0 "No Request" 1 "-10" 2 "-9" 3 "-8" 4 "-7" 5 "-6" 6 "-5" 7 "-4" 8 "-3" 9 "-2" 10 "-1" 11 "0" 12 "1" 13 "2" 14 "3" 15 "4" 16 "5" 17 "6" 18 "7" 19 "8" 20 "9" 21 "10" 22 "Reset Request" 23 "Not used" 24 "Not used" 25 "Not used" 26 "Not used" 27 "Not used" 28 "Not used" 29 "Not used" 30 "Not used" 31 "Not used";
VAL_ 1741 SET_NavigatDriveAssist_Request 0 "No request" 1 "OFF" 2 "ON" 3 "Reset request";
VAL_ 1741 SET_ALCActivationByTSIG_Request 0 "No request" 1 "OFF" 2 "ON" 3 "Reset request";
VAL_ 1741 OffsetActivation_Request 0 "No request" 1 "Activation request" 2 "Deactivation  request" 3 "Reset request";
VAL_ 1741 ContextRoad_ActivationRequest 0 "No request" 1 "OFF" 2 "ON" 3 "Reset Request";
VAL_ 1741 SET_OvertakingAssist_Request 0 "No request" 1 "OFF" 2 "ON" 3 "Reset request";
VAL_ 1741 SET_Deceleration_Request 0 "No request" 1 "Quick" 2 "Standard" 3 "Gentle" 4 "Reset request" 5 "Not used" 6 "Not used" 7 "Not used";
VAL_ 1741 SET_Acceleration_Request 0 "No request" 1 "Quick" 2 "Standard" 3 "Gentle" 4 "Reset request" 5 "Not used" 6 "Not used" 7 "Not used";
VAL_ 1741 SET_VoiceGuidance_Request 0 "No request" 1 "OFF" 2 "ON" 3 "Reset request";
VAL_ 1741 UserSelectChargePowerDisplay 0 "No request" 1 "DC charging power" 2 "AC first level charging power" 3 "AC second level charging power" 4 "AC third level charging power" 5 "Not used" 6 "Not used" 7 "Not used";
VAL_ 1741 BatteryCool_eACLimitStatus 0 "No request" 1 "Uncap request" 2 "No uncap request" 3 "Not used";
VAL_ 1741 SET_CornerSpeedLevel_Request 0 "No request" 1 "Quick" 2 "Standard" 3 "Gentle" 4 "Reset request" 5 "Not used" 6 "Not used" 7 "Not used";
VAL_ 1741 SET_PositionInLane_Request 0 "No request" 1 "To_hard_shoulder" 2 "Centre" 3 "To_overtake_lane" 4 "Reset request" 5 "Not Used" 6 "Not Used" 7 "Not Used";
VAL_ 1741 SET_LaneChangeSwiftness_Request 0 "No request" 1 "Swift" 2 "Standard" 3 "Comfort" 4 "Reset request" 5 "Not used" 6 "Not used" 7 "Not used";
VAL_ 1741 HVbatteryCoolingActivationReq 0 "No request" 1 "Battery cooling activation Request" 2 "Battery cooling desactivation Request" 3 "Reset to factory value";
VAL_ 1741 SET_OvertakeRelatSpeed_Request 0 "No request" 1 "Low" 2 "Middle" 3 "High" 4 "Reset request" 5 "Not Used" 6 "Not Used" 7 "Not Used";
VAL_ 1742 EAP_CancelReason 0 "No display" 1 "Sonar Blocked" 2 "Sonar obstructed" 3 "Not Used";
VAL_ 1742 ACC_CancelReasonRER 0 "No request" 1 "Reemission request";
VAL_ 1742 ACC_CancelReason_v2 0 "No Alert" 1 "ACC Refused : IntelligentParkAssist / HFPB activated" 2 "Tire slipped" 3 "Parking Brake activated" 4 "Seat belt was unfastened" 5 "Door was opened" 6 "Fr Camera High temperature" 7 "Fr Camera Visibility is Impaired" 8 "FRCamera Permanent Failure" 9 "FrRadar Blocked " 10 "FrRadar Permanent Failure" 11 "Can't hold vehicle(Epkb is not applied)" 12 "ACC refused: RaceMode" 13 "Others By User" 14 "ACC Refused : HDC Active" 15 "ACC Permanent Failure" 16 "ACC Refused : VDC Off" 17 "ACC Refused : Out Of Speed Range" 18 "ACC Refused : AEB Off" 19 "ACC_Refused: Other" 20 "Bad Wheathear" 21 "ACC_Refused: EVPriorityMode activated" 22 "Not used" 23 "Not used" 24 "Not used" 25 "Not used" 26 "Not used" 27 "Not used" 28 "Not used" 29 "Not used" 30 "Not used" 31 "Not used";
VAL_ 1742 BCI_CancelReasonRER 0 "No request" 1 "Reemission request";
VAL_ 1742 OSE_CancelReasonRER 0 "No request" 1 "Reemission request";
VAL_ 1742 APA_Warning3 0 "No Alert" 1 "Alert";
VAL_ 1742 AEB_CancelReasonRER 0 "No request" 1 "Reemission request";
VAL_ 1742 AEB_CancelReason_v2 0 "No display" 1 "VDC desactivated by driver (Canceled by)" 2 "VDC in regulation (Canceled by)" 3 "FrCam Blocked" 4 "FrCam High tempearture" 5 "FrCam Permanent Failure" 6 "Radar blocked" 7 "Radar Permanent Failure" 8 "Front side radar blocked" 9 "Front side radar permanent failure" 10 "Trailer Presence" 11 "Race mode" 12 "Bad weather" 13 "Accel Pedal high temp" 14 "ADAS ECU Temporary failure" 15 "ADAS ECU Permanent failure";
VAL_ 1742 LDW_CancelReason 0 "No display" 1 "Camera blocked" 2 "Camera is overheat (High Temperature)" 3 "Camera permanent failure" 4 "LDW Refuse: Race mode" 5 "ADAS ECU Temporary failure" 6 "ADAS ECU Permanent failure" 7 "Not Used";
VAL_ 1742 DCA_CancelReason 0 "No alert" 1 "Target lost at low speed" 2 "Out of speed range" 3 "IntelligentParkAssist / HFPB activated" 4 "Alert_VDCoff VDC(ESC) deactivated" 5 "Alert_VDCoperated VDC(ESC) operated" 6 "Tire slipped" 7 "Parking Brake activated" 8 "Seat belt was unfastened" 9 "Door was opened" 10 "FrRadar Blocked" 11 "FrRadar Permanent Failure" 12 "Don't start against obstacle" 13 "Can't hold vehicle(Epkb is not applied)" 14 "Others by System" 15 "Vehicle Stopped" 16 "ACCManuelTransmission: Too long gear change" 17 "ACCManuelTransmission: Out of operative range (RPM + 1st gear)" 18 "RaceMode" 19 "Cancel due to AEB" 20 "Cancel due to preceding vehicle rolling back" 21 "HDC activated - Active Pedal HighTemp (Canceled by)" 22 "Not used" 23 "Not used" 24 "Not used" 25 "Not used" 26 "Not used" 27 "Not used" 28 "Not used" 29 "Not used" 30 "Not used" 31 "Not used";
VAL_ 1742 LKA_CancelReason 0 "No display" 1 "Front Camera is blocked" 2 "Front Camera is overheat (High Temperature)" 3 "Front Camera permanent failure" 4 "LKA Refuse: LCA Active" 5 "LKA Refuse: Race mode" 6 "VDC desactivated by driver State" 7 "VDC in regulation State";
VAL_ 1742 LCA_CancelReasonRER 0 "No request" 1 "Reemission request";
VAL_ 1742 LCA_CancelReason 0 "No alert" 1 "LCA refused : ACC not activated" 2 "LCA Permanent Failure" 3 "FrCamera High temperature" 4 "FrCamera Visibility is Impaired" 5 "FrCamera Permanent Failure" 6 "FrRadar Blocked" 7 "FrRadar permanent failure" 8 "LCA Refused : HOD" 9 "LCA Cancel : Target lost" 10 "LCA Cancel : other" 11 "LCA Refused : other" 12 "LCA Refused : Race mode" 13 "Bad weather" 14 "Not used" 15 "Not used";
VAL_ 1742 OSE_CancelReason 0 "No display" 1 "Trailer Presence" 2 "Side Radar Blocked" 3 "Side Radar Permanent Failure" 4 "Left Side Radar Occlusion" 5 "Right Side Radar Occlusion" 6 "Left and Right Side Radar Occlusion" 7 "OSE Permanent Failure";
VAL_ 1742 ELKA_CancelReasonRER 0 "No request" 1 "Reemission request";
VAL_ 1742 LKA_CancelReasonRER 0 "No request" 1 "Reemission request";
VAL_ 1742 LDW_CancelReasonRER 0 "No request" 1 "Reemission request";
VAL_ 1742 ELKA_CancelReason_v2 0 "No alert" 1 "Front Camera blocked" 2 "Front Camera permanent failure" 3 "Front Camera high temperature" 4 "Radar blocked" 5 "Radar permanent failure" 6 "Rear Side radar blocked" 7 "Rear Side radar permanent failure" 8 "Trailer presence" 9 "Front Side radar blocked" 10 "Front Side radar permanent failure" 11 "VDC desactivated by driver State" 12 "VDC in regulation State" 13 "Deactivated: Race Mode" 14 "ADAS ECU Temporary failure" 15 "ADAS ECU Permanent failure";
VAL_ 1742 BCI_CancelReason_v2 0 "No display" 1 "VDC desactivated by driver" 2 "VDC in regulation" 3 "Active Pedal HighTemp" 4 "SideRadar Blocked" 5 "Side Radar Permanent Failure" 6 "Us Sensor Permanent Failure" 7 "Parking Camera blocked" 8 "Parking Camera Permanent Failure" 9 "Trailer Presence" 10 "Not used" 11 "Not used" 12 "Not used" 13 "Not used" 14 "Not used" 15 "Not used";
VAL_ 1742 AES_CancelReasonRER 0 "No request" 1 "Reemission request";
VAL_ 1742 AES_CancelReason 0 "No Alert" 1 "Front Camera Blocked" 2 "Front Camera Permanent Failure" 3 "Front Camera High temperature" 4 "Radar Blocked" 5 "Radar Permanent Failure" 6 "RearSideRadar Blocked" 7 "RearSideRadar Permanent Failure" 8 "Trailer Presence" 9 "FrontSideRadar Blocked" 10 "FrontSideRadar Permanent Failure" 11 "VDC desactivated by driver" 12 "VDC in regulation" 13 "Deactivated: Race mode State" 14 "ADAS ECU Temporary failure" 15 "ADAS ECU Permanent failure";
VAL_ 1742 ADmodeStatus_Slow 0 "AD/RPK OFF" 1 "AD2 L2 regulation" 2 "AD1 L3 regulation" 3 "RPK regulation" 4 "AD/RPK OFF + TD or MRM in regulation" 5 "AD2 L2 regulation + TD or MRM in regulation" 6 "AD1 L3 regulation + TD or MRM in regulation" 7 "RPK regulation + TD or MRM in regulation";
VAL_ 1742 WDA_ChoiceState2 0 "Selected" 1 "Not selected";
VAL_ 1742 ELKA_ChoiceState2 0 "Selected" 1 "Not selected";
VAL_ 1742 LaneSupport_ChoiceState 0 "Activated" 1 "Deactivated";
VAL_ 1742 LaneSupport_ActivationState 0 "Activated" 1 "Deactivated";
VAL_ 1742 LDW_Sensibility_ChoiceState 0 "Unavailable" 1 "Low sensibility" 2 "Middle sensibility" 3 "High sensibility";
VAL_ 1742 RAB_ChoiceState 0 "Activated" 1 "Deactivated";
VAL_ 1755 HVB_HighTempAlert 0 "No Overheat alert" 1 "Overheat alert";
VAL_ 1755 BatteryTempHighLowDisp 0 "No display" 1 "Display";
VAL_ 1755 HVbatteryAntifreezeInProgress 0 "No display" 1 "Battery antifreeze in progress";
VAL_ 1755 HVbatteryCoolingInProgressStatus 0 "No display" 1 "Battery cooling in progress";
VAL_ 1755 HVbatteryCoolingActivationState 0 "Battery cooling activated" 1 "Battery cooling desactivated";
VAL_ 1755 ClimHVpowerLimitationDisp_HEVC 0 "No display" 1 "Thermal Comfort available" 2 "SOC decreasing warning" 3 "No Thermal Comfort available" 4 "Downgraded charging time alert" 5 "Not used" 6 "Not used" 7 "Not used";
VAL_ 1755 PnC_Contract_Error 0 "No Display" 1 "Error";
VAL_ 1755 BatteryTempTelltale 0 "No display request" 1 "Primary warning" 2 "Secondary warning" 3 "Not used";
VAL_ 1755 HVbatteryColdAlert 0 "No display" 1 "Plug vehicle before leaving it to be able to start" 2 "Plug before stalling due to cold temperature" 3 "Plug & wait before starting vehicle" 4 "Wait for higher temperature before starting vehicle" 5 "Not used" 6 "Not used" 7 "Not used";
VAL_ 1756 V2L_SettingModeRequest 0 "No request" 1 "All OFF" 2 "System OFF" 3 "System ON" 4 "Reset request" 5 "Not Used" 6 "Not Used" 7 "Not Used";
VAL_ 1756 V2L_FrequencySettingRequest 0 "No request" 1 "50 Hz" 2 "60 Hz" 3 "Reset request";
VAL_ 1756 SET_OffsetValueLocal_Request 0 "No Request" 1 "-10" 2 "-9" 3 "-8" 4 "-7" 5 "-6" 6 "-5" 7 "-4" 8 "-3" 9 "-2" 10 "-1" 11 "0" 12 "1" 13 "2" 14 "3" 15 "4" 16 "5" 17 "6" 18 "7" 19 "8" 20 "9" 21 "10" 22 "Reset Request" 23 "Not used" 24 "Not used" 25 "Not used" 26 "Not used" 27 "Not used" 28 "Not used" 29 "Not used" 30 "Not used" 31 "Not used";
VAL_ 1756 Distraction_AlertActivationReq 0 "No request" 1 "Distraction alert activation" 2 "Distraction alert deactivation" 3 "Reset request";
VAL_ 1756 ATCVT_ATFRemainingDistanceReset 0 "No request" 1 "Remaining distance reset";
VAL_ 1756 ELKA_OTOC_ActivationRequest 0 "No request" 1 "Activation" 2 "Deactivation" 3 "Reset request";
VAL_ 1756 DMC_SensitivityRequest 0 "No request" 1 "Low sensitivity request" 2 "Middle sensitivity request" 3 "High sensitivity request" 4 "Not used" 5 "Not used" 6 "Not used" 7 "Reset request";
VAL_ 1756 Drowsy_AlertActivationRequest 0 "No request" 1 "Drowsy alert activation" 2 "Drowsy alert deactivation" 3 "Reset request";
VAL_ 1756 PSDBuzzerActivationRequest 0 "No Request" 1 "Power Slide Door Buzzer inhibition Request" 2 "Power Slide Door Buzzer Authorization Request" 3 "Reset Request";
VAL_ 1756 OverspeedAlertActivationRequest 0 "No request" 1 "Overspeed alert activation request" 2 "Overspeed alert deactivation request" 3 "Reset request";
VAL_ 1756 LKA_DL_ActivationRequest 0 "No request" 1 "Activation" 2 "Deactivation" 3 "Reset request";
VAL_ 1756 ELKS_ActivationRequest 0 "No request" 1 "Activation" 2 "Deactivation" 3 "Reset request";
VAL_ 1756 Cluster_DispViewModeChangeResult 0 "No Message" 1 "Change accepted" 2 "Change Not accepted Temporary Reason" 3 "Change Not accepted Permanent Reason";
VAL_ 1756 Cluster_DisplayViewModeStatus 0 "INVALID" 1 "View Mode1" 2 "View Mode2" 3 "View Mode3" 4 "View Mode4" 5 "View Mode5" 6 "View Mode6" 7 "View Mode7";
VAL_ 1756 Privacy_Mode_Request 0 "No request" 1 "Data Sharing forbidden " 2 "Data Sharing allowed" 3 "Geolocation Sharing forbidden" 4 "Reserved" 5 "Reserved" 6 "Reserved" 7 "Reset Request";
VAL_ 1756 Cluster_DispContentsChangeResult 0 "No Message" 1 "Change accepted" 2 "Change Not accepted Temporary Reason" 3 "Change Not accepted Permanent Reason";
VAL_ 1756 Cluster_DisplayContentsStatus 0 "INVALID" 1 "Contents 1" 2 "Contents 2" 3 "Contents 3" 4 "Contents 4" 5 "Contents 5" 6 "Contents 6" 7 "Contents 7" 8 "Contents 8" 9 "Contents 9" 10 "Contents 10" 11 "Contents 11" 12 "Contents 12" 13 "Contents 13" 14 "Contents 14" 15 "Contents 15" 16 "Contents 16" 17 "Contents 17" 18 "Contents 18" 19 "Contents 19" 20 "Contents 20" 21 "Contents 21" 22 "Contents 22" 23 "Contents 23" 24 "Contents 24" 25 "Contents 25" 26 "Contents 26" 27 "Contents 27" 28 "Contents 28" 29 "Contents 29" 30 "Contents 30" 31 "Contents 31" 32 "Contents 32" 33 "Contents 33" 34 "Contents 34" 35 "Contents 35" 36 "Contents 36" 37 "Contents 37" 38 "Contents 38" 39 "Contents 39" 40 "Contents 40" 41 "Contents 41" 42 "Contents 42" 43 "Contents 43" 44 "Contents 44" 45 "Contents 45" 46 "Contents 46" 47 "Contents 47" 48 "Contents 48" 49 "Contents 49" 50 "Contents 50" 51 "Contents 51" 52 "Contents 52" 53 "Contents 53" 54 "Contents 54" 55 "Contents 55" 56 "Contents 56" 57 "Contents 57" 58 "Contents 58" 59 "Contents 59" 60 "Contents 60" 61 "Contents 61" 62 "Contents 62" 63 "Contents 63";
VAL_ 1762 PassengerEasyAccessRequest2 0 "No Request" 1 "Easy Access activation requested" 2 "Easy Access de-activation requested" 3 "Reset request";
VAL_ 1762 VolumAlarmActivationRequest 0 "No Request" 1 "Activation Request" 2 "Ask On Exit Request" 3 "Deactivation Once Request" 4 "Deactivation Request" 5 "Not used" 6 "Not used" 7 "Reset Request";
VAL_ 1762 AmbientLightingColorReq2 0 "No Request" 1 "Color 1" 2 "Color 2" 3 "Color 3" 4 "Color 4" 5 "Color 5" 6 "Color 6" 7 "Color 7" 8 "Color 8" 9 "Color 9" 10 "Color 10" 11 "Color 11" 12 "Color 12" 13 "Color 13" 14 "Color 14" 15 "Color 15" 16 "Color 16" 17 "unused" 18 "unused" 19 "unused" 20 "unused" 21 "unused" 22 "unused" 23 "unused" 24 "unused" 25 "unused" 26 "unused" 27 "unused" 28 "unused" 29 "unused" 30 "unused" 31 "Reset Request";
VAL_ 1762 PBDMainSwitchActivationRequest 0 "No Request" 1 "Power Backdoor Inhibition Request" 2 "Power Backdoor Authorization Request" 3 "Reset Request";
VAL_ 1762 SteeringTiltActivationRequest 0 "No request" 1 "Activation request" 2 "Deactivation request" 3 "Reset request";
VAL_ 1762 AmbientLightDayIntensityRequest2 30 "No Request" 31 "Reset Request";
VAL_ 1762 AmbientlightADColorReq_Meter 0 "No request" 1 "Color 1" 2 "Color 2" 3 "Color 3" 4 "Color 4" 5 "Color 5" 6 "Color 6" 7 "Color 7" 8 "Color 8" 9 "Color 9" 10 "Color 10" 11 "Color 11" 12 "Color 12" 13 "Color 13" 14 "Color 14" 15 "Color 15" 16 "Color 16" 17 "Color 17" 18 "Color 18" 19 "Color 19" 20 "Color 20" 21 "Color 21" 22 "Color 22" 23 "Color 23" 24 "Color 24" 25 "Color 25" 26 "Color 26" 27 "Color 27" 28 "Color 28" 29 "Color 29" 30 "Color 30" 31 "Color 31" 32 "Color 32" 33 "Color 33" 34 "Color 34" 35 "Color 35" 36 "Color 36" 37 "Color 37" 38 "Color 38" 39 "Color 39" 40 "Color 40" 41 "Color 41" 42 "Color 42" 43 "Color 43" 44 "Color 44" 45 "Color 45" 46 "Color 46" 47 "Color 47" 48 "Color 48" 49 "Color 49" 50 "Color 50" 51 "Color 51" 52 "Color 52" 53 "Color 53" 54 "Color 54" 55 "Color 55" 56 "Color 56" 57 "Color 57" 58 "Color 58" 59 "Color 59" 60 "Color 60" 61 "Color 61" 62 "Color 62" 63 "Color 63" 64 "Color 64" 65 "Color 65" 66 "Color 66" 67 "Color 67" 68 "Color 68" 69 "Color 69" 70 "Color 70" 71 "Color 71" 72 "Color 72" 73 "Color 73" 74 "Color 74" 75 "Color 75" 76 "Color 76" 77 "Color 77" 78 "Color 78" 79 "Color 79" 80 "Color 80" 81 "Color 81" 82 "Color 82" 83 "Color 83" 84 "Color 84" 85 "Color 85" 86 "Color 86" 87 "Color 87" 88 "Color 88" 89 "Color 89" 90 "Color 90" 91 "Color 91" 92 "Color 92" 93 "Color 93" 94 "Color 94" 95 "Color 95" 96 "Color 96" 97 "Color 97" 98 "Color 98" 99 "Color 99" 100 "Color 100" 101 "Color 101" 102 "Color 102" 103 "Color 103" 104 "Color 104" 105 "Color 105" 106 "Color 106" 107 "Color 107" 108 "Color 108" 109 "Color 109" 110 "Color 110" 111 "Color 111" 112 "Color 112" 113 "Color 113" 114 "Color 114" 115 "Color 115" 116 "Color 116" 117 "Color 117" 118 "Color 118" 119 "Color 119" 120 "Color 120" 121 "Color 121" 122 "Color 122" 123 "Color 123" 124 "Color 124" 125 "Color 125" 126 "Color 126" 127 "Reset Request";
VAL_ 1762 AmbiLightADLINKTypeReq_Meter 0 "No Request" 1 "Request Type1" 2 "Request Type2" 3 "Request Type3";
VAL_ 1762 AmbiLightNightIntensityRequest2 30 "No Request" 31 "Reset Request";
VAL_ 1763 AntiUndertake_ActivationRequest 0 "No request" 1 "UndertakePrevention activation request" 2 "UndertakePrevention deactivation request" 3 "Reset request";
VAL_ 1763 HUD_RotationPositionRequest 0 "No request" 1 "Step 1" 2 "Step 2" 3 "Step 3" 4 "Step 4" 5 "Step 5" 6 "Step 6" 7 "Step 7" 8 "Step 8" 9 "Step 9" 10 "Step 10" 11 "Step 11" 12 "Step 12" 13 "Step 13" 14 "Step 14" 15 "Step 15" 16 "Step 16" 17 "Step 17" 18 "Step 18" 19 "Step 19" 20 "Step 20" 21 "Step 21" 22 "Not used" 23 "Not used" 24 "Not used" 25 "Not used" 26 "Not used" 27 "Not used" 28 "Not used" 29 "Not used" 30 "Not used" 31 "Reset Request";
VAL_ 1768 VideoType 0 "Default" 1 "Camera" 2 "Movie" 3 "Not Used";
VAL_ 1768 DayNightUserRequest 0 "Day" 1 "Night";
VAL_ 1768 IlluminationControlReq 0 "No request" 1 "Step1" 2 "Step2" 3 "Step3" 4 "Step4" 5 "Step5" 6 "Step6" 7 "Step7" 8 "Step8" 9 "Step9" 10 "Step10" 11 "Step11" 12 "Step12" 13 "Step13" 14 "Step14" 15 "Step15" 16 "Step16" 17 "Step17" 18 "Step18" 19 "Step19" 20 "Step20" 21 "Step21" 22 "Step22" 23 "Not used" 24 "Not used" 25 "Not used" 26 "Not used" 27 "Not used" 28 "Not used" 29 "Not used" 30 "Not used" 31 "Not used";
VAL_ 1768 IlluminationContReqForCamera 0 "No request" 1 "Step1" 2 "Step2" 3 "Step3" 4 "Step4" 5 "Step5" 6 "Step6" 7 "Step7" 8 "Step8" 9 "Step9" 10 "Step10" 11 "Step11" 12 "Step12" 13 "Step13" 14 "Step14" 15 "Step15" 16 "Step16" 17 "Step17" 18 "Step18" 19 "Step19" 20 "Step20" 21 "Step21" 22 "Step22" 23 "Not used" 24 "Not used" 25 "Not used" 26 "Not used" 27 "Not used" 28 "Not used" 29 "Not used" 30 "Not used" 31 "Not used";
VAL_ 1772 V2X_SOClimitationLevelRequest 126 "No request" 127 "Reset request";
VAL_ 1772 AEB_JuncAssistActivationRequest 0 "No request" 1 "Activation" 2 "Deactivation" 3 "Reset request";
VAL_ 1772 HUD_SSAActivationRequest 0 "No Request" 1 "Activation request" 2 "De-activation request" 3 "Reset request";
VAL_ 1772 HUD_SonarActivationRequest 0 "No Request" 1 "Activation request" 2 "De-activation request" 3 "Reset request";
VAL_ 1772 HUD_ShiftActivationRequest 0 "No Request" 1 "Activation request" 2 "De-activation request" 3 "Reset request";
VAL_ 1772 CPDAcknowledgement 0 "No request" 1 "Activation Requested" 2 "Deactivation Requested" 3 "Delay Requested";
VAL_ 1772 CPDActivationRequest 0 "No Request" 1 "Temporary OFF request" 2 "CPD ON request" 3 "Not Used";
VAL_ 1772 OSE_ActivationRequest 0 "No request" 1 "Activation request" 2 "Deactivation request" 3 "Reset request";
VAL_ 1772 IntelD_SettingRequest 0 "No Request" 1 "Intel-D OFF request" 2 "Intel-D ON request" 3 "Reset request";
VAL_ 1772 ADTutorial_ActivationRequest 0 "No request" 1 "Activation request" 2 "Deactivation request" 3 "Reset request";
VAL_ 1772 TSRPredictive_ActivationRequest 0 "No request" 1 "TSR Predictive Deactivation Request" 2 "TSR Predictive Activation Request" 3 "Reset Request";
VAL_ 1772 GTLN_ActivationRequest 0 "No request" 1 "GTLN activation request" 2 "GTLN deactivation request" 3 "Reset request";
VAL_ 1772 ADASCD_AssistTypeRequest 0 "No request" 1 "ProPILOT Assist request" 2 "Cruise Control request" 3 "Reset request";
VAL_ 1772 CPD_tempActivationRequest 0 "No Request" 1 "ON Request" 2 "Temporary OFF Request" 3 "Reset Request";
VAL_ 1772 SET_ADL3_ChoiceRequest 0 "No request" 1 "OFF" 2 "ON" 3 "Reset request";
VAL_ 1772 SET_DMC_SensitivityRequest 0 "No request" 1 "Low sensitivity request" 2 "Middle sensitivity request" 3 "High sensitivity request" 4 "Not used" 5 "Not used" 6 "Not used" 7 "Reset request";
VAL_ 1772 HVBLow_DTE_Setting 0 "No request" 1 "10" 2 "15" 3 "20" 4 "25" 5 "30" 6 "35" 7 "40" 8 "45" 9 "50" 10 "55" 11 "60" 12 "65" 13 "70" 14 "75" 15 "80" 16 "85" 17 "90" 18 "95" 19 "100" 20 "105" 21 "110" 22 "115" 23 "120" 24 "125" 25 "130" 26 "135" 27 "140" 28 "145" 29 "150" 30 "OFF" 31 "Reset request";
VAL_ 1773 PSD_Left_BuzzerActivationStatus 0 "Power Slide Door Buzzer Inhibited" 1 "Power Slide Door Buzzer Authorized";
VAL_ 1776 AD_RouteAssist_Ack 0 "No Request" 1 "Yes" 2 "No" 3 "Do not show again" 4 "Do not suggest again" 5 "Not used" 6 "Not used" 7 "Not used";
VAL_ 1776 ASE_SoundvolumeRequest 0 "No request" 1 "Low" 2 "Medium" 3 "High" 4 "Not used" 5 "Not used" 6 "Not used" 7 "Reset request";
VAL_ 1776 SET_RouteAssist_Request 0 "No Request" 1 "OFF" 2 "ON" 3 "Reset Request";
VAL_ 1776 RouteConf_IVI_Ack 0 "No Request" 1 "Start Guide" 2 "Cancel" 3 "Not used";
VAL_ 1776 ASE_SoundActivationRequest 0 "No ASE_Sound_request" 1 "ASE_Sound_activation request" 2 "ASE_Sound_deactivation request" 3 "Reset request";
VAL_ 1789 VolumAlarmActivationState 0 "Unavailable" 1 "Intrusion Sensor Deactivated Ask On Exit" 2 "Intrusion Sensor Deactivated Once" 3 "Intrusion Sensor Activated" 4 "Intrusion Sensor Deactivated" 5 "Not used" 6 "Not used" 7 "Not used";
VAL_ 1789 VolumAlarmActivatedDisplay 0 "No Display Request" 1 "Display Request";
VAL_ 1789 VolumAlarmDisplayRequest 0 "No Display Request" 1 "Display Request";
VAL_ 1789 FunctionalLightingActivStatus 0 "Unavailable" 1 "Functional Light activated" 2 "Functional Light deactivated" 3 "Functional Light Auto";
VAL_ 1789 AmbientADLinkStatus 0 "AD LINK deactivated" 1 "AD LINK activated";
VAL_ 1789 HandleEjectionByApproach_State 0 "Handle ejection  by approach deactivated" 1 "Handle ejection  by approach activated" 2 "Not used" 3 "Unavailable";
VAL_ 1790 V2Li_OverheatFailureDisplay 0 "No display" 1 "V2L Inside sockets overheat";
VAL_ 1790 DriverSaveModeStatusDisplay 0 "No Display" 1 "E Save activated";
VAL_ 1790 PnCchargeStationCompatibility 0 "No Display" 1 "not compatible";
VAL_ 1790 OnePedalModeDisplayRequest2 0 "No display" 1 "OnePedal Stand By" 2 "OnePedal Mode Active ON" 3 "Not Used";
VAL_ 1790 OnePedalMessageDisplayRequest_V2 0 "No display" 1 "Limit Reason 1" 2 "OnePedal activated" 3 "OnePedal deactivated" 4 "OnePedal Stand By" 5 "Not Used" 6 "Not Used" 7 "Not Used";
VAL_ 1800 DTOOL_to_MID 0 "Table Value407700";
VAL_ 1832 MID_to_DTOOL 0 "Table Value407699";
VAL_ 2563507968 SIGMA_CDM 0 "Table Value16461";
VAL_ 2563507968 SIGMA_DTCCDM 0 "Table Value26862";
VAL_ 2563508007 SIGMA_eHBox 0 "Table Value430561";
VAL_ 2563508007 SIGMA_DTCeHBox 0 "Table Value430559";
VAL_ 2563508009 SIGMA_PSD_R 0 "Table Value153060";
VAL_ 2563508009 SIGMA_DTCPSD_R 0 "Table Value153056";
VAL_ 2563508019 SIGMA_PBD 0 "Table Value16399";
VAL_ 2563508019 SIGMA_DTCPBD 0 "Table Value26865";
VAL_ 2563508021 SIGMA_RADAR 0 "Table Value16466";
VAL_ 2563508021 SIGMA_DTCRADAR 0 "Table Value26884";
VAL_ 2563508022 SIGMA_PSCU 0 "Table Value16465";
VAL_ 2563508022 SIGMA_DTCPSCU 0 "Table Value26866";
VAL_ 2563508030 SIGMA_SRad_RL 0 "Table Value16470";
VAL_ 2563508030 SIGMA_DTCSRad_RL 0 "Table Value26868";
VAL_ 2563508035 SIGMA_eRDC_L 0 "Table Value252236";
VAL_ 2563508035 SIGMA_DTCeRDC_L 0 "Table Value252232";
VAL_ 2563508037 SIGMA_eRDC_R 0 "Table Value252238";
VAL_ 2563508037 SIGMA_DTCeRDC_R 0 "Table Value252233";
VAL_ 2563508042 SIGMA_ANC 0 "Table Value16458";
VAL_ 2563508042 SIGMA_DTCANC 0 "Table Value26859";
VAL_ 2563508064 SIGMA_VDC 0 "Table Value16380";
VAL_ 2563508064 SIGMA_DTCVDC 0 "Table Value26886";
VAL_ 2563508066 SIGMA_EPS 0 "Table Value16377";
VAL_ 2563508066 SIGMA_DTCEPS 0 "Table Value26879";
VAL_ 2563508067 SIGMA_METER 0 "Table Value16379";
VAL_ 2563508067 SIGMA_DTCMETER 0 "Table Value26883";
VAL_ 2563508068 SIGMA_HVAC 0 "Table Value28686";
VAL_ 2563508068 SIGMA_DTCHVAC 0 "Table Value28682";
VAL_ 2563508069 SIGMA_BCM 0 "Table Value16381";
VAL_ 2563508069 SIGMA_DTCBCM 0 "Table Value26877";
VAL_ 2563508071 SIGMA_IVI 0 "Table Value16383";
VAL_ 2563508071 SIGMA_DTCIVI 0 "Table Value26882";
VAL_ 2563508072 SIGMA_4WD 0 "Table Value28679";
VAL_ 2563508072 SIGMA_DTC4WD 0 "Table Value28678";
VAL_ 2563508077 SIGMA_USM 0 "Table Value16384";
VAL_ 2563508077 SIGMA_DTCUSM 0 "Table Value26885";
VAL_ 2563508078 SIGMA_SONAR 0 "Table Value28703";
VAL_ 2563508078 SIGMA_DTCSONAR 0 "Table Value28702";
VAL_ 2563508079 SIGMA_DSMU 0 "Table Value16462";
VAL_ 2563508079 SIGMA_DTCDSMU 0 "Table Value26863";
VAL_ 2563508082 SIGMA_ACU 0 "Table Value16374";
VAL_ 2563508082 SIGMA_DTCACU 0 "Table Value26874";
VAL_ 2563508089 SIGMA_PSD_L 0 "Table Value153059";
VAL_ 2563508089 SIGMA_DTCPSD_L 0 "Table Value153054";
VAL_ 2563508093 SIGMA_ADAS 0 "Table Value16457";
VAL_ 2563508093 SIGMA_DTCADAS 0 "Table Value26875";
VAL_ 2563508099 SIGMA_A_IVC 0 "Table Value16456";
VAL_ 2563508099 SIGMA_DTCA_IVC 0 "Table Value26858";
VAL_ 2563508108 SIGMA_INV_ME 0 "Table Value27356";
VAL_ 2563508108 SIGMA_DTCINV_ME 0 "Table Value27351";
VAL_ 2563508115 SIGMA_OBC_AC 0 "Table Value28687";
VAL_ 2563508115 SIGMA_DTCOBC_AC 0 "Table Value28683";
VAL_ 2563508122 SIGMA_HEVC 0 "Table Value27338";
VAL_ 2563508122 SIGMA_DTCHEVC 0 "Table Value27347";
VAL_ 2563508130 SIGMA_AUDIOamp 0 "Table Value16459";
VAL_ 2563508130 SIGMA_DTCAUDIOamp 0 "Table Value26860";
VAL_ 2563508133 SIGMA_HNS 0 "Table Value27353";
VAL_ 2563508133 SIGMA_DTCHNS 0 "Table Value27348";
VAL_ 2563508139 SIGMA_VKM 0 "Table Value252239";
VAL_ 2563508139 SIGMA_DTCVKM 0 "Table Value252234";
VAL_ 2563508153 SIGMA_HFM 0 "Table Value16382";
VAL_ 2563508153 SIGMA_DTCHFM 0 "Table Value26881";
VAL_ 2563508154 SIGMA_AVM 0 "Table Value27338";
VAL_ 2563508154 SIGMA_DTCAVM 0 "Table Value27343";
VAL_ 2563508157 SIGMA_SCU 0 "Table Value28688";
VAL_ 2563508157 SIGMA_DTCSCU 0 "Table Value28684";
VAL_ 2563508164 SIGMA_eShifter 0 "Table Value153058";
VAL_ 2563508164 SIGMA_DTCeShifter 0 "Table Value153055";
VAL_ 2563508181 SIGMA_SRad_RR 0 "Table Value16471";
VAL_ 2563508181 SIGMA_DTCSRad_RR 0 "Table Value26871";
VAL_ 2563508189 SIGMA_FrCamera 0 "Table Value16378";
VAL_ 2563508189 SIGMA_DTCFrCamera 0 "Table Value26880";
VAL_ 2563508200 SIGMA_ECM 0 "Table Value16376";
VAL_ 2563508200 SIGMA_DTCECM 0 "Table Value26878";
VAL_ 2563508201 SIGMA_ATCU 0 "Table Value16375";
VAL_ 2563508201 SIGMA_DTCATCU 0 "Table Value26876";
VAL_ 2563508205 SIGMA_BMS_HV 0 "Table Value27340";
VAL_ 2563508205 SIGMA_DTCBMS_HV 0 "Table Value27344";
VAL_ 2563508207 SIGMA_INV_HSG 0 "Table Value27355";
VAL_ 2563508207 SIGMA_DTCINV_HSG 0 "Table Value27350";
VAL_ 2563567883 SIGMA_BMS_12V 0 "Table Value16460";
VAL_ 2563567883 SIGMA_DTCBMS_12V 0 "Table Value26861";
VAL_ 2563567951 SIGMA_EPS_sub 0 "Table Value28685";
VAL_ 2563567951 SIGMA_DTCEPS_sub 0 "Table Value28681";
VAL_ 2563567958 SIGMA_eShiftAct 0 "Table Value153057";
VAL_ 2563567958 SIGMA_DTCeShiftAct 0 "Table Value153053";
VAL_ 2563567968 SIGMA_HUD 0 "Table Value27354";
VAL_ 2563567968 SIGMA_DTCHUD 0 "Table Value27349";
VAL_ 2563568024 SIGMA_HPCU 0 "Table Value55692";
VAL_ 2563568024 SIGMA_DTCHPCU 0 "Table Value55693";
VAL_ 2563568093 SIGMA_DCDC_HV 0 "Table Value28677";
VAL_ 2563568093 SIGMA_DTCDCDC_HV 0 "Table Value28680";
VAL_ 2563568098 SIGMA_EBA 0 "Table Value16463";
VAL_ 2563568098 SIGMA_DTCEBA 0 "Table Value26864";
VAL_ 2563568101 SIGMA_INV_RE 0 "Table Value27357";
VAL_ 2563568101 SIGMA_DTCINV_RE 0 "Table Value27352";
VAL_ 2563568130 SIGMA_AirSUSP 0 "Table Value359670";
VAL_ 2563568130 SIGMA_DTCAirSUSP 0 "Table Value359671";
VAL_ 2563568148 SIGMA_BSG 0 "Table Value27341";
VAL_ 2563568148 SIGMA_DTCBSG 0 "Table Value27345";
VAL_ 2563568163 SIGMA_SRad_FL 0 "Table Value16468";
VAL_ 2563568163 SIGMA_DTCSRad_FL 0 "Table Value26869";
VAL_ 2563568164 SIGMA_SRad_FR 0 "Table Value16469";
VAL_ 2563568164 SIGMA_DTCSRad_FR 0 "Table Value26870";
VAL_ 2563568201 SIGMA_STBW 0 "Table Value161590";
VAL_ 2563568201 SIGMA_DTCSTBW 0 "Table Value161588";
VAL_ 2563568233 SIGMA_DMC 0 "Table Value27342";
VAL_ 2563568233 SIGMA_DTCDMC 0 "Table Value27346";
VAL_ 2563568267 SIGMA_RSCU3R 0 "Table Value407697";
VAL_ 2563568267 SIGMA_DTCRSCU3R 0 "Table Value407696";
VAL_ 2563568288 SIGMA_BLM_RPK 0 "Table Value55679";
VAL_ 2563568288 SIGMA_DTCBLM_RPK 0 "Table Value55690";
VAL_ 2563568290 SIGMA_SCCM 0 "Table Value16467";
VAL_ 2563568290 SIGMA_DTCSCCM 0 "Table Value26867";
VAL_ 2563568300 SIGMA_RSCU2R 0 "Table Value359675";
VAL_ 2563568300 SIGMA_DTCRSCU2R 0 "Table Value359672";
VAL_ 2563639091 SIGMA_PBD_ReadMeReqRDIAG 0 "Table Value28694";
VAL_ 2609102849 DSMU_WakeUp_Signal 0 "Table Value16481";
VAL_ 2609102850 PSCU_WakeUp_Signal 0 "Table Value16487";
VAL_ 2609102851 SCCM_WakeUp_Signal 0 "Table Value16488";
VAL_ 2609102861 BCM_WakeUp_Signal 0 "Table Value16475";
VAL_ 2609102865 RSCU2R_WakeUp_Signal 0 "Table Value409772";
VAL_ 2609102868 RSCU3R_WakeUp_Signal 0 "Table Value409773";
VAL_ 2615038450 FTOOLS_CGWtoMETER 0 "Table Value16476";
VAL_ 2615079505 FTOOLS_METERtoCGW 0 "Table Value16477";
